VERSION "HIPBNNNYNNNNNNNNNNNNNNNNNNNNNNNNNNYYNNNNNN/4>%%%/4/'%**4NNN///"

NS_ :

BS_:

BU_: ADC CDC DDM VNC Vector_XXX

BO_ 802 AVN1SG4: 32 CDC
 SG_ TRNSW1 : 7|1@0+ (1,0) [0|0] "-"  ADC
 SG_ TRNSW2 : 6|1@0+ (1,0) [0|0] "-"  ADC
 SG_ TRNSW3 : 5|1@0+ (1,0) [0|0] "-"  ADC
 SG_ TRNSW4 : 4|1@0+ (1,0) [0|0] "-"  ADC
 SG_ TRNSW5 : 3|1@0+ (1,0) [0|0] "-"  ADC
 SG_ TRNSW6 : 2|1@0+ (1,0) [0|0] "-"  ADC
 SG_ TRNSW7 : 1|1@0+ (1,0) [0|0] "-"  ADC
 SG_ TRNSW8 : 0|1@0+ (1,0) [0|0] "-"  ADC
 SG_ TRNPASW : 15|1@0+ (1,0) [0|0] "-"  ADC
 SG_ AIPWFRP : 13|2@0+ (1,0) [0|0] "-"  ADC
 SG_ AIPFBID : 11|8@0+ (1,0) [0|0] "-"  ADC
 SG_ AIPFB : 19|3@0+ (1,0) [0|0] "-"  ADC
 SG_ AIPLID1 : 16|6@0+ (1,0) [0|0] "-"  ADC
 SG_ AIPL1 : 26|2@0+ (1,0) [0|0] "-"  ADC
 SG_ AIPLID2 : 24|6@0+ (1,0) [0|0] "-"  ADC
 SG_ AIPL2 : 34|2@0+ (1,0) [0|0] "-"  ADC
 SG_ AIPLID3 : 32|6@0+ (1,0) [0|0] "-"  ADC
 SG_ AIPL3 : 42|2@0+ (1,0) [0|0] "-"  ADC
 SG_ AIPLID4 : 40|6@0+ (1,0) [0|0] "-"  ADC
 SG_ AIPL4 : 50|2@0+ (1,0) [0|0] "-"  ADC
 SG_ AIPLID5 : 48|6@0+ (1,0) [0|0] "-"  ADC
 SG_ AIPL5 : 58|2@0+ (1,0) [0|0] "-"  ADC
 SG_ AIPLID6 : 56|6@0+ (1,0) [0|0] "-"  ADC
 SG_ AIPL6 : 66|2@0+ (1,0) [0|0] "-"  ADC
 SG_ AIPLID7 : 64|6@0+ (1,0) [0|0] "-"  ADC
 SG_ AIPL7 : 74|2@0+ (1,0) [0|0] "-"  ADC
 SG_ AIPLID8 : 72|6@0+ (1,0) [0|0] "-"  ADC
 SG_ AIPL8 : 82|2@0+ (1,0) [0|0] "-"  ADC
 SG_ AIPRLHE : 80|1@0+ (1,0) [0|0] "-"  ADC
 SG_ AIPRLAD : 95|3@0+ (1,0) [0|0] "-"  ADC
 SG_ AIPNORE : 92|3@0+ (1,0) [0|0] "-"  ADC
 SG_ TRNICN : 89|1@0+ (1,0) [0|0] "-"  ADC
 SG_ TRNECN : 88|1@0+ (1,0) [0|0] "-"  ADC

BO_ 321 AVN1SG7: 32 CDC
 SG_ BSDCTSW : 7|2@0+ (1,0) [0|0] "-"  ADC
 SG_ NPSSWOP : 5|1@0+ (1,0) [0|0] "-"  ADC
 SG_ HNPCSTSW : 4|2@0+ (1,0) [0|0] "-"  ADC
 SG_ UNPCSTSW : 2|2@0+ (1,0) [0|0] "-"  ADC
 SG_ MNPCSTSW : 0|2@0+ (1,0) [0|0] "-"  ADC
 SG_ NPLCCSSW : 14|2@0+ (1,0) [0|0] "-"  ADC
 SG_ NPCS1SW : 12|3@0+ (1,0) [0|0] "-"  ADC
 SG_ NPCS2SW : 9|2@0+ (1,0) [0|0] "-"  ADC
 SG_ NPCS3SW : 23|2@0+ (1,0) [0|0] "-"  ADC
 SG_ NPDSSWOP : 21|1@0+ (1,0) [0|0] "-"  ADC
 SG_ CPPSSWOP : 20|1@0+ (1,0) [0|0] "-"  ADC
 SG_ PNPSTRQ : 19|1@0+ (1,0) [0|0] "-"  ADC
 SG_ PNPPARQ : 18|1@0+ (1,0) [0|0] "-"  ADC
 SG_ PNPCTRQ : 17|1@0+ (1,0) [0|0] "-"  ADC
 SG_ PNPSPRQ : 16|1@0+ (1,0) [0|0] "-"  ADC
 SG_ APSW : 31|1@0+ (1,0) [0|0] "-"  ADC
 SG_ LPNPSTRQ : 30|1@0+ (1,0) [0|0] "-"  ADC
 SG_ LPNPPARQ : 29|1@0+ (1,0) [0|0] "-"  ADC
 SG_ LPNPCTRQ : 28|1@0+ (1,0) [0|0] "-"  ADC
 SG_ LPNPSPRQ : 27|1@0+ (1,0) [0|0] "-"  ADC
 SG_ OPKENBL : 26|1@0+ (1,0) [0|0] "-"  ADC
 SG_ LPLNENBL : 25|1@0+ (1,0) [0|0] "-"  ADC
 SG_ LPSPENBL : 24|1@0+ (1,0) [0|0] "-"  ADC
 SG_ PNPSENBL : 39|1@0+ (1,0) [0|0] "-"  ADC
 SG_ DIS2OBST : 38|3@0+ (1,0) [0|0] "-"  ADC
 SG_ SPDMD : 35|3@0+ (1,0) [0|0] "-"  ADC
 SG_ PKOFFSET : 32|2@0+ (1,0) [0|0] "-"  ADC
 SG_ RPAENBL : 46|2@0+ (1,0) [0|0] "-"  ADC
 SG_ PKMTHSET : 44|2@0+ (1,0) [0|0] "-"  ADC
 SG_ PKINDIR : 42|2@0+ (1,0) [0|0] "-"  ADC
 SG_ PKOSET : 40|8@0+ (1,0) [0|0] "-"  ADC
 SG_ LANGMD : 48|2@0+ (1,0) [0|0] "-"  ADC
 SG_ APENBL : 62|1@0+ (1,0) [0|0] "-"  ADC
 SG_ LPNPENBL : 61|1@0+ (1,0) [0|0] "-"  ADC
 SG_ PNPENBL : 60|1@0+ (1,0) [0|0] "-"  ADC
 SG_ APASTRQ : 59|1@0+ (1,0) [0|0] "-"  ADC
 SG_ APAPARQ : 58|1@0+ (1,0) [0|0] "-"  ADC
 SG_ APACTRQ : 57|1@0+ (1,0) [0|0] "-"  ADC
 SG_ APASPRQ : 56|1@0+ (1,0) [0|0] "-"  ADC
 SG_ RPASTRQ : 71|1@0+ (1,0) [0|0] "-"  ADC
 SG_ RPAPARQ : 70|1@0+ (1,0) [0|0] "-"  ADC
 SG_ RPACTRQ : 69|1@0+ (1,0) [0|0] "-"  ADC
 SG_ RPASPRQ : 68|1@0+ (1,0) [0|0] "-"  ADC
 SG_ APRCPMD : 67|1@0+ (1,0) [0|0] "-"  ADC
 SG_ APOUTDIR : 66|8@0+ (1,0) [0|0] "-"  ADC
 SG_ APINDIR : 74|8@0+ (1,0) [0|0] "-"  ADC
 SG_ LPBYRCP : 82|1@0+ (1,0) [0|0] "-"  ADC
 SG_ RAENBL : 81|8@0+ (1,0) [0|0] "-"  ADC
 SG_ LPINSTMD : 89|2@0+ (1,0) [0|0] "-"  ADC
 SG_ LPINRDMD : 103|1@0+ (1,0) [0|0] "-"  ADC
 SG_ LPBYPAD : 102|1@0+ (1,0) [0|0] "-"  ADC
 SG_ LPISSET : 101|1@0+ (1,0) [0|0] "-"  ADC
 SG_ LPOSSET : 100|1@0+ (1,0) [0|0] "-"  ADC
 SG_ LPENDSET : 99|1@0+ (1,0) [0|0] "-"  ADC
 SG_ LPRESET2 : 98|1@0+ (1,0) [0|0] "-"  ADC
 SG_ LPLNSTAT : 97|1@0+ (1,0) [0|0] "-"  ADC
 SG_ LPLNABT : 96|1@0+ (1,0) [0|0] "-"  ADC
 SG_ LPRTSET : 111|8@0+ (1,0) [0|0] "-"  ADC
 SG_ RASTRQ : 119|1@0+ (1,0) [0|0] "-"  ADC
 SG_ RAPARQ : 118|1@0+ (1,0) [0|0] "-"  ADC
 SG_ RACTRQ : 117|1@0+ (1,0) [0|0] "-"  ADC
 SG_ RASPRQ : 116|1@0+ (1,0) [0|0] "-"  ADC
 SG_ RASPEED : 115|2@0+ (1,0) [0|0] "-"  ADC
 SG_ WS_VISD : 113|2@0+ (1,0) [0|0] "-"  ADC
 SG_ WS_FTG : 127|2@0+ (1,0) [0|0] "-"  ADC
 SG_ WS_ABHB : 125|2@0+ (1,0) [0|0] "-"  ADC
 SG_ WS_APOS : 123|2@0+ (1,0) [0|0] "-"  ADC

BO_ 743 AVN1SG8: 32 CDC
 SG_ PSWPWC0 : 7|8@0+ (1,0) [0|0] "-"  DDM
 SG_ PSWPWC1 : 15|8@0+ (1,0) [0|0] "-"  DDM
 SG_ PSWPWC2 : 23|8@0+ (1,0) [0|0] "-"  DDM
 SG_ PSWPWC3 : 31|8@0+ (1,0) [0|0] "-"  DDM
 SG_ PSWPWC4 : 39|8@0+ (1,0) [0|0] "-"  DDM
 SG_ PSWPWC5 : 47|8@0+ (1,0) [0|0] "-"  DDM
 SG_ PSWPWC6 : 55|8@0+ (1,0) [0|0] "-"  DDM
 SG_ PSWPWC7 : 63|8@0+ (1,0) [0|0] "-"  DDM
 SG_ PSWPWC8 : 71|8@0+ (1,0) [0|0] "-"  DDM
 SG_ PSWPWC9 : 79|8@0+ (1,0) [0|0] "-"  DDM
 SG_ PSWPWC10 : 87|8@0+ (1,0) [0|0] "-"  DDM
 SG_ PSWPWC11 : 95|8@0+ (1,0) [0|0] "-"  DDM
 SG_ PSWPWC12 : 103|8@0+ (1,0) [0|0] "-"  DDM
 SG_ PSWPWC13 : 111|8@0+ (1,0) [0|0] "-"  DDM
 SG_ PSWPWC14 : 119|8@0+ (1,0) [0|0] "-"  DDM
 SG_ PSWPWC15 : 127|8@0+ (1,0) [0|0] "-"  DDM
 SG_ PSWPWC16 : 135|8@0+ (1,0) [0|0] "-"  DDM
 SG_ PSWPWC17 : 143|8@0+ (1,0) [0|0] "-"  DDM
 SG_ PSWPWC18 : 151|8@0+ (1,0) [0|0] "-"  DDM
 SG_ PSWPWC19 : 159|8@0+ (1,0) [0|0] "-"  DDM
 SG_ PSWPWC20 : 167|8@0+ (1,0) [0|0] "-"  DDM
 SG_ PSWPWC21 : 175|8@0+ (1,0) [0|0] "-"  DDM
 SG_ PSWPWC22 : 183|8@0+ (1,0) [0|0] "-"  DDM
 SG_ PSWPWC23 : 191|8@0+ (1,0) [0|0] "-"  DDM
 SG_ PSWPWC24 : 199|8@0+ (1,0) [0|0] "-"  DDM
 SG_ PSWPWC25 : 207|8@0+ (1,0) [0|0] "-"  DDM
 SG_ PSWPWC26 : 215|8@0+ (1,0) [0|0] "-"  DDM
 SG_ PSWPWC27 : 223|8@0+ (1,0) [0|0] "-"  DDM
 SG_ PSWPWC28 : 231|8@0+ (1,0) [0|0] "-"  DDM
 SG_ PSWPWC29 : 239|8@0+ (1,0) [0|0] "-"  DDM
 SG_ PSWPWC30 : 247|8@0+ (1,0) [0|0] "-"  DDM
 SG_ PSWPWC31 : 255|8@0+ (1,0) [0|0] "-"  DDM

BO_ 744 AVN1SG9: 32 CDC
 SG_ PSWPWC32 : 7|8@0+ (1,0) [0|0] "-"  DDM
 SG_ PSWPWC33 : 15|8@0+ (1,0) [0|0] "-"  DDM
 SG_ PSWPWC34 : 23|8@0+ (1,0) [0|0] "-"  DDM
 SG_ PSWPWC35 : 31|8@0+ (1,0) [0|0] "-"  DDM
 SG_ PSWPWC36 : 39|8@0+ (1,0) [0|0] "-"  DDM
 SG_ PSWPWC37 : 47|8@0+ (1,0) [0|0] "-"  DDM
 SG_ PSWPWC38 : 55|8@0+ (1,0) [0|0] "-"  DDM
 SG_ PSWPWC39 : 63|8@0+ (1,0) [0|0] "-"  DDM
 SG_ PSWPWC40 : 71|8@0+ (1,0) [0|0] "-"  DDM
 SG_ PSWPWC41 : 79|8@0+ (1,0) [0|0] "-"  DDM
 SG_ PSWPWC42 : 87|8@0+ (1,0) [0|0] "-"  DDM
 SG_ PSWPWC43 : 95|8@0+ (1,0) [0|0] "-"  DDM
 SG_ PSWPWC44 : 103|8@0+ (1,0) [0|0] "-"  DDM
 SG_ PSWPWC45 : 111|8@0+ (1,0) [0|0] "-"  DDM
 SG_ PSWPWC46 : 119|8@0+ (1,0) [0|0] "-"  DDM
 SG_ PSWPWC47 : 127|8@0+ (1,0) [0|0] "-"  DDM
 SG_ PSWPWC48 : 135|8@0+ (1,0) [0|0] "-"  DDM
 SG_ PSWPWC49 : 143|8@0+ (1,0) [0|0] "-"  DDM
 SG_ PSWPWC50 : 151|8@0+ (1,0) [0|0] "-"  DDM
 SG_ PSWPWC51 : 159|8@0+ (1,0) [0|0] "-"  DDM
 SG_ PSWPWC52 : 167|8@0+ (1,0) [0|0] "-"  DDM
 SG_ PSWPWC53 : 175|8@0+ (1,0) [0|0] "-"  DDM
 SG_ PSWPWC54 : 183|8@0+ (1,0) [0|0] "-"  DDM
 SG_ PSWPWC55 : 191|8@0+ (1,0) [0|0] "-"  DDM
 SG_ PSWPWC56 : 199|8@0+ (1,0) [0|0] "-"  DDM
 SG_ PSWPWC57 : 207|8@0+ (1,0) [0|0] "-"  DDM
 SG_ PSWPWC58 : 215|8@0+ (1,0) [0|0] "-"  DDM
 SG_ PSWPWC59 : 223|8@0+ (1,0) [0|0] "-"  DDM
 SG_ PSWPWC60 : 231|8@0+ (1,0) [0|0] "-"  DDM
 SG_ PSWPWC61 : 239|8@0+ (1,0) [0|0] "-"  DDM
 SG_ PSWPWC62 : 247|8@0+ (1,0) [0|0] "-"  DDM
 SG_ PSWPWC63 : 255|8@0+ (1,0) [0|0] "-"  DDM

BO_ 622 BAT1ED1: 32 DDM
 SG_ D_IB : 7|13@0- (0.366300366300366,0) [0|0] "A"  CDC
 SG_ D_VB : 10|13@0+ (0.1,0) [0|0] "V"  CDC
 SG_ D_VBMAX : 29|12@0+ (0.00122100122100122,0) [0|0] "V"  CDC
 SG_ D_VBMIN : 33|12@0+ (0.00122100122100122,0) [0|0] "V"  CDC
 SG_ D_VMAXN : 53|7@0+ (1,0) [0|0] "-"  CDC
 SG_ D_VMINN : 62|7@0+ (1,0) [0|0] "-"  CDC
 SG_ D_TBMAX : 71|8@0- (1,0) [0|0] "℃"  CDC
 SG_ D_TBMIN : 79|8@0- (1,0) [0|0] "℃"  CDC
 SG_ D_TBMAXN : 87|8@0+ (1,0) [0|0] "-"  CDC
 SG_ D_TBMINN : 95|8@0+ (1,0) [0|0] "-"  CDC
 SG_ D_SOC : 103|8@0+ (0.4,0) [0|0] "%"  CDC
 SG_ D_BATENE : 111|16@0+ (0.1,0) [0|0] "kWh"  CDC
 SG_ D_BERG1 : 135|8@0+ (1,0) [0|0] "-"  CDC
 SG_ D_BERG2 : 143|8@0+ (1,0) [0|0] "-"  CDC
 SG_ D_BERG3 : 151|8@0+ (1,0) [0|0] "-"  CDC
 SG_ D_BALM_1 : 159|8@0+ (1,0) [0|0] "-"  CDC
 SG_ D_BALM_2 : 167|8@0+ (1,0) [0|0] "-"  CDC
 SG_ D_BALM_3 : 175|8@0+ (1,0) [0|0] "-"  CDC
 SG_ D_BALM_4 : 183|8@0+ (1,0) [0|0] "-"  CDC
 SG_ D_BALM_5 : 191|8@0+ (1,0) [0|0] "-"  CDC
 SG_ D_BCODE1 : 199|8@0+ (1,0) [0|0] "-"  CDC
 SG_ D_BCODE2 : 207|8@0+ (1,0) [0|0] "-"  CDC
 SG_ D_BCODE3 : 215|8@0+ (1,0) [0|0] "-"  CDC
 SG_ D_BCODE4 : 223|8@0+ (1,0) [0|0] "-"  CDC
 SG_ D_BCODE5 : 231|8@0+ (1,0) [0|0] "-"  CDC
 SG_ D_BCODE6 : 239|8@0+ (1,0) [0|0] "-"  CDC
 SG_ D_BCODE7 : 247|8@0+ (1,0) [0|0] "-"  CDC
 SG_ D_BCODE8 : 255|8@0+ (1,0) [0|0] "-"  CDC

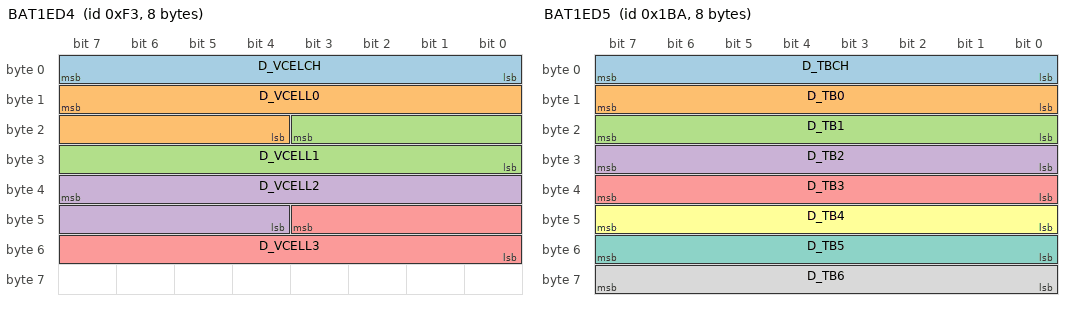
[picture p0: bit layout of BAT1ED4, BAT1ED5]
BO_ 243 BAT1ED4: 8 DDM
 SG_ D_VCELCH : 7|8@0+ (1,0) [0|0] "-"  CDC
 SG_ D_VCELL0 : 15|12@0+ (0.00122100122100122,0) [0|0] "V"  CDC
 SG_ D_VCELL1 : 19|12@0+ (0.00122100122100122,0) [0|0] "V"  CDC
 SG_ D_VCELL2 : 39|12@0+ (0.00122100122100122,0) [0|0] "V"  CDC
 SG_ D_VCELL3 : 43|12@0+ (0.00122100122100122,0) [0|0] "V"  CDC

BO_ 442 BAT1ED5: 8 DDM
 SG_ D_TBCH : 7|8@0+ (1,0) [0|0] "-"  CDC
 SG_ D_TB0 : 15|8@0- (1,0) [0|0] "℃"  CDC
 SG_ D_TB1 : 23|8@0- (1,0) [0|0] "℃"  CDC
 SG_ D_TB2 : 31|8@0- (1,0) [0|0] "℃"  CDC
 SG_ D_TB3 : 39|8@0- (1,0) [0|0] "℃"  CDC
 SG_ D_TB4 : 47|8@0- (1,0) [0|0] "℃"  CDC
 SG_ D_TB5 : 55|8@0- (1,0) [0|0] "℃"  CDC
 SG_ D_TB6 : 63|8@0- (1,0) [0|0] "℃"  CDC

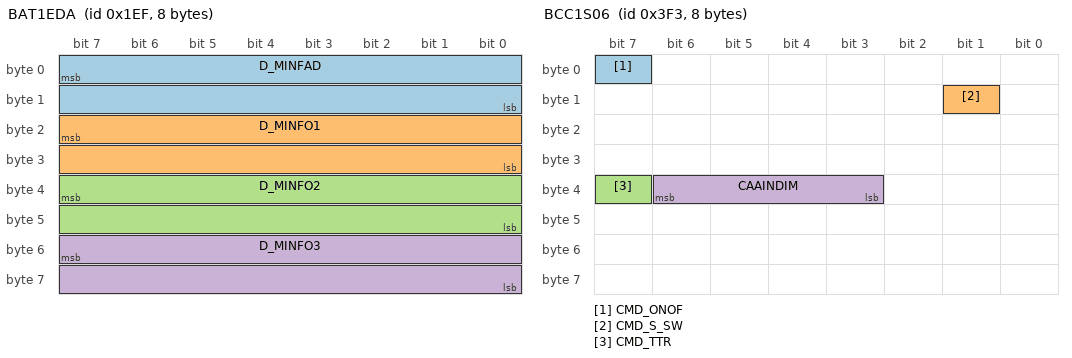
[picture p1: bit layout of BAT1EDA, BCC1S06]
BO_ 495 BAT1EDA: 8 DDM
 SG_ D_MINFAD : 7|16@0+ (1,0) [0|0] "-"  CDC
 SG_ D_MINFO1 : 23|16@0+ (1,0) [0|0] "-"  CDC
 SG_ D_MINFO2 : 39|16@0+ (1,0) [0|0] "-"  CDC
 SG_ D_MINFO3 : 55|16@0+ (1,0) [0|0] "-"  CDC

BO_ 626 BAT1EDB: 32 DDM
 SG_ D_BVIN1 : 7|8@0+ (1,0) [0|0] "-"  CDC
 SG_ D_BVIN2 : 15|8@0+ (1,0) [0|0] "-"  CDC
 SG_ D_BVIN3 : 23|8@0+ (1,0) [0|0] "-"  CDC
 SG_ D_BVIN4 : 31|8@0+ (1,0) [0|0] "-"  CDC
 SG_ D_BVIN5 : 39|8@0+ (1,0) [0|0] "-"  CDC
 SG_ D_BVIN6 : 47|8@0+ (1,0) [0|0] "-"  CDC
 SG_ D_BVIN7 : 55|8@0+ (1,0) [0|0] "-"  CDC
 SG_ D_BVIN8 : 63|8@0+ (1,0) [0|0] "-"  CDC
 SG_ D_BVIN9 : 71|8@0+ (1,0) [0|0] "-"  CDC
 SG_ D_BVIN10 : 79|8@0+ (1,0) [0|0] "-"  CDC
 SG_ D_BVIN11 : 87|8@0+ (1,0) [0|0] "-"  CDC
 SG_ D_BVIN12 : 95|8@0+ (1,0) [0|0] "-"  CDC
 SG_ D_BVIN13 : 103|8@0+ (1,0) [0|0] "-"  CDC
 SG_ D_BVIN14 : 111|8@0+ (1,0) [0|0] "-"  CDC
 SG_ D_BVIN15 : 119|8@0+ (1,0) [0|0] "-"  CDC
 SG_ D_BVIN16 : 127|8@0+ (1,0) [0|0] "-"  CDC
 SG_ D_BVIN17 : 135|8@0+ (1,0) [0|0] "-"  CDC
 SG_ D_BVIN18 : 143|8@0+ (1,0) [0|0] "-"  CDC
 SG_ D_BVIN19 : 151|8@0+ (1,0) [0|0] "-"  CDC
 SG_ D_BVIN20 : 159|8@0+ (1,0) [0|0] "-"  CDC
 SG_ D_BVIN21 : 167|8@0+ (1,0) [0|0] "-"  CDC
 SG_ D_BVIN22 : 175|8@0+ (1,0) [0|0] "-"  CDC
 SG_ D_BVIN23 : 183|8@0+ (1,0) [0|0] "-"  CDC
 SG_ D_BVIN24 : 191|8@0+ (1,0) [0|0] "-"  CDC

BO_ 633 BAT2ED2: 8 DDM
 SG_ BITGB1 : 7|1@0+ (1,0) [0|0] "-"  CDC
 SG_ BITGB2 : 6|1@0+ (1,0) [0|0] "-"  CDC
 SG_ BITGB3 : 5|1@0+ (1,0) [0|0] "-"  CDC
 SG_ BITGB4 : 4|1@0+ (1,0) [0|0] "-"  CDC
 SG_ STKNUM : 3|4@0+ (1,0) [0|0] "-"  CDC
 SG_ BITGB5 : 15|1@0+ (1,0) [0|0] "-"  CDC
 SG_ VCELNUM : 14|7@0+ (1,0) [0|0] "-"  CDC
 SG_ INFGB1 : 23|2@0+ (1,0) [0|0] "-"  CDC
 SG_ TMINNUM : 21|6@0+ (1,0) [0|0] "-"  CDC
 SG_ INFGB2 : 31|2@0+ (1,0) [0|0] "-"  CDC
 SG_ TMAXNUM : 29|6@0+ (1,0) [0|0] "-"  CDC
 SG_ VBTINF : 39|2@0+ (1,0) [0|0] "-"  CDC
 SG_ SOCINF : 37|2@0+ (1,0) [0|0] "-"  CDC
 SG_ IBTINF : 35|2@0+ (1,0) [0|0] "-"  CDC
 SG_ TBTINF : 33|2@0+ (1,0) [0|0] "-"  CDC
 SG_ STPSOC : 47|2@0+ (1,0) [0|0] "-"  CDC
 SG_ STPVB : 45|2@0+ (1,0) [0|0] "-"  CDC
 SG_ STPCELV : 43|2@0+ (1,0) [0|0] "-"  CDC
 SG_ STPTMP : 41|2@0+ (1,0) [0|0] "-"  CDC
 SG_ DATAGB2 : 55|8@0+ (1,0) [0|0] "-"  CDC
 SG_ DATAGB3 : 63|8@0+ (1,0) [0|0] "-"  CDC

BO_ 1011 BCC1S06: 8 ADC
 SG_ CMD_ONOF : 7|1@0+ (1,0) [0|0] "-"  CDC
 SG_ CMD_S_SW : 9|1@0+ (1,0) [0|0] "-"  CDC
 SG_ CMD_TTR : 39|1@0+ (1,0) [0|0] "-"  CDC
 SG_ CAAINDIM : 38|4@0+ (1,0) [0|0] "-"  CDC

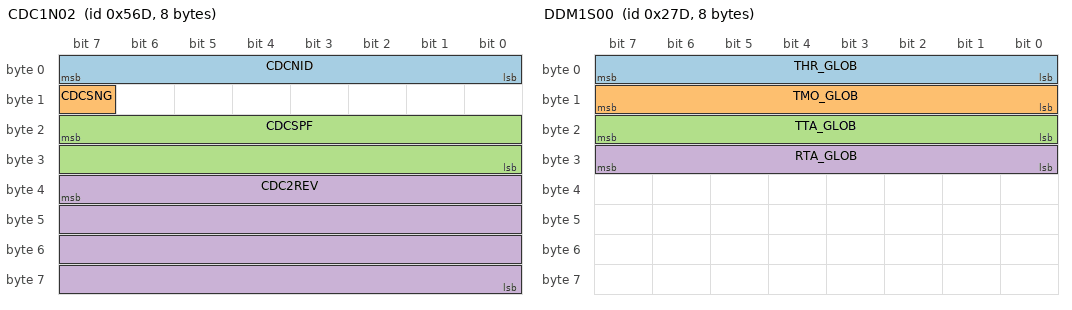
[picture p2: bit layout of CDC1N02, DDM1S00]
BO_ 1389 CDC1N02: 8 CDC
 SG_ CDCNID : 7|8@0+ (1,0) [0|0] "-"  Vector_XXX
 SG_ CDCSNG : 15|1@0+ (1,0) [0|0] "-"  Vector_XXX
 SG_ CDCSPF : 23|16@0+ (1,0) [0|0] "-"  Vector_XXX
 SG_ CDC2REV : 39|32@0+ (1,0) [0|0] "-"  Vector_XXX

BO_ 169 CSR1G10: 64 ADC
 SG_ APPMD : 31|3@0+ (1,0) [0|0] "-"  CDC
 SG_ APPEXIST : 28|1@0+ (1,0) [0|0] "-"  CDC
 SG_ APPSYS : 27|1@0+ (1,0) [0|0] "-"  CDC
 SG_ APPFAIL : 26|1@0+ (1,0) [0|0] "-"  CDC
 SG_ RCPEXBRK : 54|1@0+ (1,0) [0|0] "-"  CDC

BO_ 1082 CSR1S04: 8 ADC
 SG_ ICSEXIST : 7|1@0+ (1,0) [0|0] "-"  CDC
 SG_ ICSLAMP : 6|2@0+ (1,0) [0|0] "-"  CDC
 SG_ CS_S_SW3 : 4|1@0+ (1,0) [0|0] "-"  CDC
 SG_ CSSW : 3|1@0+ (1,0) [0|0] "-"  CDC
 SG_ ICSSW : 2|1@0+ (1,0) [0|0] "-"  CDC
 SG_ CS_V_SW3 : 1|1@0+ (1,0) [0|0] "-"  CDC
 SG_ ICS_S_SW : 0|1@0+ (1,0) [0|0] "-"  CDC
 SG_ ICSINFO : 15|16@0+ (1,0) [0|0] "-"  CDC
 SG_ WACS_BUZ : 27|1@0+ (1,0) [0|0] "-"  CDC
 SG_ WACSPMID : 24|1@0+ (1,0) [0|0] "-"  CDC
 SG_ VNUSGCSR : 32|1@0+ (1,0) [0|0] "-"  CDC
 SG_ PMARDISP : 46|2@0+ (1,0) [0|0] "-"  CDC
 SG_ PMARVNRQ : 44|2@0+ (1,0) [0|0] "-"  CDC
 SG_ PMARVNEX : 42|1@0+ (1,0) [0|0] "-"  CDC
 SG_ PMARST : 41|1@0+ (1,0) [0|0] "-"  CDC
 SG_ PMAREX : 40|1@0+ (1,0) [0|0] "-"  CDC
 SG_ VOT3 : 55|5@0+ (1,0) [0|0] "-"  CDC
 SG_ PMARAVBL : 48|1@0+ (1,0) [0|0] "-"  CDC

BO_ 987 CSR1S07: 8 ADC
 SG_ FR_POS : 7|3@0+ (1,0) [0|0] "-"  CDC
 SG_ FL_POS : 4|3@0+ (1,0) [0|0] "-"  CDC
 SG_ FR_WRN : 1|2@0+ (1,0) [0|0] "-"  CDC
 SG_ FRC_POS : 15|3@0+ (1,0) [0|0] "-"  CDC
 SG_ FLC_POS : 12|3@0+ (1,0) [0|0] "-"  CDC
 SG_ FL_WRN : 9|2@0+ (1,0) [0|0] "-"  CDC
 SG_ RR_POS : 23|3@0+ (1,0) [0|0] "-"  CDC
 SG_ RL_POS : 20|3@0+ (1,0) [0|0] "-"  CDC
 SG_ FRC_WRN : 17|2@0+ (1,0) [0|0] "-"  CDC
 SG_ RRC_POS : 31|3@0+ (1,0) [0|0] "-"  CDC
 SG_ RLC_POS : 28|3@0+ (1,0) [0|0] "-"  CDC
 SG_ FLC_WRN : 25|2@0+ (1,0) [0|0] "-"  CDC
 SG_ RR_WRN : 39|2@0+ (1,0) [0|0] "-"  CDC
 SG_ RL_WRN : 37|2@0+ (1,0) [0|0] "-"  CDC
 SG_ RRC_WRN : 35|2@0+ (1,0) [0|0] "-"  CDC
 SG_ RLC_WRN : 33|2@0+ (1,0) [0|0] "-"  CDC
 SG_ CSMUTESW : 47|2@0+ (1,0) [0|0] "-"  CDC
 SG_ CSRDISP1 : 45|1@0+ (1,0) [0|0] "-"  CDC
 SG_ CSRDISP3 : 43|1@0+ (1,0) [0|0] "-"  CDC
 SG_ CSR_VE3 : 55|1@0+ (1,0) [0|0] "-"  CDC
 SG_ CSDETSYM : 54|1@0+ (1,0) [0|0] "-"  CDC
 SG_ CSR_TTR : 59|1@0+ (1,0) [0|0] "-"  CDC
 SG_ CS_LAMP : 58|2@0+ (1,0) [0|0] "-"  CDC

BO_ 988 CSR1S08: 8 ADC
 SG_ FR_DIRT : 7|2@0+ (1,0) [0|0] "-"  CDC
 SG_ FL_DIRT : 5|2@0+ (1,0) [0|0] "-"  CDC
 SG_ FRC_DIRT : 3|2@0+ (1,0) [0|0] "-"  CDC
 SG_ FLC_DIRT : 1|2@0+ (1,0) [0|0] "-"  CDC
 SG_ RR_DIRT : 15|2@0+ (1,0) [0|0] "-"  CDC
 SG_ RL_DIRT : 13|2@0+ (1,0) [0|0] "-"  CDC
 SG_ RRC_DIRT : 11|2@0+ (1,0) [0|0] "-"  CDC
 SG_ RLC_DIRT : 9|2@0+ (1,0) [0|0] "-"  CDC
 SG_ FRS_DIRT : 23|2@0+ (1,0) [0|0] "-"  CDC
 SG_ FLS_DIRT : 21|2@0+ (1,0) [0|0] "-"  CDC
 SG_ RRS_DIRT : 19|2@0+ (1,0) [0|0] "-"  CDC
 SG_ RLS_DIRT : 17|2@0+ (1,0) [0|0] "-"  CDC
 SG_ CSR_INF1 : 31|1@0+ (1,0) [0|0] "-"  CDC
 SG_ CSR_INF2 : 30|1@0+ (1,0) [0|0] "-"  CDC
 SG_ PKSSINFO : 29|2@0+ (1,0) [0|0] "-"  CDC
 SG_ PKSS_VE : 37|1@0+ (1,0) [0|0] "-"  CDC
 SG_ RCDAVABL : 36|1@0+ (1,0) [0|0] "-"  CDC
 SG_ ICSAVABL : 35|1@0+ (1,0) [0|0] "-"  CDC
 SG_ CSRAVABL : 34|1@0+ (1,0) [0|0] "-"  CDC
 SG_ CAM_INF1 : 32|1@0+ (1,0) [0|0] "-"  CDC
 SG_ CSR_VOL : 46|3@0+ (1,0) [0|0] "-"  CDC
 SG_ CSR_BUZ : 43|4@0+ (1,0) [0|0] "-"  CDC

BO_ 637 DDM1S00: 8 DDM
 SG_ THR_GLOB : 7|8@0+ (1,-40) [0|0] "℃"  CDC
 SG_ TMO_GLOB : 15|8@0+ (1,-40) [0|0] "℃"  CDC
 SG_ TTA_GLOB : 23|8@0+ (1,-40) [0|0] "℃"  CDC
 SG_ RTA_GLOB : 31|8@0+ (1,-40) [0|0] "℃"  CDC

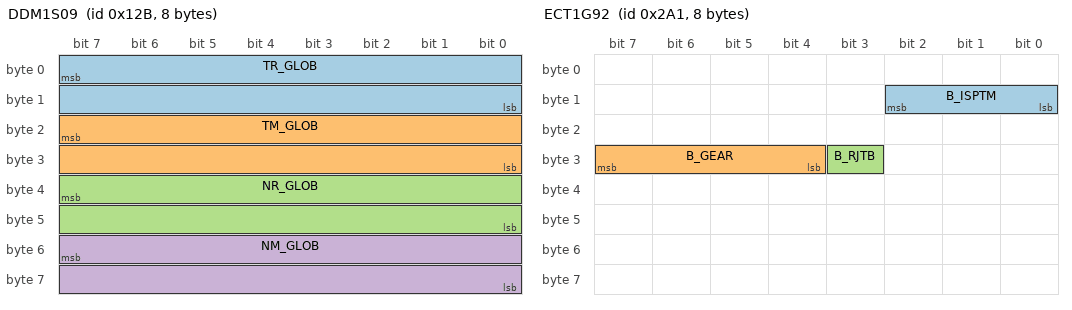
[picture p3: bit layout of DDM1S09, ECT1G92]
BO_ 299 DDM1S09: 8 DDM
 SG_ TR_GLOB : 7|16@0- (0.03125,0) [0|0] "Nm"  CDC
 SG_ TM_GLOB : 23|16@0- (0.03125,0) [0|0] "Nm"  CDC
 SG_ NR_GLOB : 39|16@0- (1,0) [0|0] "rpm"  CDC
 SG_ NM_GLOB : 55|16@0- (1,0) [0|0] "rpm"  CDC

BO_ 537 DDM1S32: 32 DDM
 SG_ C_GCMD1 : 31|5@0+ (1,0) [0|0] "-"  CDC
 SG_ C_GCMD2 : 39|5@0+ (1,0) [0|0] "-"  CDC
 SG_ C_GCMD3 : 47|5@0+ (1,0) [0|0] "-"  CDC
 SG_ C_GCMD4 : 55|5@0+ (1,0) [0|0] "-"  CDC
 SG_ C_GCMD5 : 63|5@0+ (1,0) [0|0] "-"  CDC
 SG_ C_GCMD6 : 71|5@0+ (1,0) [0|0] "-"  CDC
 SG_ C_GCMD7 : 79|5@0+ (1,0) [0|0] "-"  CDC
 SG_ C_GCMD8 : 87|5@0+ (1,0) [0|0] "-"  CDC
 SG_ GDPCEXT : 95|1@0+ (1,0) [0|0] "-"  CDC
 SG_ GDPCVLD : 94|1@0+ (1,0) [0|0] "-"  CDC
 SG_ BRKFRESH : 103|2@0+ (1,0) [0|0] "-"  CDC
 SG_ BDRSSWEX : 101|1@0+ (1,0) [0|0] "-"  CDC
 SG_ DDDBWHCN : 111|4@0+ (1,0) [0|0] "-"  CDC
 SG_ DDFRWHCN : 119|2@0+ (1,0) [0|0] "-"  CDC
 SG_ DDFLWHCN : 117|2@0+ (1,0) [0|0] "-"  CDC
 SG_ DDRRWHCN : 115|2@0+ (1,0) [0|0] "-"  CDC
 SG_ DDRLWHCN : 113|2@0+ (1,0) [0|0] "-"  CDC

BO_ 673 ECT1G92: 8 DDM
 SG_ B_ISPTM : 10|3@0+ (1,0) [0|0] "-"  CDC
 SG_ B_GEAR : 31|4@0+ (1,0) [0|0] "-"  CDC
 SG_ B_RJTB : 27|1@0+ (1,0) [0|0] "-"  CDC

BO_ 980 ECT1S80: 32 DDM
 SG_ SLCT : 14|1@0+ (1,0) [0|0] "-"  CDC

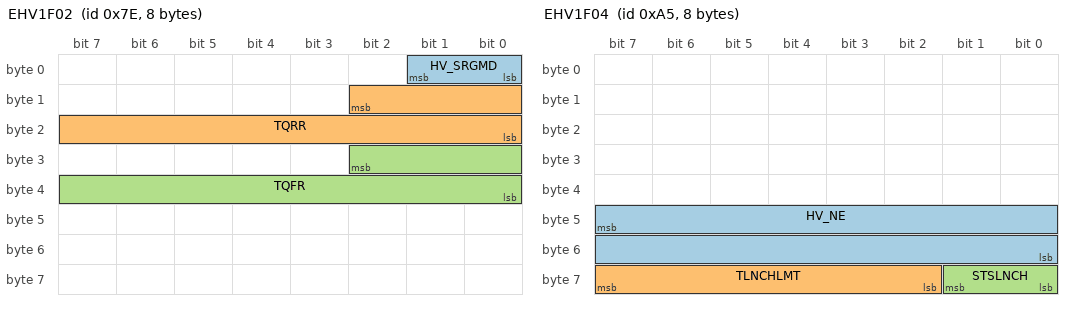
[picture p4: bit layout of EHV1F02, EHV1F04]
BO_ 126 EHV1F02: 8 DDM
 SG_ HV_SRGMD : 1|2@0+ (1,0) [0|0] "-"  CDC
 SG_ TQRR : 10|11@0- (8,0) [0|0] "Nm"  CDC
 SG_ TQFR : 26|11@0- (8,0) [0|0] "Nm"  CDC

BO_ 165 EHV1F04: 8 DDM
 SG_ HV_NE : 47|16@0- (0.78125,0) [0|0] "rpm"  CDC
 SG_ TLNCHLMT : 63|6@0+ (100,0) [0|0] "msec"  CDC
 SG_ STSLNCH : 57|2@0+ (1,0) [0|0] "-"  CDC

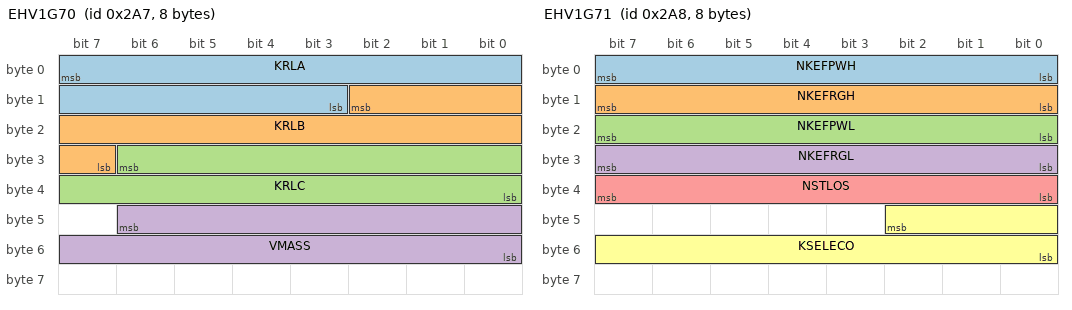
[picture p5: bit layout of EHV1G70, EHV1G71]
BO_ 679 EHV1G70: 8 DDM
 SG_ KRLA : 7|13@0+ (0.0001,0) [0|0] "N/[km/h]^2"  CDC
 SG_ KRLB : 10|12@0- (0.01,0) [0|0] "N/[km/h]"  CDC
 SG_ KRLC : 30|15@0+ (0.1,0) [0|0] "N"  CDC
 SG_ VMASS : 46|15@0+ (1,0) [0|0] "kg"  CDC

BO_ 680 EHV1G71: 8 DDM
 SG_ NKEFPWH : 7|8@0+ (1,0) [0|0] "%"  CDC
 SG_ NKEFRGH : 15|8@0+ (1,0) [0|0] "%"  CDC
 SG_ NKEFPWL : 23|8@0+ (1,0) [0|0] "%"  CDC
 SG_ NKEFRGL : 31|8@0+ (1,0) [0|0] "%"  CDC
 SG_ NSTLOS : 39|8@0+ (0.1,0) [0|0] "kw"  CDC
 SG_ KSELECO : 42|11@0+ (0.02,0) [0|0] "km/kWh"  CDC

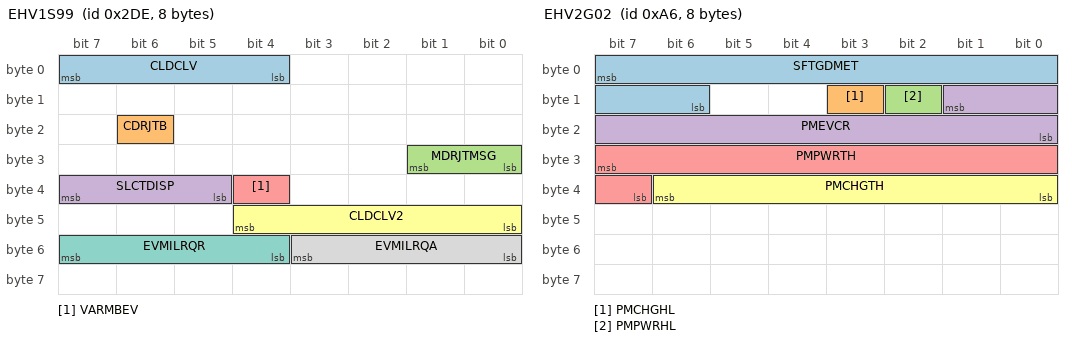
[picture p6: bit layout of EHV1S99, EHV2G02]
BO_ 734 EHV1S99: 8 DDM
 SG_ CLDCLV : 7|4@0+ (1,0) [0|0] "-"  CDC
 SG_ CDRJTB : 22|1@0+ (1,0) [0|0] "-"  CDC
 SG_ MDRJTMSG : 25|2@0+ (1,0) [0|0] "-"  CDC
 SG_ SLCTDISP : 39|3@0+ (1,0) [0|0] "-"  CDC
 SG_ VARMBEV : 36|1@0+ (1,0) [0|0] "-"  CDC
 SG_ CLDCLV2 : 44|5@0+ (1,0) [0|0] "-"  CDC
 SG_ EVMILRQR : 55|4@0+ (1,0) [0|0] "-"  CDC
 SG_ EVMILRQA : 51|4@0+ (1,0) [0|0] "-"  CDC

BO_ 166 EHV2G02: 8 DDM
 SG_ SFTGDMET : 7|10@0+ (0.1,0) [0|0] "-"  CDC
 SG_ PMCHGHL : 11|1@0+ (1,0) [0|0] "-"  CDC
 SG_ PMPWRHL : 10|1@0+ (1,0) [0|0] "-"  CDC
 SG_ PMEVCR : 9|10@0- (1,0) [0|0] "%"  CDC
 SG_ PMPWRTH : 31|9@0+ (1,0) [0|0] "%"  CDC
 SG_ PMCHGTH : 38|7@0+ (1,0) [0|0] "%"  CDC

BO_ 117 EHV2G10: 32 DDM
 SG_ SDRVRR : 26|11@0- (8,0) [0|0] "Nm"  CDC
 SG_ SDRVFR : 42|11@0- (8,0) [0|0] "Nm"  CDC

BO_ 161 EHV2G20: 32 DDM
 SG_ HVMRADRR : 39|16@0- (1,0) [0|0] "rpm"  CDC
 SG_ HVMRADFR : 55|16@0- (1,0) [0|0] "rpm"  CDC

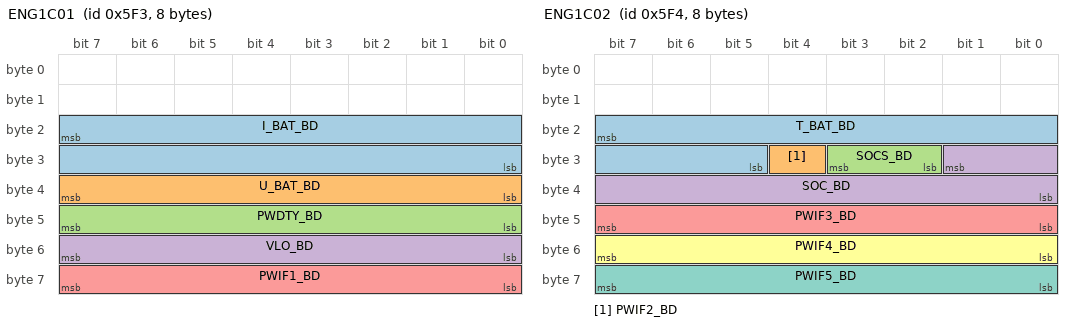
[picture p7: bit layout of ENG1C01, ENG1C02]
BO_ 1523 ENG1C01: 8 DDM
 SG_ I_BAT_BD : 23|16@0+ (0.030517578125,-1000) [0|0] "A"  CDC
 SG_ U_BAT_BD : 39|8@0+ (0.0390625,6) [0|0] "V"  CDC
 SG_ PWDTY_BD : 47|8@0+ (0.78125,0) [0|0] "%"  CDC
 SG_ VLO_BD : 55|8@0+ (0.0390625,10) [0|0] "V"  CDC
 SG_ PWIF1_BD : 63|8@0+ (1,0) [0|0] "-"  CDC

BO_ 1524 ENG1C02: 8 DDM
 SG_ T_BAT_BD : 23|11@0+ (0.1,-40) [0|0] "℃"  CDC
 SG_ PWIF2_BD : 28|1@0+ (1,0) [0|0] "-"  CDC
 SG_ SOCS_BD : 27|2@0+ (1,0) [0|0] "-"  CDC
 SG_ SOC_BD : 25|10@0+ (0.1,0) [0|0] "%"  CDC
 SG_ PWIF3_BD : 47|8@0+ (1,0) [0|0] "-"  CDC
 SG_ PWIF4_BD : 55|8@0+ (1,0) [0|0] "-"  CDC
 SG_ PWIF5_BD : 63|8@0+ (1,0) [0|0] "-"  CDC

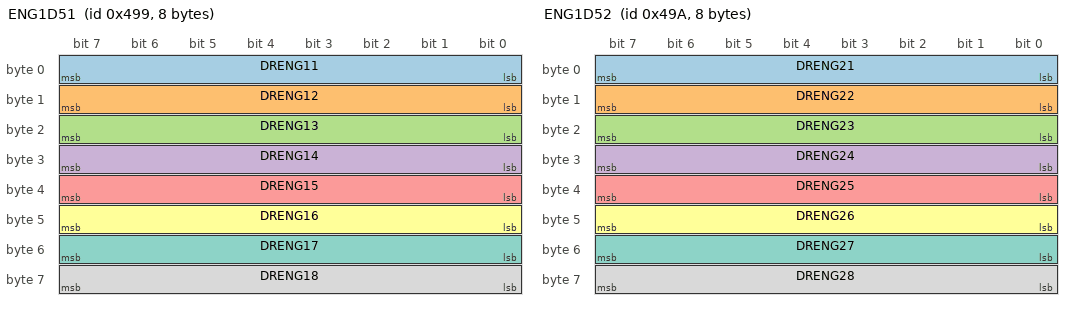
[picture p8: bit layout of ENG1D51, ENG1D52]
BO_ 1177 ENG1D51: 8 DDM
 SG_ DRENG11 : 7|8@0+ (1,0) [0|0] "-"  CDC
 SG_ DRENG12 : 15|8@0+ (1,0) [0|0] "-"  CDC
 SG_ DRENG13 : 23|8@0+ (1,0) [0|0] "-"  CDC
 SG_ DRENG14 : 31|8@0+ (1,0) [0|0] "-"  CDC
 SG_ DRENG15 : 39|8@0+ (1,0) [0|0] "-"  CDC
 SG_ DRENG16 : 47|8@0+ (1,0) [0|0] "-"  CDC
 SG_ DRENG17 : 55|8@0+ (1,0) [0|0] "-"  CDC
 SG_ DRENG18 : 63|8@0+ (1,0) [0|0] "-"  CDC

BO_ 1178 ENG1D52: 8 DDM
 SG_ DRENG21 : 7|8@0+ (1,0) [0|0] "-"  CDC
 SG_ DRENG22 : 15|8@0+ (1,0) [0|0] "-"  CDC
 SG_ DRENG23 : 23|8@0+ (1,0) [0|0] "-"  CDC
 SG_ DRENG24 : 31|8@0+ (1,0) [0|0] "-"  CDC
 SG_ DRENG25 : 39|8@0+ (1,0) [0|0] "-"  CDC
 SG_ DRENG26 : 47|8@0+ (1,0) [0|0] "-"  CDC
 SG_ DRENG27 : 55|8@0+ (1,0) [0|0] "-"  CDC
 SG_ DRENG28 : 63|8@0+ (1,0) [0|0] "-"  CDC

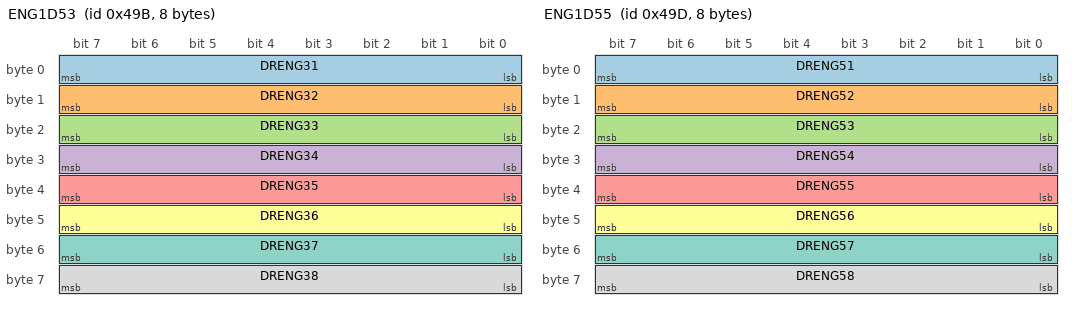
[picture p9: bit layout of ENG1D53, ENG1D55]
BO_ 1179 ENG1D53: 8 DDM
 SG_ DRENG31 : 7|8@0+ (1,0) [0|0] "-"  CDC
 SG_ DRENG32 : 15|8@0+ (1,0) [0|0] "-"  CDC
 SG_ DRENG33 : 23|8@0+ (1,0) [0|0] "-"  CDC
 SG_ DRENG34 : 31|8@0+ (1,0) [0|0] "-"  CDC
 SG_ DRENG35 : 39|8@0+ (1,0) [0|0] "-"  CDC
 SG_ DRENG36 : 47|8@0+ (1,0) [0|0] "-"  CDC
 SG_ DRENG37 : 55|8@0+ (1,0) [0|0] "-"  CDC
 SG_ DRENG38 : 63|8@0+ (1,0) [0|0] "-"  CDC

BO_ 1181 ENG1D55: 8 DDM
 SG_ DRENG51 : 7|8@0+ (1,0) [0|0] "-"  CDC
 SG_ DRENG52 : 15|8@0+ (1,0) [0|0] "-"  CDC
 SG_ DRENG53 : 23|8@0+ (1,0) [0|0] "-"  CDC
 SG_ DRENG54 : 31|8@0+ (1,0) [0|0] "-"  CDC
 SG_ DRENG55 : 39|8@0+ (1,0) [0|0] "-"  CDC
 SG_ DRENG56 : 47|8@0+ (1,0) [0|0] "-"  CDC
 SG_ DRENG57 : 55|8@0+ (1,0) [0|0] "-"  CDC
 SG_ DRENG58 : 63|8@0+ (1,0) [0|0] "-"  CDC

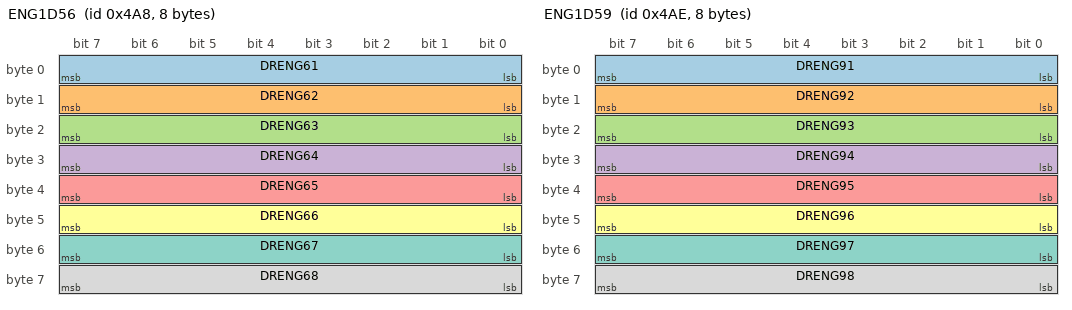
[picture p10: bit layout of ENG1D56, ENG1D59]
BO_ 1192 ENG1D56: 8 DDM
 SG_ DRENG61 : 7|8@0+ (1,0) [0|0] "-"  CDC
 SG_ DRENG62 : 15|8@0+ (1,0) [0|0] "-"  CDC
 SG_ DRENG63 : 23|8@0+ (1,0) [0|0] "-"  CDC
 SG_ DRENG64 : 31|8@0+ (1,0) [0|0] "-"  CDC
 SG_ DRENG65 : 39|8@0+ (1,0) [0|0] "-"  CDC
 SG_ DRENG66 : 47|8@0+ (1,0) [0|0] "-"  CDC
 SG_ DRENG67 : 55|8@0+ (1,0) [0|0] "-"  CDC
 SG_ DRENG68 : 63|8@0+ (1,0) [0|0] "-"  CDC

BO_ 1198 ENG1D59: 8 DDM
 SG_ DRENG91 : 7|8@0+ (1,0) [0|0] "-"  CDC
 SG_ DRENG92 : 15|8@0+ (1,0) [0|0] "-"  CDC
 SG_ DRENG93 : 23|8@0+ (1,0) [0|0] "-"  CDC
 SG_ DRENG94 : 31|8@0+ (1,0) [0|0] "-"  CDC
 SG_ DRENG95 : 39|8@0+ (1,0) [0|0] "-"  CDC
 SG_ DRENG96 : 47|8@0+ (1,0) [0|0] "-"  CDC
 SG_ DRENG97 : 55|8@0+ (1,0) [0|0] "-"  CDC
 SG_ DRENG98 : 63|8@0+ (1,0) [0|0] "-"  CDC

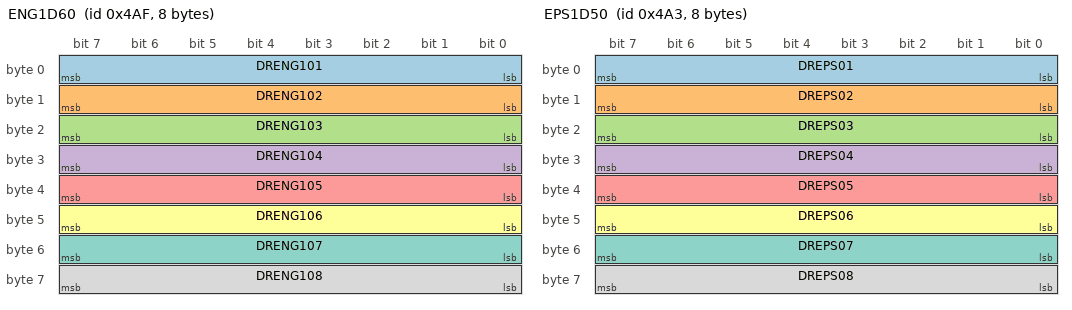
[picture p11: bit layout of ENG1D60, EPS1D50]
BO_ 1199 ENG1D60: 8 DDM
 SG_ DRENG101 : 7|8@0+ (1,0) [0|0] "-"  CDC
 SG_ DRENG102 : 15|8@0+ (1,0) [0|0] "-"  CDC
 SG_ DRENG103 : 23|8@0+ (1,0) [0|0] "-"  CDC
 SG_ DRENG104 : 31|8@0+ (1,0) [0|0] "-"  CDC
 SG_ DRENG105 : 39|8@0+ (1,0) [0|0] "-"  CDC
 SG_ DRENG106 : 47|8@0+ (1,0) [0|0] "-"  CDC
 SG_ DRENG107 : 55|8@0+ (1,0) [0|0] "-"  CDC
 SG_ DRENG108 : 63|8@0+ (1,0) [0|0] "-"  CDC

BO_ 163 ENG1G17: 8 DDM
 SG_ B_NEIND : 29|3@0+ (1,0) [0|0] "-"  CDC

BO_ 1417 ENG1S60: 32 DDM
 SG_ P_DCMOD1 : 7|1@0+ (1,0) [0|0] "-"  CDC
 SG_ P_DCMOD2 : 6|3@0+ (1,0) [0|0] "-"  CDC
 SG_ P_DCMOD3 : 3|4@0+ (1,0) [0|0] "-"  CDC
 SG_ RSCLVL : 11|2@0+ (1,0) [0|0] "-"  CDC
 SG_ P_DCMOD4 : 19|4@0+ (1,0) [0|0] "-"  CDC
 SG_ C_DCMOD1 : 31|1@0+ (1,0) [0|0] "-"  CDC
 SG_ C_DCMOD2 : 30|3@0+ (1,0) [0|0] "-"  CDC
 SG_ C_DCMOD3 : 27|4@0+ (1,0) [0|0] "-"  CDC
 SG_ C_DCMDE1 : 39|1@0+ (1,0) [0|0] "-"  CDC
 SG_ C_DCMDE2 : 38|3@0+ (1,0) [0|0] "-"  CDC
 SG_ C_DCMDE3 : 35|4@0+ (1,0) [0|0] "-"  CDC
 SG_ C_DMODEE : 47|4@0+ (1,0) [0|0] "-"  CDC
 SG_ C_DCMDS1 : 43|1@0+ (1,0) [0|0] "-"  CDC
 SG_ C_DCMDS2 : 42|3@0+ (1,0) [0|0] "-"  CDC
 SG_ C_DCMDS3 : 55|4@0+ (1,0) [0|0] "-"  CDC
 SG_ C_DMODES : 51|4@0+ (1,0) [0|0] "-"  CDC
 SG_ C_DCMDB1 : 63|1@0+ (1,0) [0|0] "-"  CDC
 SG_ C_DCMDB2 : 62|3@0+ (1,0) [0|0] "-"  CDC
 SG_ C_DCMDB3 : 59|4@0+ (1,0) [0|0] "-"  CDC
 SG_ C_DMODEB : 71|4@0+ (1,0) [0|0] "-"  CDC
 SG_ VSC_DCMD : 67|4@0+ (1,0) [0|0] "-"  CDC
 SG_ RSCEXIST : 73|1@0+ (1,0) [0|0] "-"  CDC
 SG_ DSCEXIST : 72|1@0+ (1,0) [0|0] "-"  CDC
 SG_ B_DMINF3 : 87|16@0+ (1,0) [0|0] "-"  CDC
 SG_ B_DMINF4 : 103|16@0+ (1,0) [0|0] "-"  CDC
 SG_ B_OMINF : 119|16@0+ (1,0) [0|0] "-"  CDC
 SG_ OMSSSWEX : 135|2@0+ (1,0) [0|0] "-"  CDC
 SG_ MT2SSWEX : 130|1@0+ (1,0) [0|0] "-"  CDC
 SG_ CRLSSWEX : 129|1@0+ (1,0) [0|0] "-"  CDC

BO_ 1411 ENG1S99: 8 DDM
 SG_ GRSMET_R : 0|1@0+ (1,0) [0|0] "-"  CDC

BO_ 1187 EPS1D50: 8 DDM
 SG_ DREPS01 : 7|8@0+ (1,0) [0|0] "-"  CDC
 SG_ DREPS02 : 15|8@0+ (1,0) [0|0] "-"  CDC
 SG_ DREPS03 : 23|8@0+ (1,0) [0|0] "-"  CDC
 SG_ DREPS04 : 31|8@0+ (1,0) [0|0] "-"  CDC
 SG_ DREPS05 : 39|8@0+ (1,0) [0|0] "-"  CDC
 SG_ DREPS06 : 47|8@0+ (1,0) [0|0] "-"  CDC
 SG_ DREPS07 : 55|8@0+ (1,0) [0|0] "-"  CDC
 SG_ DREPS08 : 63|8@0+ (1,0) [0|0] "-"  CDC

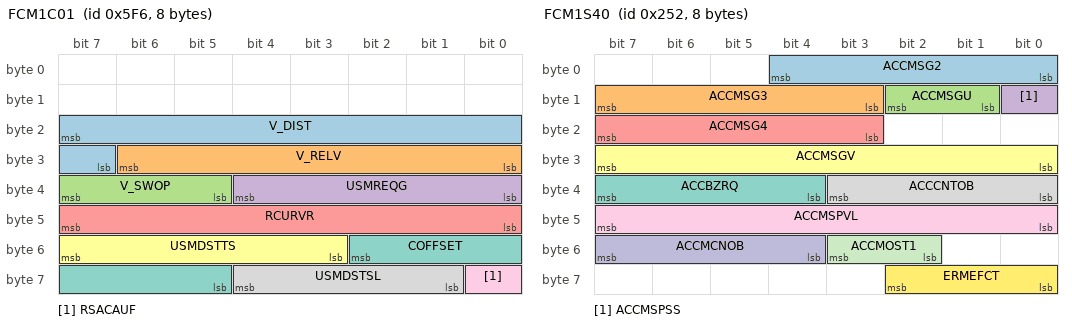
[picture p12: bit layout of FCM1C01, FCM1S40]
BO_ 1526 FCM1C01: 8 ADC
 SG_ V_DIST : 23|9@0+ (0.5,0) [0|0] "m"  CDC
 SG_ V_RELV : 30|7@0- (0.2,0) [0|0] "m/s"  CDC
 SG_ V_SWOP : 39|3@0+ (1,0) [0|0] "-"  CDC
 SG_ USMREQG : 36|5@0+ (0.1,-3.1) [0|0] "m/s^2"  CDC
 SG_ RCURVR : 47|8@0- (10,0) [0|0] "m"  CDC
 SG_ USMDSTTS : 55|5@0+ (5,0) [0|0] "m"  CDC
 SG_ COFFSET : 50|6@0- (0.03,0) [0|0] "m"  CDC
 SG_ USMDSTSL : 60|4@0+ (4,0) [0|0] "m"  CDC
 SG_ RSACAUF : 56|1@0+ (1,0) [0|0] "-"  CDC

BO_ 1521 FCM1C03: 32 ADC
 SG_ USMCNTST : 23|2@0+ (1,0) [0|0] "-"  CDC
 SG_ USMFUNC : 21|1@0+ (1,0) [0|0] "-"  CDC
 SG_ USMSENS : 20|2@0+ (1,0) [0|0] "-"  CDC
 SG_ USMACTFG : 18|1@0+ (1,0) [0|0] "-"  CDC
 SG_ USMTSTYP : 17|2@0+ (1,0) [0|0] "-"  CDC
 SG_ SGNOFFST : 31|8@0- (0.25,0) [0|0] "m"  CDC
 SG_ TSGNINF : 39|8@0+ (1,0) [0|0] "-"  CDC
 SG_ DLCAMSG : 47|4@0+ (1,0) [0|0] "-"  CDC
 SG_ RTYPE : 43|4@0+ (1,0) [0|0] "-"  CDC
 SG_ DLCAINDI : 55|3@0+ (1,0) [0|0] "-"  CDC
 SG_ RTYPERE : 52|2@0+ (1,0) [0|0] "-"  CDC
 SG_ V_BRKON : 50|1@0+ (1,0) [0|0] "-"  CDC
 SG_ RCLSINF : 63|6@0+ (1,0) [0|0] "-"  CDC
 SG_ PCSPREF2 : 57|1@0+ (1,0) [0|0] "-"  CDC
 SG_ PCSPREF1 : 56|1@0+ (1,0) [0|0] "-"  CDC
 SG_ CRU_STAT : 71|4@0+ (1,0) [0|0] "-"  CDC
 SG_ V_VMCC : 79|8@0+ (1,0) [0|0] "km/h"  CDC
 SG_ V_LTME : 84|3@0+ (1,0) [0|0] "-"  CDC
 SG_ V_LCCWOK : 81|1@0+ (1,0) [0|0] "-"  CDC
 SG_ V_XTGTCC : 80|1@0+ (1,0) [0|0] "-"  CDC
 SG_ V_RELA : 95|6@0- (0.4,0) [0|0] "m/s2"  CDC
 SG_ V_ACCUST : 89|2@0+ (1,0) [0|0] "-"  CDC
 SG_ USMTGTPV : 96|1@0+ (1,0) [0|0] "-"  CDC
 SG_ USMRCGTL : 111|3@0+ (1,0) [0|0] "-"  CDC
 SG_ V_LATPOS : 108|5@0- (0.4,0) [0|0] "m"  CDC
 SG_ V_ATACC : 119|6@0- (0.2,0) [0|0] "m/s^2"  CDC
 SG_ TSGNINF2 : 127|8@0+ (1,0) [0|0] "-"  CDC
 SG_ USMLTL : 135|1@0+ (1,0) [0|0] "-"  CDC
 SG_ USMSTL : 134|1@0+ (1,0) [0|0] "-"  CDC
 SG_ USMRTL : 133|1@0+ (1,0) [0|0] "-"  CDC
 SG_ V_IDAOPE : 132|4@0+ (1,0) [0|0] "-"  CDC
 SG_ LVNBUZDD : 138|1@0+ (1,0) [0|0] "-"  CDC
 SG_ LVNSTDD : 137|1@0+ (1,0) [0|0] "-"  CDC
 SG_ SUSUNABL : 151|8@0+ (1,0) [0|0] "-"  CDC
 SG_ APRCGSTS : 159|8@0+ (1,0) [0|0] "-"  CDC
 SG_ AP_FUNC : 164|5@0+ (1,0) [0|0] "-"  CDC
 SG_ POSX : 175|8@0- (0.1,0) [0|0] "m"  CDC
 SG_ POSZ : 183|7@0- (0.1,5) [0|0] "m"  CDC
 SG_ POSTHETA : 176|7@0- (1.5,90) [0|0] "deg"  CDC
 SG_ APSTS : 185|4@0+ (1,0) [0|0] "-"  CDC
 SG_ RODWDH : 197|6@0+ (0.2,0) [0|0] "m"  CDC
 SG_ FRNTGINF : 207|6@0+ (0.2,0) [0|0] "m"  CDC

BO_ 1161 FCM1S10: 32 ADC
 SG_ TSGN1 : 7|8@0+ (1,0) [0|0] "-"  CDC
 SG_ TSGNHLT1 : 9|2@0+ (1,0) [0|0] "-"  CDC
 SG_ SPDVAL1 : 23|8@0+ (1,0) [0|0] "-"  CDC
 SG_ SPLSGN1 : 31|4@0+ (1,0) [0|0] "-"  CDC
 SG_ SPLSGN2 : 27|4@0+ (1,0) [0|0] "-"  CDC
 SG_ TSGN2 : 39|8@0+ (1,0) [0|0] "-"  CDC
 SG_ TSGNHLT2 : 41|2@0+ (1,0) [0|0] "-"  CDC
 SG_ SPDVAL2 : 55|8@0+ (1,0) [0|0] "-"  CDC
 SG_ BZRRQ_A : 61|2@0+ (1,0) [0|0] "-"  CDC
 SG_ TSGN3 : 71|8@0+ (1,0) [0|0] "-"  CDC
 SG_ TSGNHLT3 : 73|2@0+ (1,0) [0|0] "-"  CDC
 SG_ WRNGWAYC : 87|2@0+ (1,0) [0|0] "-"  CDC
 SG_ SPLSGN3 : 95|4@0+ (1,0) [0|0] "-"  CDC
 SG_ SPLSGN4 : 91|4@0+ (1,0) [0|0] "-"  CDC
 SG_ TSGN4 : 103|8@0+ (1,0) [0|0] "-"  CDC
 SG_ SGNNUMH : 111|3@0+ (1,0) [0|0] "-"  CDC
 SG_ TSGNHLT4 : 105|2@0+ (1,0) [0|0] "-"  CDC
 SG_ SPBZRQ : 119|1@0+ (1,0) [0|0] "-"  CDC
 SG_ SGNNUMP : 117|3@0+ (1,0) [0|0] "-"  CDC
 SG_ SGNNUMA : 114|3@0+ (1,0) [0|0] "-"  CDC
 SG_ TLTASWAY : 133|2@0+ (1,0) [0|0] "-"  CDC
 SG_ TRSTINFO : 131|2@0+ (1,0) [0|0] "-"  CDC
 SG_ TLTASYST : 129|3@0+ (1,0) [0|0] "-"  CDC
 SG_ SPLSGN5 : 139|4@0+ (1,0) [0|0] "-"  CDC
 SG_ TSGNHLT5 : 151|2@0+ (1,0) [0|0] "-"  CDC
 SG_ TSGN5 : 159|8@0+ (1,0) [0|0] "-"  CDC
 SG_ CLTRLLEN : 191|4@0+ (1,0) [0|0] "-"  CDC

BO_ 1163 FCM1S12: 8 ADC
 SG_ TSREQPD : 7|1@0+ (1,0) [0|0] "-"  CDC
 SG_ TSRMSW : 6|1@0+ (1,0) [0|0] "-"  CDC
 SG_ OVSPNTM : 1|2@0+ (1,0) [0|0] "-"  CDC
 SG_ NOETYEXT : 15|1@0+ (1,0) [0|0] "-"  CDC
 SG_ NOEYNTM : 14|3@0+ (1,0) [0|0] "-"  CDC
 SG_ OVSPVALL : 11|4@0+ (1,-5) [0|0] "-"  CDC
 SG_ REDSGEXT : 23|1@0+ (1,0) [0|0] "-"  CDC
 SG_ RDSLNTM : 22|3@0+ (1,0) [0|0] "-"  CDC
 SG_ OVSPVALM : 19|4@0+ (1,-5) [0|0] "-"  CDC
 SG_ NTLVLSPD : 30|3@0+ (1,0) [0|0] "-"  CDC
 SG_ OVSPVALH : 27|4@0+ (1,-5) [0|0] "-"  CDC
 SG_ XSSPDEXT : 39|1@0+ (1,0) [0|0] "-"  CDC
 SG_ TSRSWEXT : 38|1@0+ (1,0) [0|0] "-"  CDC
 SG_ TSRSPU : 33|2@0+ (1,0) [0|0] "-"  CDC
 SG_ SPBZEXT : 44|1@0+ (1,0) [0|0] "-"  CDC
 SG_ RSACTIVE : 43|2@0+ (1,0) [0|0] "-"  CDC
 SG_ NTFLVEXT : 40|1@0+ (1,0) [0|0] "-"  CDC
 SG_ SPBZSTS : 55|1@0+ (1,0) [0|0] "-"  CDC

BO_ 594 FCM1S40: 8 ADC
 SG_ ACCMSG2 : 4|5@0+ (1,0) [0|0] "-"  CDC
 SG_ ACCMSG3 : 15|5@0+ (1,0) [0|0] "-"  CDC
 SG_ ACCMSGU : 10|2@0+ (1,0) [0|0] "-"  CDC
 SG_ ACCMSPSS : 8|1@0+ (1,0) [0|0] "-"  CDC
 SG_ ACCMSG4 : 23|5@0+ (1,0) [0|0] "-"  CDC
 SG_ ACCMSGV : 31|8@0+ (1,0) [0|0] "km/h・mph"  CDC
 SG_ ACCBZRQ : 39|4@0+ (1,0) [0|0] "-"  CDC
 SG_ ACCCNTOB : 35|4@0+ (1,0) [0|0] "-"  CDC
 SG_ ACCMSPVL : 47|8@0+ (1,0) [0|0] "-"  CDC
 SG_ ACCMCNOB : 55|4@0+ (1,0) [0|0] "-"  CDC
 SG_ ACCMOST1 : 51|2@0+ (1,0) [0|0] "-"  CDC
 SG_ ERMEFCT : 58|3@0+ (1,0) [0|0] "-"  CDC

BO_ 609 FCM1S41: 8 ADC
 SG_ ACCSSOD : 7|6@0- (1,0) [0|0] "km/h or mph"  CDC
 SG_ ISAEX : 0|1@0+ (1,0) [0|0] "-"  CDC
 SG_ ACCRACEX : 15|1@0+ (1,0) [0|0] "-"  CDC
 SG_ ACCRACD : 14|1@0+ (1,0) [0|0] "-"  CDC
 SG_ ACCROSEX : 11|1@0+ (1,0) [0|0] "-"  CDC
 SG_ ACCROSD : 10|1@0+ (1,0) [0|0] "-"  CDC
 SG_ ACCACLD : 20|2@0+ (1,0) [0|0] "-"  CDC
 SG_ ACCSPEX : 18|1@0+ (1,0) [0|0] "-"  CDC
 SG_ ACCSPD : 17|2@0+ (1,0) [0|0] "-"  CDC
 SG_ ACCRSAC : 39|1@0+ (1,0) [0|0] "-"  CDC
 SG_ ACCRSACB : 38|1@0+ (1,0) [0|0] "-"  CDC
 SG_ ACCSSAG : 37|2@0+ (1,0) [0|0] "-"  CDC
 SG_ ACCSSAGB : 35|1@0+ (1,0) [0|0] "-"  CDC
 SG_ VIDEO_OK : 34|1@0+ (1,0) [0|0] "-"  CDC
 SG_ CCSMDSTA : 33|1@0+ (1,0) [0|0] "-"  CDC
 SG_ CCSMDEXT : 32|1@0+ (1,0) [0|0] "-"  CDC
 SG_ SLSSOD : 47|6@0- (1,0) [0|0] "km/h or mph"  CDC
 SG_ SLSSOEX : 41|1@0+ (1,0) [0|0] "-"  CDC
 SG_ ERMEX : 40|1@0+ (1,0) [0|0] "-"  CDC
 SG_ ACCGCRD : 55|1@0+ (1,0) [0|0] "-"  CDC
 SG_ ACCGCREX : 54|1@0+ (1,0) [0|0] "-"  CDC
 SG_ ERMLV : 49|2@0+ (1,0) [0|0] "Lv"  CDC
 SG_ AECOEX : 63|1@0+ (1,0) [0|0] "-"  CDC
 SG_ AECOLV : 62|2@0+ (1,0) [0|0] "-"  CDC
 SG_ SLDSEX : 60|1@0+ (1,0) [0|0] "-"  CDC
 SG_ SLDSD : 59|1@0+ (1,0) [0|0] "-"  CDC
 SG_ SLSSSEX : 58|1@0+ (1,0) [0|0] "-"  CDC
 SG_ SLSSSD : 57|2@0+ (1,0) [0|0] "-"  CDC

BO_ 628 FCM1S49: 32 ADC
 SG_ OTHVW : 31|6@0+ (0.05,0) [0|0] "m"  CDC,DDM
 SG_ OTHVH : 39|7@0+ (0.05,0) [0|0] "m"  CDC,DDM
 SG_ OTHPB : 44|1@0+ (1,0) [0|0] "-"  CDC,DDM
 SG_ OTHTTC : 55|12@0+ (1,0) [0|0] "ms"  CDC,DDM
 SG_ OTHTTYP : 79|5@0+ (1,0) [0|0] "-"  CDC,DDM
 SG_ HITPOS : 116|5@0+ (1,0) [0|0] "-"  CDC,DDM
 SG_ OTHRDANG : 127|9@0- (1,0) [0|0] "deg"  CDC,DDM
 SG_ OTHOVLPC : 211|7@0+ (1,0) [0|0] "%"  CDC,DDM
 SG_ OTHRVPC : 220|11@0+ (0.1,-185) [0|0] "km/h"  CDC,DDM

BO_ 629 FCM1S51: 32 ADC
 SG_ IDADSPL : 7|4@0+ (1,0) [0|0] "-"  CDC
 SG_ IDAEXIST : 3|1@0+ (1,0) [0|0] "-"  CDC
 SG_ IDASENST : 2|2@0+ (1,0) [0|0] "-"  CDC
 SG_ IDAONST : 0|1@0+ (1,0) [0|0] "-"  CDC
 SG_ IDADSPR : 14|4@0+ (1,0) [0|0] "-"  CDC
 SG_ IDADSPC : 10|3@0+ (1,0) [0|0] "-"  CDC
 SG_ IDABUZZ : 23|2@0+ (1,0) [0|0] "-"  CDC
 SG_ IDACAN : 21|2@0+ (1,0) [0|0] "-"  CDC
 SG_ DWREQ : 37|2@0+ (1,0) [0|0] "-"  CDC
 SG_ USMDSPPV : 35|2@0+ (1,0) [0|0] "-"  CDC
 SG_ USMDSPTL : 32|3@0+ (1,0) [0|0] "-"  CDC
 SG_ USMDSPCR : 43|1@0+ (1,0) [0|0] "-"  CDC
 SG_ USMBZ : 50|3@0+ (1,0) [0|0] "-"  CDC
 SG_ USMDSPRM : 60|1@0+ (1,0) [0|0] "-"  CDC
 SG_ USMDSPTG : 71|4@0+ (1,0) [0|0] "-"  CDC

BO_ 630 FCM1S52: 8 ADC
 SG_ FCMDUST : 7|1@0+ (1,0) [0|0] "-"  CDC,DDM
 SG_ FCMTEMP : 6|1@0+ (1,0) [0|0] "-"  CDC,DDM
 SG_ FRDDUST : 5|1@0+ (1,0) [0|0] "-"  CDC,DDM
 SG_ FRDTEMP : 4|1@0+ (1,0) [0|0] "-"  CDC,DDM
 SG_ FRDTUCT : 3|1@0+ (1,0) [0|0] "-"  CDC,DDM
 SG_ TSSMALF : 2|1@0+ (1,0) [0|0] "-"  CDC,DDM
 SG_ TSSTUNA : 1|1@0+ (1,0) [0|0] "-"  CDC,DDM
 SG_ PCSAVABL : 0|1@0+ (1,0) [0|0] "-"  CDC,DDM
 SG_ ACCAVABL : 15|1@0+ (1,0) [0|0] "-"  CDC,DDM
 SG_ LTAAVABL : 14|1@0+ (1,0) [0|0] "-"  CDC,DDM
 SG_ LCAAVABL : 13|1@0+ (1,0) [0|0] "-"  CDC,DDM
 SG_ EDSSVABL : 12|1@0+ (1,0) [0|0] "-"  CDC,DDM
 SG_ RSAAVABL : 11|1@0+ (1,0) [0|0] "-"  CDC,DDM
 SG_ AHBAVABL : 10|1@0+ (1,0) [0|0] "-"  CDC,DDM
 SG_ IDAAVABL : 8|1@0+ (1,0) [0|0] "-"  CDC,DDM
 SG_ ACCERMEX : 23|1@0+ (1,0) [0|0] "-"  CDC,DDM
 SG_ TJAAVABL : 22|1@0+ (1,0) [0|0] "-"  CDC,DDM
 SG_ ERMAVABL : 21|1@0+ (1,0) [0|0] "-"  CDC,DDM
 SG_ EDSSEXST : 20|1@0+ (1,0) [0|0] "-"  CDC,DDM
 SG_ TMAVABL : 19|1@0+ (1,0) [0|0] "-"  CDC,DDM
 SG_ FCTAAVBL : 17|1@0+ (1,0) [0|0] "-"  CDC,DDM
 SG_ AHBEXIST : 16|1@0+ (1,0) [0|0] "-"  CDC,DDM
 SG_ ADU_INF3 : 29|1@0+ (1,0) [0|0] "-"  CDC,DDM
 SG_ CCAVABL : 28|1@0+ (1,0) [0|0] "-"  CDC,DDM
 SG_ CCEX : 27|1@0+ (1,0) [0|0] "-"  CDC,DDM
 SG_ ADU_INF4 : 26|1@0+ (1,0) [0|0] "-"  CDC,DDM
 SG_ ADUTUNA : 39|1@0+ (1,0) [0|0] "-"  CDC,DDM
 SG_ TMNAVABL : 38|1@0+ (1,0) [0|0] "-"  CDC,DDM
 SG_ ISAAVABL : 37|1@0+ (1,0) [0|0] "-"  CDC,DDM
 SG_ LDAAVABL : 36|1@0+ (1,0) [0|0] "-"  CDC,DDM
 SG_ USMDSE : 34|3@0+ (1,0) [0|0] "-"  CDC,DDM
 SG_ USMSW : 47|2@0+ (1,0) [0|0] "-"  CDC,DDM
 SG_ ADU_INF1 : 45|1@0+ (1,0) [0|0] "-"  CDC,DDM
 SG_ ADU_INF2 : 55|1@0+ (1,0) [0|0] "-"  CDC,DDM
 SG_ USMONST : 54|1@0+ (1,0) [0|0] "-"  CDC,DDM
 SG_ USMEXIST : 53|1@0+ (1,0) [0|0] "-"  CDC,DDM
 SG_ SDGCONT : 52|1@0+ (1,0) [0|0] "-"  CDC,DDM
 SG_ SDGONST : 51|1@0+ (1,0) [0|0] "-"  CDC,DDM
 SG_ SDGEXIST : 50|1@0+ (1,0) [0|0] "-"  CDC,DDM
 SG_ PDAONST : 49|1@0+ (1,0) [0|0] "-"  CDC,DDM
 SG_ PDAEXIST : 48|1@0+ (1,0) [0|0] "-"  CDC,DDM
 SG_ SWSAVABL : 63|1@0+ (1,0) [0|0] "-"  CDC,DDM
 SG_ DMCAVABL : 62|1@0+ (1,0) [0|0] "-"  CDC,DDM
 SG_ DMCEXIST : 61|1@0+ (1,0) [0|0] "-"  CDC,DDM
 SG_ BSDAVABL : 60|1@0+ (1,0) [0|0] "-"  CDC,DDM
 SG_ RCTAAVBL : 59|1@0+ (1,0) [0|0] "-"  CDC,DDM
 SG_ FHLAVABL : 58|1@0+ (1,0) [0|0] "-"  CDC,DDM
 SG_ SEAAVABL : 57|1@0+ (1,0) [0|0] "-"  CDC,DDM
 SG_ ADDSAVBL : 56|1@0+ (1,0) [0|0] "-"  CDC,DDM

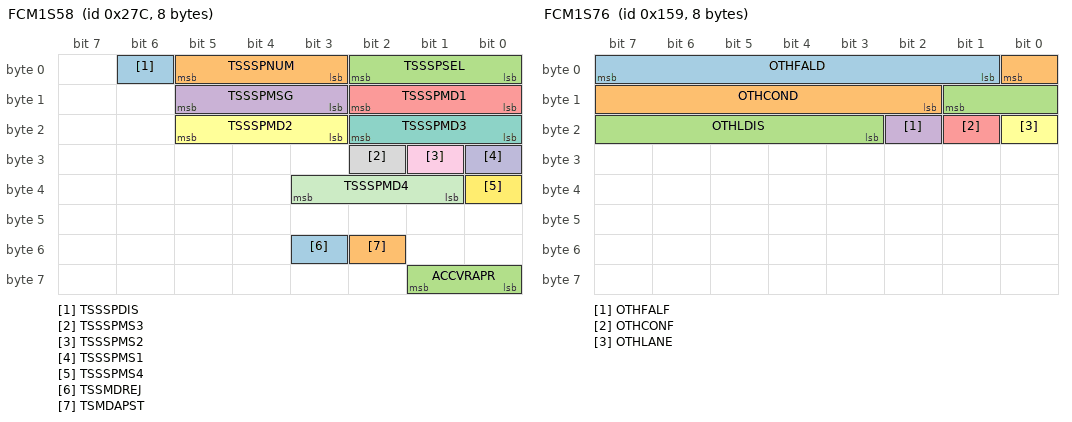
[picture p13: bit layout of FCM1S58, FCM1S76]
BO_ 636 FCM1S58: 8 ADC
 SG_ TSSSPDIS : 6|1@0+ (1,0) [0|0] "-"  CDC
 SG_ TSSSPNUM : 5|3@0+ (1,0) [0|0] "-"  CDC
 SG_ TSSSPSEL : 2|3@0+ (1,0) [0|0] "-"  CDC
 SG_ TSSSPMSG : 13|3@0+ (1,0) [0|0] "-"  CDC
 SG_ TSSSPMD1 : 10|3@0+ (1,0) [0|0] "-"  CDC
 SG_ TSSSPMD2 : 21|3@0+ (1,0) [0|0] "-"  CDC
 SG_ TSSSPMD3 : 18|3@0+ (1,0) [0|0] "-"  CDC
 SG_ TSSSPMS3 : 26|1@0+ (1,0) [0|0] "-"  CDC
 SG_ TSSSPMS2 : 25|1@0+ (1,0) [0|0] "-"  CDC
 SG_ TSSSPMS1 : 24|1@0+ (1,0) [0|0] "-"  CDC
 SG_ TSSSPMD4 : 35|3@0+ (1,0) [0|0] "-"  CDC
 SG_ TSSSPMS4 : 32|1@0+ (1,0) [0|0] "-"  CDC
 SG_ TSSMDREJ : 51|1@0+ (1,0) [0|0] "-"  CDC
 SG_ TSMDAPST : 50|1@0+ (1,0) [0|0] "-"  CDC
 SG_ ACCVRAPR : 57|2@0+ (1,0) [0|0] "-"  CDC

BO_ 650 FCM1S66: 32 ADC
 SG_ TSS_TID : 7|8@0+ (1,0) [0|0] "-"  CDC
 SG_ TSSFNC11 : 15|8@0+ (1,0) [0|0] "-"  CDC
 SG_ TSSFNC12 : 23|8@0+ (1,0) [0|0] "-"  CDC
 SG_ TSSFNC13 : 31|8@0+ (1,0) [0|0] "-"  CDC
 SG_ TSSFNC14 : 39|8@0+ (1,0) [0|0] "-"  CDC
 SG_ TSSFNC15 : 47|8@0+ (1,0) [0|0] "-"  CDC
 SG_ TSSFNC16 : 55|8@0+ (1,0) [0|0] "-"  CDC
 SG_ TSSFNC17 : 63|8@0+ (1,0) [0|0] "-"  CDC
 SG_ TSSFNC21 : 71|8@0+ (1,0) [0|0] "-"  CDC
 SG_ TSSFNC22 : 79|8@0+ (1,0) [0|0] "-"  CDC
 SG_ TSSFNC23 : 87|8@0+ (1,0) [0|0] "-"  CDC
 SG_ TSSFNC24 : 95|8@0+ (1,0) [0|0] "-"  CDC
 SG_ TSSFNC25 : 103|8@0+ (1,0) [0|0] "-"  CDC
 SG_ TSSFNC26 : 111|8@0+ (1,0) [0|0] "-"  CDC
 SG_ TSSFNC27 : 119|8@0+ (1,0) [0|0] "-"  CDC
 SG_ TSSFNC28 : 127|8@0+ (1,0) [0|0] "-"  CDC
 SG_ TSSVRRES : 135|8@0+ (1,0) [0|0] "-"  CDC
 SG_ TSSOPE11 : 143|8@0+ (1,0) [0|0] "-"  CDC
 SG_ TSSOPE12 : 151|8@0+ (1,0) [0|0] "-"  CDC
 SG_ TSSOPE13 : 159|8@0+ (1,0) [0|0] "-"  CDC
 SG_ TSSOPE14 : 167|8@0+ (1,0) [0|0] "-"  CDC
 SG_ TSSOPE15 : 175|8@0+ (1,0) [0|0] "-"  CDC
 SG_ TSSOPE16 : 183|8@0+ (1,0) [0|0] "-"  CDC
 SG_ TSSOPE17 : 191|8@0+ (1,0) [0|0] "-"  CDC
 SG_ TSSOPE21 : 199|8@0+ (1,0) [0|0] "-"  CDC
 SG_ TSSOPE22 : 207|8@0+ (1,0) [0|0] "-"  CDC
 SG_ TSSOPE23 : 215|8@0+ (1,0) [0|0] "-"  CDC
 SG_ TSSOPE24 : 223|8@0+ (1,0) [0|0] "-"  CDC
 SG_ TSSOPE25 : 231|8@0+ (1,0) [0|0] "-"  CDC
 SG_ TSSOPE26 : 239|8@0+ (1,0) [0|0] "-"  CDC
 SG_ TSSOPE27 : 247|8@0+ (1,0) [0|0] "-"  CDC
 SG_ TSSOPE28 : 255|8@0+ (1,0) [0|0] "-"  CDC

BO_ 345 FCM1S76: 8 ADC
 SG_ OTHFALD : 7|7@0+ (1,0) [0|0] "m"  CDC
 SG_ OTHCOND : 0|7@0+ (1,0) [0|0] "m"  CDC
 SG_ OTHLDIS : 9|7@0+ (1,0) [0|0] "m"  CDC
 SG_ OTHFALF : 18|1@0+ (1,0) [0|0] "-"  CDC
 SG_ OTHCONF : 17|1@0+ (1,0) [0|0] "-"  CDC
 SG_ OTHLANE : 16|1@0+ (1,0) [0|0] "-"  CDC

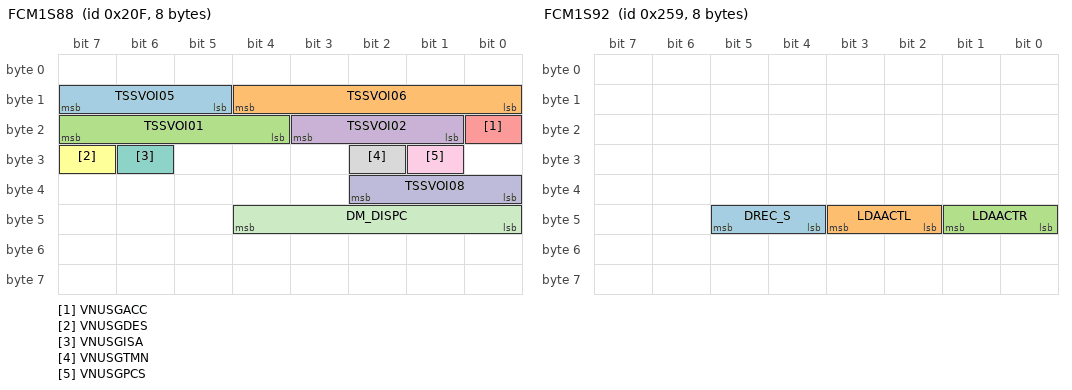
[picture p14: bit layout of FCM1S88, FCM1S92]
BO_ 527 FCM1S88: 8 ADC
 SG_ TSSVOI05 : 15|3@0+ (1,0) [0|0] "-"  CDC
 SG_ TSSVOI06 : 12|5@0+ (1,0) [0|0] "-"  CDC
 SG_ TSSVOI01 : 23|4@0+ (1,0) [0|0] "-"  CDC
 SG_ TSSVOI02 : 19|3@0+ (1,0) [0|0] "-"  CDC
 SG_ VNUSGACC : 16|1@0+ (1,0) [0|0] "-"  CDC
 SG_ VNUSGDES : 31|1@0+ (1,0) [0|0] "-"  CDC
 SG_ VNUSGISA : 30|1@0+ (1,0) [0|0] "-"  CDC
 SG_ VNUSGTMN : 26|1@0+ (1,0) [0|0] "-"  CDC
 SG_ VNUSGPCS : 25|1@0+ (1,0) [0|0] "-"  CDC
 SG_ TSSVOI08 : 34|3@0+ (1,0) [0|0] "-"  CDC
 SG_ DM_DISPC : 44|5@0+ (1,0) [0|0] "-"  CDC

BO_ 601 FCM1S92: 8 ADC
 SG_ DREC_S : 45|2@0+ (1,0) [0|0] "-"  CDC
 SG_ LDAACTL : 43|2@0+ (1,0) [0|0] "-"  CDC
 SG_ LDAACTR : 41|2@0+ (1,0) [0|0] "-"  CDC

BO_ 168 FCM1S95: 64 ADC
 SG_ AVSTRGR : 31|1@0+ (1,0) [0|0] "-"  CDC
 SG_ PBATRGR : 30|2@0+ (1,0) [0|0] "-"  CDC
 SG_ PCSALM : 38|1@0+ (1,0) [0|0] "-"  CDC,DDM

BO_ 277 FWD1S10: 8 DDM
 SG_ FWDFR_PT : 7|8@0+ (1,0) [0|0] "-"  CDC
 SG_ FWDFL_PT : 15|8@0+ (1,0) [0|0] "-"  CDC
 SG_ FWDRR_PT : 23|8@0+ (1,0) [0|0] "-"  CDC
 SG_ FWDRL_PT : 31|8@0+ (1,0) [0|0] "-"  CDC
 SG_ FWDREQ : 39|2@0+ (1,0) [0|0] "-"  CDC
 SG_ FWD_FLS : 37|2@0+ (1,0) [0|0] "-"  CDC
 SG_ FWD_FRS : 35|2@0+ (1,0) [0|0] "-"  CDC
 SG_ FWD_RLS : 33|2@0+ (1,0) [0|0] "-"  CDC
 SG_ FWD_RRS : 47|2@0+ (1,0) [0|0] "-"  CDC
 SG_ FWD_PSF : 45|2@0+ (1,0) [0|0] "-"  CDC
 SG_ FWD_PSR : 43|2@0+ (1,0) [0|0] "-"  CDC
 SG_ FWD_FTA : 41|2@0+ (1,0) [0|0] "-"  CDC
 SG_ FWD_RTA : 55|2@0+ (1,0) [0|0] "-"  CDC
 SG_ FWD_CDL : 53|2@0+ (1,0) [0|0] "-"  CDC
 SG_ PSF_DISP : 51|1@0+ (1,0) [0|0] "-"  CDC
 SG_ PSR_DISP : 50|1@0+ (1,0) [0|0] "-"  CDC
 SG_ CDL_DISP : 49|1@0+ (1,0) [0|0] "-"  CDC
 SG_ MGR_DISP : 48|1@0+ (1,0) [0|0] "-"  CDC

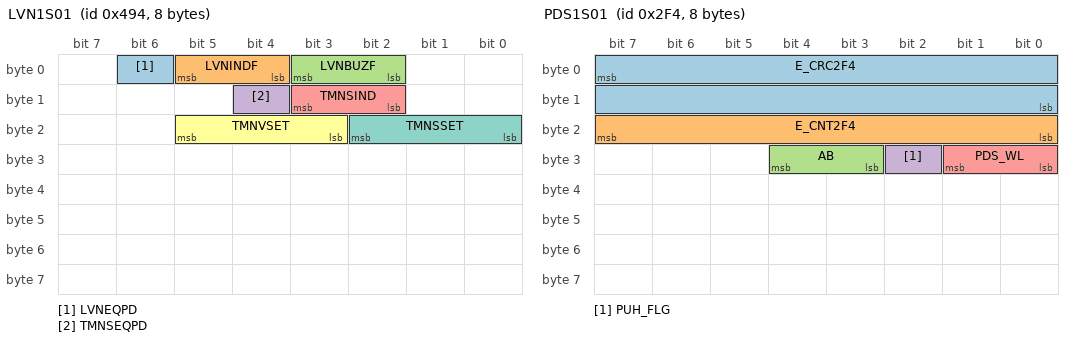
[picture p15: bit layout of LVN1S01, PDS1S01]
BO_ 1172 LVN1S01: 8 ADC
 SG_ LVNEQPD : 6|1@0+ (1,0) [0|0] "-"  CDC
 SG_ LVNINDF : 5|2@0+ (1,0) [0|0] "-"  CDC
 SG_ LVNBUZF : 3|2@0+ (1,0) [0|0] "-"  CDC
 SG_ TMNSEQPD : 12|1@0+ (1,0) [0|0] "-"  CDC
 SG_ TMNSIND : 11|2@0+ (1,0) [0|0] "-"  CDC
 SG_ TMNVSET : 21|3@0+ (1,0) [0|0] "-"  CDC
 SG_ TMNSSET : 18|3@0+ (1,0) [0|0] "-"  CDC

BO_ 1321 MET1S43: 8 CDC
 SG_ SPBZ_OPE : 63|1@0+ (1,0) [0|0] "-"  ADC

BO_ 589 MET1S44: 32 CDC
 SG_ VRAPMSWS : 21|2@0+ (1,0) [0|0] "-"  ADC
 SG_ FV24D : 175|56@0+ (1,0) [0|0] "-"  ADC
 SG_ KZK24D : 231|32@0+ (1,0) [0|0] "-"  ADC

BO_ 855 MET1S70: 32 CDC
 SG_ METSPDIS : 7|1@0+ (1,0) [0|0] "-"  ADC
 SG_ LCASGMSW : 5|1@0+ (1,0) [0|0] "-"  ADC
 SG_ LCASGAPR : 3|2@0+ (1,0) [0|0] "-"  ADC
 SG_ IDAMSW : 14|1@0+ (1,0) [0|0] "-"  ADC
 SG_ IDASESW : 13|2@0+ (1,0) [0|0] "-"  ADC
 SG_ BSD_SMSB : 10|1@0+ (1,0) [0|0] "-"  ADC
 SG_ BSD_SMSS : 9|2@0+ (1,0) [0|0] "-"  ADC
 SG_ RSR_TIM : 23|3@0+ (1,0) [0|0] "-"  ADC
 SG_ DOAM_SW : 20|1@0+ (1,0) [0|0] "-"  ADC
 SG_ PKSSVOL : 18|2@0+ (1,0) [0|0] "-"  ADC
 SG_ LDASW : 16|1@0+ (1,0) [0|0] "-"  ADC
 SG_ DOAM_TIM : 31|2@0+ (1,0) [0|0] "-"  ADC
 SG_ BSMM_ILV : 29|2@0+ (1,0) [0|0] "-"  ADC
 SG_ RTAN_TIM : 27|2@0+ (1,0) [0|0] "-"  ADC
 SG_ RTAN_MSW : 25|1@0+ (1,0) [0|0] "-"  ADC
 SG_ PLUSSW : 24|1@0+ (1,0) [0|0] "-"  ADC
 SG_ SDGMSW : 33|1@0+ (1,0) [0|0] "-"  ADC
 SG_ PDAMSW : 32|1@0+ (1,0) [0|0] "-"  ADC
 SG_ RSA_NEM : 47|3@0+ (1,0) [0|0] "-"  ADC
 SG_ RSA_LSM : 44|3@0+ (1,0) [0|0] "-"  ADC
 SG_ PMARSW : 41|1@0+ (1,0) [0|0] "-"  ADC
 SG_ ADDS_MSW : 40|1@0+ (1,0) [0|0] "-"  ADC
 SG_ LDAAMSW : 55|3@0+ (1,0) [0|0] "-"  ADC
 SG_ TMNVSW : 52|3@0+ (1,0) [0|0] "-"  ADC
 SG_ TMNSSW : 49|3@0+ (1,0) [0|0] "-"  ADC
 SG_ DM_SW_A2 : 62|3@0+ (1,0) [0|0] "-"  ADC
 SG_ DISSUISW : 59|1@0+ (1,0) [0|0] "-"  ADC
 SG_ SLDSSW : 71|1@0+ (1,0) [0|0] "-"  ADC
 SG_ SLSSSSW : 70|2@0+ (1,0) [0|0] "-"  ADC
 SG_ LTASSWOP : 65|1@0+ (1,0) [0|0] "-"  ADC
 SG_ HMIAMBOP : 64|1@0+ (1,0) [0|0] "-"  ADC
 SG_ ADINITSW : 79|1@0+ (1,0) [0|0] "-"  ADC
 SG_ ADSAFESW : 78|1@0+ (1,0) [0|0] "-"  ADC
 SG_ ADALOFSW : 77|1@0+ (1,0) [0|0] "-"  ADC
 SG_ ADMUTESW : 76|1@0+ (1,0) [0|0] "-"  ADC
 SG_ ADMDSTSW : 75|1@0+ (1,0) [0|0] "-"  ADC
 SG_ STRSWAP : 87|2@0+ (1,0) [0|0] "-"  ADC
 SG_ USMSESW : 103|3@0+ (1,0) [0|0] "-"  ADC
 SG_ SDGSESW : 100|4@0+ (1,0) [0|0] "-"  ADC
 SG_ ADADDRSW : 111|2@0+ (1,0) [0|0] "-"  ADC
 SG_ ADOTASSW : 109|2@0+ (1,0) [0|0] "-"  ADC
 SG_ ADSTMUSW : 107|2@0+ (1,0) [0|0] "-"  ADC
 SG_ ADAUNFSW : 105|2@0+ (1,0) [0|0] "-"  ADC
 SG_ ADNTLVSW : 119|2@0+ (1,0) [0|0] "-"  ADC
 SG_ ADDSLVSW : 117|2@0+ (1,0) [0|0] "-"  ADC
 SG_ ADVOCTSW : 115|2@0+ (1,0) [0|0] "-"  ADC
 SG_ ADSLDSSW : 113|2@0+ (1,0) [0|0] "-"  ADC
 SG_ ADDMCRSW : 127|2@0+ (1,0) [0|0] "-"  ADC
 SG_ ADSEGDSW : 125|2@0+ (1,0) [0|0] "-"  ADC
 SG_ ADSVSSSW : 135|2@0+ (1,0) [0|0] "-"  ADC
 SG_ ADCVVSSW : 133|4@0+ (1,0) [0|0] "-"  ADC
 SG_ AECOSWBB : 129|1@0+ (1,0) [0|0] "-"  ADC
 SG_ ACCSSOSW : 143|2@0+ (1,0) [0|0] "-"  ADC
 SG_ ACCRACSW : 141|1@0+ (1,0) [0|0] "-"  ADC
 SG_ ACCROSSW : 139|1@0+ (1,0) [0|0] "-"  ADC
 SG_ AHSACTSW : 138|1@0+ (1,0) [0|0] "-"  ADC
 SG_ AHBACTSW : 137|1@0+ (1,0) [0|0] "-"  ADC
 SG_ ACCACLSW : 151|3@0+ (1,0) [0|0] "-"  ADC
 SG_ ACCSPMSW : 148|3@0+ (1,0) [0|0] "-"  ADC
 SG_ AECOSW : 159|3@0+ (1,0) [0|0] "-"  ADC
 SG_ USMMAIN : 156|1@0+ (1,0) [0|0] "-"  ADC
 SG_ SLSSOSW : 155|2@0+ (1,0) [0|0] "-"  ADC
 SG_ METMDSEL : 167|3@0+ (1,0) [0|0] "-"  ADC
 SG_ ACCDSTSW : 163|3@0+ (1,0) [0|0] "-"  ADC
 SG_ DOTICSTS : 175|2@0+ (1,0) [0|0] "-"  ADC
 SG_ CTAMSW : 173|1@0+ (1,0) [0|0] "-"  ADC
 SG_ ACCGCRSW : 172|1@0+ (1,0) [0|0] "-"  ADC
 SG_ METMSPDI : 171|1@0+ (1,0) [0|0] "-"  ADC
 SG_ RTWMSW : 170|1@0+ (1,0) [0|0] "-"  ADC
 SG_ AHSSDESW : 183|3@0+ (1,0) [0|0] "-"  ADC
 SG_ AHSSWVSW : 180|1@0+ (1,0) [0|0] "-"  ADC
 SG_ METMDREJ : 179|1@0+ (1,0) [0|0] "-"  ADC
 SG_ CCSMDMSW : 178|1@0+ (1,0) [0|0] "-"  ADC
 SG_ ERMSW : 177|2@0+ (1,0) [0|0] "-"  ADC
 SG_ TRA_SW : 191|1@0+ (1,0) [0|0] "-"  ADC
 SG_ TRLC_YN : 190|3@0+ (1,0) [0|0] "-"  ADC

BO_ 73 MGC1F13: 32 DDM
 SG_ RTQRRLMG : 123|12@0+ (0.5,0) [0|0] "Nm"  CDC
 SG_ RTQFRLMG : 143|12@0+ (0.5,0) [0|0] "Nm"  CDC

BO_ 756 PDS1S01: 8 DDM
 SG_ E_CRC2F4 : 7|16@0+ (1,0) [0|0] "-"  CDC
 SG_ E_CNT2F4 : 23|8@0+ (1,0) [0|0] "-"  CDC
 SG_ AB : 28|2@0+ (1,0) [0|0] "-"  CDC
 SG_ PUH_FLG : 26|1@0+ (1,0) [0|0] "-"  CDC
 SG_ PDS_WL : 25|2@0+ (1,0) [0|0] "-"  CDC

BO_ 690 PWC1S41: 32 DDM
 SG_ SIDPWC0 : 7|8@0+ (1,0) [0|0] "-"  CDC
 SG_ SIDPWC1 : 15|8@0+ (1,0) [0|0] "-"  CDC
 SG_ SIDPWC2 : 23|8@0+ (1,0) [0|0] "-"  CDC
 SG_ SIDPWC3 : 31|8@0+ (1,0) [0|0] "-"  CDC
 SG_ SIDPWC4 : 39|8@0+ (1,0) [0|0] "-"  CDC
 SG_ SIDPWC5 : 47|8@0+ (1,0) [0|0] "-"  CDC
 SG_ SIDPWC6 : 55|8@0+ (1,0) [0|0] "-"  CDC
 SG_ SIDPWC7 : 63|8@0+ (1,0) [0|0] "-"  CDC
 SG_ SIDPWC8 : 71|8@0+ (1,0) [0|0] "-"  CDC
 SG_ SIDPWC9 : 79|8@0+ (1,0) [0|0] "-"  CDC
 SG_ SIDPWC10 : 87|8@0+ (1,0) [0|0] "-"  CDC
 SG_ SIDPWC11 : 95|8@0+ (1,0) [0|0] "-"  CDC
 SG_ SIDPWC12 : 103|8@0+ (1,0) [0|0] "-"  CDC
 SG_ SIDPWC13 : 111|8@0+ (1,0) [0|0] "-"  CDC
 SG_ SIDPWC14 : 119|8@0+ (1,0) [0|0] "-"  CDC
 SG_ SIDPWC15 : 127|8@0+ (1,0) [0|0] "-"  CDC
 SG_ SIDPWC16 : 135|8@0+ (1,0) [0|0] "-"  CDC
 SG_ SIDPWC17 : 143|8@0+ (1,0) [0|0] "-"  CDC
 SG_ SIDPWC18 : 151|8@0+ (1,0) [0|0] "-"  CDC
 SG_ SIDPWC19 : 159|8@0+ (1,0) [0|0] "-"  CDC
 SG_ SIDPWC20 : 167|8@0+ (1,0) [0|0] "-"  CDC
 SG_ SIDPWC21 : 175|8@0+ (1,0) [0|0] "-"  CDC
 SG_ SIDPWC22 : 183|8@0+ (1,0) [0|0] "-"  CDC
 SG_ SIDPWC23 : 191|8@0+ (1,0) [0|0] "-"  CDC
 SG_ SIDPWC24 : 199|8@0+ (1,0) [0|0] "-"  CDC
 SG_ SIDPWC25 : 207|8@0+ (1,0) [0|0] "-"  CDC
 SG_ SIDPWC26 : 215|8@0+ (1,0) [0|0] "-"  CDC
 SG_ SIDPWC27 : 223|8@0+ (1,0) [0|0] "-"  CDC
 SG_ SIDPWC28 : 231|8@0+ (1,0) [0|0] "-"  CDC
 SG_ SIDPWC29 : 239|8@0+ (1,0) [0|0] "-"  CDC
 SG_ SIDPWC30 : 247|8@0+ (1,0) [0|0] "-"  CDC
 SG_ SIDPWC31 : 255|8@0+ (1,0) [0|0] "-"  CDC

BO_ 560 RCP1S02: 8 ADC
 SG_ MV_FL : 7|2@0+ (1,0) [0|0] "-"  CDC
 SG_ MV_FR : 5|2@0+ (1,0) [0|0] "-"  CDC
 SG_ MV_RL : 3|2@0+ (1,0) [0|0] "-"  CDC
 SG_ MV_RR : 1|2@0+ (1,0) [0|0] "-"  CDC
 SG_ MV_FLS : 15|2@0+ (1,0) [0|0] "-"  CDC
 SG_ MV_FRS : 13|2@0+ (1,0) [0|0] "-"  CDC
 SG_ MV_RLS : 11|2@0+ (1,0) [0|0] "-"  CDC
 SG_ MV_RRS : 9|2@0+ (1,0) [0|0] "-"  CDC
 SG_ MV_FC : 19|2@0+ (1,0) [0|0] "-"  CDC
 SG_ MV_RC : 17|2@0+ (1,0) [0|0] "-"  CDC
 SG_ FRS_POS : 31|3@0+ (1,0) [0|0] "-"  CDC
 SG_ FLS_POS : 28|3@0+ (1,0) [0|0] "-"  CDC
 SG_ FRS_WRN : 25|2@0+ (1,0) [0|0] "-"  CDC
 SG_ RRS_POS : 39|3@0+ (1,0) [0|0] "-"  CDC
 SG_ RLS_POS : 36|3@0+ (1,0) [0|0] "-"  CDC
 SG_ FLS_WRN : 33|2@0+ (1,0) [0|0] "-"  CDC
 SG_ RRS_WRN : 47|2@0+ (1,0) [0|0] "-"  CDC
 SG_ RLS_WRN : 45|2@0+ (1,0) [0|0] "-"  CDC

BO_ 475 SBW1G02: 32 DDM
 SG_ MSG_SBWF : 7|1@0+ (1,0) [0|0] "-"  CDC
 SG_ MSG_LBAT : 6|1@0+ (1,0) [0|0] "-"  CDC
 SG_ MSG_PREQ : 5|1@0+ (1,0) [0|0] "-"  CDC
 SG_ MSG_PSWF : 4|1@0+ (1,0) [0|0] "-"  CDC
 SG_ MSG_ACTF : 3|1@0+ (1,0) [0|0] "-"  CDC
 SG_ VNHLDEN : 2|3@0+ (1,0) [0|0] "-"  CDC
 SG_ VNHLDST : 15|1@0+ (1,0) [0|0] "-"  CDC

BO_ 267 SCS1S10: 32 DDM
 SG_ FRVH : 7|8@0- (1,0) [0|0] "mm"  CDC
 SG_ FLVH : 15|8@0- (1,0) [0|0] "mm"  CDC
 SG_ RRVH : 23|8@0- (1,0) [0|0] "mm"  CDC
 SG_ RLVH : 31|8@0- (1,0) [0|0] "mm"  CDC

BO_ 766 SCS1S14: 32 DDM
 SG_ AVSEXT : 7|3@0+ (1,0) [0|0] "-"  CDC
 SG_ AVSMINF : 4|3@0+ (1,0) [0|0] "-"  CDC
 SG_ AVSNI : 1|1@0+ (1,0) [0|0] "-"  CDC
 SG_ DLR_HSID : 15|4@0+ (1,0) [0|0] "-"  CDC
 SG_ LAR_HS : 11|2@0+ (1,0) [0|0] "-"  CDC
 SG_ STBEXT : 23|1@0+ (1,0) [0|0] "-"  CDC
 SG_ STBLMP : 22|2@0+ (1,0) [0|0] "-"  CDC
 SG_ KSSMINF : 20|2@0+ (1,0) [0|0] "-"  CDC
 SG_ KSSEXT : 18|1@0+ (1,0) [0|0] "-"  CDC
 SG_ LKSS0 : 17|2@0+ (1,0) [0|0] "-"  CDC
 SG_ ASTBEXT : 31|1@0+ (1,0) [0|0] "-"  CDC
 SG_ ASTBMINF : 27|4@0+ (1,0) [0|0] "-"  CDC

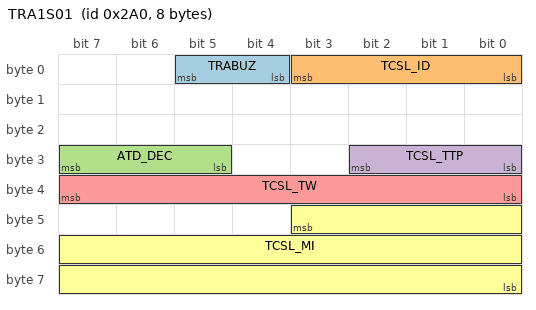
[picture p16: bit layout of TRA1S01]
BO_ 672 TRA1S01: 8 ADC
 SG_ TRABUZ : 5|2@0+ (1,0) [0|0] "-"  CDC
 SG_ TCSL_ID : 3|4@0+ (1,0) [0|0] "-"  CDC
 SG_ ATD_DEC : 31|3@0+ (1,0) [0|0] "-"  CDC
 SG_ TCSL_TTP : 26|3@0+ (1,0) [0|0] "-"  CDC
 SG_ TCSL_TW : 39|8@0+ (50,0) [0|0] "kg"  CDC
 SG_ TCSL_MI : 43|20@0+ (1,0) [0|0] "km"  CDC

BO_ 160 TRA1S02: 32 ADC
 SG_ TCDP_ID : 7|4@0+ (1,0) [0|0] "-"  CDC
 SG_ TCDP_LM : 3|2@0+ (1,0) [0|0] "-"  CDC
 SG_ TCDP_HLM : 1|2@0+ (1,0) [0|0] "-"  CDC
 SG_ TCDP_L : 15|8@0+ (50,0) [0|0] "mm"  CDC
 SG_ TCDP_HL : 23|8@0+ (50,0) [0|0] "mm"  CDC
 SG_ TCDP_WB : 31|8@0+ (50,0) [0|0] "mm"  CDC
 SG_ TCDP_HTP : 39|3@0+ (1,0) [0|0] "-"  CDC
 SG_ TCDP_NAX : 36|3@0+ (1,0) [0|0] "-"  CDC
 SG_ TCDP_WBM : 33|2@0+ (1,0) [0|0] "-"  CDC
 SG_ TCDP_W : 47|8@0+ (50,0) [0|0] "mm"  CDC
 SG_ TID_SYNC : 55|10@0+ (1,0) [0|0] "-"  CDC
 SG_ TRA_NACK : 61|1@0+ (1,0) [0|0] "-"  CDC
 SG_ TCDP_BTP : 60|3@0+ (1,0) [0|0] "-"  CDC
 SG_ TRA_GAR : 57|2@0+ (1,0) [0|0] "-"  CDC
 SG_ TCDP_WM : 71|2@0+ (1,0) [0|0] "-"  CDC
 SG_ TBC_EQ : 69|1@0+ (1,0) [0|0] "-"  CDC
 SG_ TCDP_TTP : 79|4@0+ (1,0) [0|0] "-"  CDC
 SG_ TG_VAR : 75|4@0+ (1,0) [0|0] "-"  CDC
 SG_ TCDP_TW : 167|8@0+ (50,0) [0|0] "kg"  CDC
 SG_ TCDP_TWM : 207|2@0+ (1,0) [0|0] "-"  CDC
 SG_ TCDP_MI : 203|20@0+ (1,0) [0|0] "km"  CDC

BO_ 1188 VGR1D50: 32 DDM
 SG_ DVGR01 : 7|8@0+ (1,0) [0|0] "-"  CDC
 SG_ DVGR02 : 15|8@0+ (1,0) [0|0] "-"  CDC
 SG_ DVGR03 : 23|8@0+ (1,0) [0|0] "-"  CDC
 SG_ DVGR04 : 31|8@0+ (1,0) [0|0] "-"  CDC
 SG_ DVGR05 : 39|8@0+ (1,0) [0|0] "-"  CDC
 SG_ DVGR06 : 47|8@0+ (1,0) [0|0] "-"  CDC
 SG_ DVGR07 : 55|8@0+ (1,0) [0|0] "-"  CDC
 SG_ DVGR08 : 63|8@0+ (1,0) [0|0] "-"  CDC
 SG_ DVGR09 : 71|8@0+ (1,0) [0|0] "-"  CDC
 SG_ DVGR10 : 79|8@0+ (1,0) [0|0] "-"  CDC
 SG_ DVGR11 : 87|8@0+ (1,0) [0|0] "-"  CDC
 SG_ DVGR12 : 95|8@0+ (1,0) [0|0] "-"  CDC
 SG_ DVGR13 : 103|8@0+ (1,0) [0|0] "-"  CDC
 SG_ DVGR14 : 111|8@0+ (1,0) [0|0] "-"  CDC
 SG_ DVGR15 : 119|8@0+ (1,0) [0|0] "-"  CDC
 SG_ DVGR16 : 127|8@0+ (1,0) [0|0] "-"  CDC
 SG_ DVGR17 : 135|8@0+ (1,0) [0|0] "-"  CDC
 SG_ DVGR18 : 143|8@0+ (1,0) [0|0] "-"  CDC
 SG_ DVGR19 : 151|8@0+ (1,0) [0|0] "-"  CDC
 SG_ DVGR20 : 159|8@0+ (1,0) [0|0] "-"  CDC
 SG_ DVGR21 : 167|8@0+ (1,0) [0|0] "-"  CDC
 SG_ DVGR22 : 175|8@0+ (1,0) [0|0] "-"  CDC
 SG_ DVGR23 : 183|8@0+ (1,0) [0|0] "-"  CDC
 SG_ DVGR24 : 191|8@0+ (1,0) [0|0] "-"  CDC
 SG_ DVGR25 : 199|8@0+ (1,0) [0|0] "-"  CDC
 SG_ DVGR26 : 207|8@0+ (1,0) [0|0] "-"  CDC
 SG_ DVGR27 : 215|8@0+ (1,0) [0|0] "-"  CDC
 SG_ DVGR28 : 223|8@0+ (1,0) [0|0] "-"  CDC
 SG_ DVGR29 : 231|8@0+ (1,0) [0|0] "-"  CDC
 SG_ DVGR30 : 239|8@0+ (1,0) [0|0] "-"  CDC
 SG_ DVGR31 : 247|8@0+ (1,0) [0|0] "-"  CDC
 SG_ DVGR32 : 255|8@0+ (1,0) [0|0] "-"  CDC

BO_ 1185 VSC1D51: 32 DDM
 SG_ DRVSCID : 7|8@0+ (1,0) [0|0] "-"  CDC
 SG_ DRVSC02 : 15|8@0+ (1,0) [0|0] "-"  CDC
 SG_ DRVSC03 : 23|8@0+ (1,0) [0|0] "-"  CDC
 SG_ DRVSC04 : 31|8@0+ (1,0) [0|0] "-"  CDC
 SG_ DRVSC05 : 39|8@0+ (1,0) [0|0] "-"  CDC
 SG_ DRVSC06 : 47|8@0+ (1,0) [0|0] "-"  CDC
 SG_ DRVSC07 : 55|8@0+ (1,0) [0|0] "-"  CDC
 SG_ DRVSC08 : 63|8@0+ (1,0) [0|0] "-"  CDC
 SG_ DRVSC11 : 71|8@0+ (1,0) [0|0] "-"  CDC
 SG_ DRVSC12 : 79|8@0+ (1,0) [0|0] "-"  CDC
 SG_ DRVSC13 : 87|8@0+ (1,0) [0|0] "-"  CDC
 SG_ DRVSC14 : 95|8@0+ (1,0) [0|0] "-"  CDC
 SG_ DRVSC15 : 103|8@0+ (1,0) [0|0] "-"  CDC
 SG_ DRVSC16 : 111|8@0+ (1,0) [0|0] "-"  CDC
 SG_ DRVSC17 : 119|8@0+ (1,0) [0|0] "-"  CDC
 SG_ DRVSC18 : 127|8@0+ (1,0) [0|0] "-"  CDC
 SG_ DRVSC21 : 135|8@0+ (1,0) [0|0] "-"  CDC
 SG_ DRVSC22 : 143|8@0+ (1,0) [0|0] "-"  CDC
 SG_ DRVSC23 : 151|8@0+ (1,0) [0|0] "-"  CDC
 SG_ DRVSC24 : 159|8@0+ (1,0) [0|0] "-"  CDC
 SG_ DRVSC25 : 167|8@0+ (1,0) [0|0] "-"  CDC
 SG_ DRVSC26 : 175|8@0+ (1,0) [0|0] "-"  CDC
 SG_ DRVSC27 : 183|8@0+ (1,0) [0|0] "-"  CDC
 SG_ DRVSC28 : 191|8@0+ (1,0) [0|0] "-"  CDC
 SG_ DREPB01 : 199|8@0+ (1,0) [0|0] "-"  CDC
 SG_ DREPB02 : 207|8@0+ (1,0) [0|0] "-"  CDC
 SG_ DREPB03 : 215|8@0+ (1,0) [0|0] "-"  CDC
 SG_ DREPB04 : 223|8@0+ (1,0) [0|0] "-"  CDC
 SG_ DREPB05 : 231|8@0+ (1,0) [0|0] "-"  CDC
 SG_ DREPB06 : 239|8@0+ (1,0) [0|0] "-"  CDC
 SG_ DREPB07 : 247|8@0+ (1,0) [0|0] "-"  CDC
 SG_ DREPB08 : 255|8@0+ (1,0) [0|0] "-"  CDC

BO_ 610 VSC1G96: 32 DDM
 SG_ PWIINFO : 30|1@0+ (1,0) [0|0] "-"  CDC
 SG_ RURESIS1 : 55|8@0+ (100,0) [0|0] "N"  CDC
 SG_ RURESIS2 : 63|8@0+ (10,0) [0|0] "N"  CDC
 SG_ STADJUST : 71|8@0+ (0.16,0) [0|0] "deg/s"  CDC
 SG_ FRFRICST : 119|2@0+ (1,0) [0|0] "ー"  CDC
 SG_ FLFRICST : 117|2@0+ (1,0) [0|0] "ー"  CDC
 SG_ RRFRICST : 115|2@0+ (1,0) [0|0] "ー"  CDC
 SG_ RLFRICST : 113|2@0+ (1,0) [0|0] "ー"  CDC
 SG_ DACSSWEX : 135|1@0+ (1,0) [0|0] "-"  CDC

CM_ BO_ 802 "Reserve";
CM_ SG_ 802 TRNSW1 "ADAS Training Mode Experience Scene SW press signal1";
CM_ SG_ 802 TRNSW2 "ADAS Training Mode Experience Scene SW press signal2";
CM_ SG_ 802 TRNSW3 "ADAS Training Mode Experience Scene SW press signal3";
CM_ SG_ 802 TRNSW4 "ADAS Training Mode Experience Scene SW press signal4";
CM_ SG_ 802 TRNSW5 "ADAS Training Mode Experience Scene SW press signal5";
CM_ SG_ 802 TRNSW6 "ADAS Training Mode Experience Scene SW press signal6";
CM_ SG_ 802 TRNSW7 "ADAS Training Mode Experience Scene SW press signal7";
CM_ SG_ 802 TRNSW8 "ADAS Training Mode Experience Scene SW press signal8";
CM_ SG_ 802 TRNPASW "ADAS Training Mode Pause SW press signal";
CM_ SG_ 802 AIPWFRP "AI Partner Warning Factor Response Request";
CM_ SG_ 802 AIPFBID "AI Partner Realtime Recommend Driver Answer System ID";
CM_ SG_ 802 AIPFB "AI Partner Realtime Recommend Driver Answer Result";
CM_ SG_ 802 AIPLID1 "AI Partner Realtime Recommend Driver Literacy System ID1";
CM_ SG_ 802 AIPL1 "AI Partner Realtime Recommend Driver Literacy Information1";
CM_ SG_ 802 AIPLID2 "AI Partner Realtime Recommend Driver Literacy System ID2";
CM_ SG_ 802 AIPL2 "AI Partner Realtime Recommend Driver Literacy Information2";
CM_ SG_ 802 AIPLID3 "AI Partner Realtime Recommend Driver Literacy System ID3";
CM_ SG_ 802 AIPL3 "AI Partner Realtime Recommend Driver Literacy Information3";
CM_ SG_ 802 AIPLID4 "AI Partner Realtime Recommend Driver Literacy System ID4";
CM_ SG_ 802 AIPL4 "AI Partner Realtime Recommend Driver Literacy Information4";
CM_ SG_ 802 AIPLID5 "AI Partner Realtime Recommend Driver Literacy System ID5";
CM_ SG_ 802 AIPL5 "AI Partner Realtime Recommend Driver Literacy Information5";
CM_ SG_ 802 AIPLID6 "AI Partner Realtime Recommend Driver Literacy System ID6";
CM_ SG_ 802 AIPL6 "AI Partner Realtime Recommend Driver Literacy Information6";
CM_ SG_ 802 AIPLID7 "AI Partner Realtime Recommend Driver Literacy System ID7";
CM_ SG_ 802 AIPL7 "AI Partner Realtime Recommend Driver Literacy Information7";
CM_ SG_ 802 AIPLID8 "AI Partner Realtime Recommend Driver Literacy System ID8";
CM_ SG_ 802 AIPL8 "AI Partner Realtime Recommend Driver Literacy Information8";
CM_ SG_ 802 AIPRLHE "AI Partner Route Linkage Highway Exist ";
CM_ SG_ 802 AIPRLAD "AI Partner Route Linkage ACC Recommend Driver Answer";
CM_ SG_ 802 AIPNORE "AI Partner Realtime Recommend notification result";
CM_ SG_ 802 TRNICN "ADAS Training Mode Introduction Completion Notice";
CM_ SG_ 802 TRNECN "ADAS Training Mode Ending Completion Notice";
CM_ BO_ 321 "Reserve";
CM_ SG_ 321 BSDCTSW "China BSD Customization operation FB";
CM_ SG_ 321 NPSSWOP "NP software switch operation";
CM_ SG_ 321 HNPCSTSW "Highway Navitgation Pilot Customization operation FB (Highway Navitgation Pilot)";
CM_ SG_ 321 UNPCSTSW "Urban Navigation Pilot Customization operation FB (Urban Navitgation Pilot)";
CM_ SG_ 321 MNPCSTSW "Memory Navigation Pilot Customization operation FB (MemoryNavitgation Pilot)";
CM_ SG_ 321 NPLCCSSW "Lane Change Confirmation Customization operation FB (HNP/UNP/CNP)";
CM_ SG_ 321 NPCS1SW "NP customization function 1 Customization  operation FB(HNP/UNP/CNP Nudge)";
CM_ SG_ 321 NPCS2SW "NP customization function 2 Customization  operation FB(HNP/UNP/CNP Signal Cooperative Control)";
CM_ SG_ 321 NPCS3SW "NP customization function 3 Customization  operation FB(HNP/UNP/CNP SAPA Suggestion)";
CM_ SG_ 321 NPDSSWOP "NP software down switch operation";
CM_ SG_ 321 CPPSSWOP "CNP software down switch operation";
CM_ SG_ 321 PNPSTRQ "PNP start request";
CM_ SG_ 321 PNPPARQ "PNP pause request";
CM_ SG_ 321 PNPCTRQ "PNP continue request";
CM_ SG_ 321 PNPSPRQ "PNP Stop request";
CM_ SG_ 321 APSW "AP soft switch";
CM_ SG_ 321 LPNPSTRQ "LPNP start request";
CM_ SG_ 321 LPNPPARQ "LPNP pause request";
CM_ SG_ 321 LPNPCTRQ "LPNP continue request";
CM_ SG_ 321 LPNPSPRQ "LPNP Stop request";
CM_ SG_ 321 OPKENBL "LPNPOutdoor Parking Set Requestion ";
CM_ SG_ 321 LPLNENBL "LPNP Regist Proposal Set Requestion ";
CM_ SG_ 321 LPSPENBL "LPNP Support Proposal Set Requestion ";
CM_ SG_ 321 PNPSENBL "PNP Support Proposal Set Requestion ";
CM_ SG_ 321 DIS2OBST "Distance To Obstacles Set Requestion ";
CM_ SG_ 321 SPDMD "Speed Mode Set Requestion";
CM_ SG_ 321 PKOFFSET "Park Offest Set Requestion";
CM_ SG_ 321 RPAENBL "RPA Function Set Requestion";
CM_ SG_ 321 PKMTHSET "Parking Method Set Requestion";
CM_ SG_ 321 PKINDIR "Parkin Direction Set Requestion";
CM_ SG_ 321 PKOSET "Parkout Set Requestion";
CM_ SG_ 321 LANGMD "Language Set Requestion";
CM_ SG_ 321 APENBL "APA Function Set Requestion";
CM_ SG_ 321 LPNPENBL "LPNP Function Set Requestion";
CM_ SG_ 321 PNPENBL "PNP Function Set Requestion";
CM_ SG_ 321 APASTRQ "APA start request";
CM_ SG_ 321 APAPARQ "APA pause request";
CM_ SG_ 321 APACTRQ "APA continue request";
CM_ SG_ 321 APASPRQ "APA Stop request";
CM_ SG_ 321 RPASTRQ "RPA start request";
CM_ SG_ 321 RPAPARQ "RPA pause request";
CM_ SG_ 321 RPACTRQ "RPA continue request";
CM_ SG_ 321 RPASPRQ "RPA Stop request";
CM_ SG_ 321 APRCPMD "Park Req By Mobile";
CM_ SG_ 321 APOUTDIR "parking out direct selection";
CM_ SG_ 321 APINDIR "parking in direct selection";
CM_ SG_ 321 LPBYRCP "Prking Req By Mobile";
CM_ SG_ 321 RAENBL "AP Enable Sts -> RA Enable Sts";
CM_ SG_ 321 LPINSTMD "Park in slot mode select";
CM_ SG_ 321 LPINRDMD "Start random park in mode";
CM_ SG_ 321 LPBYPAD "Using LPNP park in requests on MM";
CM_ SG_ 321 LPISSET "Set parking in start point request";
CM_ SG_ 321 LPOSSET "Set parking out start point request";
CM_ SG_ 321 LPENDSET "Set parkingout end point request";
CM_ SG_ 321 LPRESET2 "Reset LPNP route";
CM_ SG_ 321 LPLNSTAT "LPNP start to learn route";
CM_ SG_ 321 LPLNABT "LPNP learn route canceled";
CM_ SG_ 321 LPRTSET "LPNP Route Set Requestion";
CM_ SG_ 321 RASTRQ "RA start request";
CM_ SG_ 321 RAPARQ "RA pause request";
CM_ SG_ 321 RACTRQ "RA continue request";
CM_ SG_ 321 RASPRQ "RA Stop request";
CM_ SG_ 321 RASPEED "RA Speed Set Req";
CM_ SG_ 321 WS_VISD "Visual Distraction Warning Sensitivity SW Operation";
CM_ SG_ 321 WS_FTG "Fatigue Warning Sensitivity SW Operation";
CM_ SG_ 321 WS_ABHB "Abnormal Behavior Warning Sensitivity SW Operation";
CM_ SG_ 321 WS_APOS "Abnormal Driver's Posture Warning Sensitivity SW Operation";
CM_ BO_ 743 "Reserve";
CM_ SG_ 743 PSWPWC0 "WiFi password PWC No.0";
CM_ SG_ 743 PSWPWC1 "WiFi password PWC No.1";
CM_ SG_ 743 PSWPWC2 "WiFi password PWC No.2";
CM_ SG_ 743 PSWPWC3 "WiFi password PWC No.3";
CM_ SG_ 743 PSWPWC4 "WiFi password PWC No.4";
CM_ SG_ 743 PSWPWC5 "WiFi password PWC No.5";
CM_ SG_ 743 PSWPWC6 "WiFi password PWC No.6";
CM_ SG_ 743 PSWPWC7 "WiFi password PWC No.7";
CM_ SG_ 743 PSWPWC8 "WiFi password PWC No.8";
CM_ SG_ 743 PSWPWC9 "WiFi password PWC No.9";
CM_ SG_ 743 PSWPWC10 "WiFi password PWC No.10";
CM_ SG_ 743 PSWPWC11 "WiFi password PWC No.11";
CM_ SG_ 743 PSWPWC12 "WiFi password PWC No.12";
CM_ SG_ 743 PSWPWC13 "WiFi password PWC No.13";
CM_ SG_ 743 PSWPWC14 "WiFi password PWC No.14";
CM_ SG_ 743 PSWPWC15 "WiFi password PWC No.15";
CM_ SG_ 743 PSWPWC16 "WiFi password PWC No.16";
CM_ SG_ 743 PSWPWC17 "WiFi password PWC No.17";
CM_ SG_ 743 PSWPWC18 "WiFi password PWC No.18";
CM_ SG_ 743 PSWPWC19 "WiFi password PWC No.19";
CM_ SG_ 743 PSWPWC20 "WiFi password PWC No.20";
CM_ SG_ 743 PSWPWC21 "WiFi password PWC No.21";
CM_ SG_ 743 PSWPWC22 "WiFi password PWC No.22";
CM_ SG_ 743 PSWPWC23 "WiFi password PWC No.23";
CM_ SG_ 743 PSWPWC24 "WiFi password PWC No.24";
CM_ SG_ 743 PSWPWC25 "WiFi password PWC No.25";
CM_ SG_ 743 PSWPWC26 "WiFi password PWC No.26";
CM_ SG_ 743 PSWPWC27 "WiFi password PWC No.27";
CM_ SG_ 743 PSWPWC28 "WiFi password PWC No.28";
CM_ SG_ 743 PSWPWC29 "WiFi password PWC No.29";
CM_ SG_ 743 PSWPWC30 "WiFi password PWC No.30";
CM_ SG_ 743 PSWPWC31 "WiFi password PWC No.31";
CM_ BO_ 744 "Reserve";
CM_ SG_ 744 PSWPWC32 "WiFi password PWC No.32";
CM_ SG_ 744 PSWPWC33 "WiFi password PWC No.33";
CM_ SG_ 744 PSWPWC34 "WiFi password PWC No.34";
CM_ SG_ 744 PSWPWC35 "WiFi password PWC No.35";
CM_ SG_ 744 PSWPWC36 "WiFi password PWC No.36";
CM_ SG_ 744 PSWPWC37 "WiFi password PWC No.37";
CM_ SG_ 744 PSWPWC38 "WiFi password PWC No.38";
CM_ SG_ 744 PSWPWC39 "WiFi password PWC No.39";
CM_ SG_ 744 PSWPWC40 "WiFi password PWC No.40";
CM_ SG_ 744 PSWPWC41 "WiFi password PWC No.41";
CM_ SG_ 744 PSWPWC42 "WiFi password PWC No.42";
CM_ SG_ 744 PSWPWC43 "WiFi password PWC No.43";
CM_ SG_ 744 PSWPWC44 "WiFi password PWC No.44";
CM_ SG_ 744 PSWPWC45 "WiFi password PWC No.45";
CM_ SG_ 744 PSWPWC46 "WiFi password PWC No.46";
CM_ SG_ 744 PSWPWC47 "WiFi password PWC No.47";
CM_ SG_ 744 PSWPWC48 "WiFi password PWC No.48";
CM_ SG_ 744 PSWPWC49 "WiFi password PWC No.49";
CM_ SG_ 744 PSWPWC50 "WiFi password PWC No.50";
CM_ SG_ 744 PSWPWC51 "WiFi password PWC No.51";
CM_ SG_ 744 PSWPWC52 "WiFi password PWC No.52";
CM_ SG_ 744 PSWPWC53 "WiFi password PWC No.53";
CM_ SG_ 744 PSWPWC54 "WiFi password PWC No.54";
CM_ SG_ 744 PSWPWC55 "WiFi password PWC No.55";
CM_ SG_ 744 PSWPWC56 "WiFi password PWC No.56";
CM_ SG_ 744 PSWPWC57 "WiFi password PWC No.57";
CM_ SG_ 744 PSWPWC58 "WiFi password PWC No.58";
CM_ SG_ 744 PSWPWC59 "WiFi password PWC No.59";
CM_ SG_ 744 PSWPWC60 "WiFi password PWC No.60";
CM_ SG_ 744 PSWPWC61 "WiFi password PWC No.61";
CM_ SG_ 744 PSWPWC62 "WiFi password PWC No.62";
CM_ SG_ 744 PSWPWC63 "WiFi password PWC No.63";
CM_ BO_ 622 "Reserve";
CM_ SG_ 622 D_IB "[Data Monitor]D_IB";
CM_ SG_ 622 D_VB "[Data Monitor]D_VB";
CM_ SG_ 622 D_VBMAX "[Data Monitor]D_VBMAX";
CM_ SG_ 622 D_VBMIN "[Data Monitor]D_VBMIN";
CM_ SG_ 622 D_VMAXN "[Data Monitor]D_VMAXN";
CM_ SG_ 622 D_VMINN "[Data Monitor]D_VMINN";
CM_ SG_ 622 D_TBMAX "[Data Monitor]D_TBMAX";
CM_ SG_ 622 D_TBMIN "[Data Monitor]D_TBMIN";
CM_ SG_ 622 D_TBMAXN "[Data Monitor]D_TBMAXN";
CM_ SG_ 622 D_TBMINN "[Data Monitor]D_TBMINN";
CM_ SG_ 622 D_SOC "[Data Monitor]D_SOC";
CM_ SG_ 622 D_BATENE "Surplus energy of the battery";
CM_ SG_ 622 D_BERG1 "[Data Monitor]BATTERY ERROR GRADE1";
CM_ SG_ 622 D_BERG2 "[Data Monitor]BATTERY ERROR GRADE2";
CM_ SG_ 622 D_BERG3 "[Data Monitor]BATTERY ERROR GRADE3";
CM_ SG_ 622 D_BALM_1 "[Data Monitor]BATTERY ERROR ALARM1";
CM_ SG_ 622 D_BALM_2 "[Data Monitor]BATTERY ERROR ALARM2";
CM_ SG_ 622 D_BALM_3 "[Data Monitor]BATTERY ERROR ALARM3";
CM_ SG_ 622 D_BALM_4 "[Data Monitor]BATTERY ERROR ALARM4";
CM_ SG_ 622 D_BALM_5 "[Data Monitor]BATTERY ERROR ALARM5";
CM_ SG_ 622 D_BCODE1 "[Data Monitor]D_BATTERY ERROR CODE LIST1";
CM_ SG_ 622 D_BCODE2 "[Data Monitor]D_BATTERY ERROR CODE LIST2";
CM_ SG_ 622 D_BCODE3 "[Data Monitor]D_BATTERY ERROR CODE LIST3";
CM_ SG_ 622 D_BCODE4 "[Data Monitor]D_BATTERY ERROR CODE LIST4";
CM_ SG_ 622 D_BCODE5 "[Data Monitor]D_BATTERY ERROR CODE LIST5";
CM_ SG_ 622 D_BCODE6 "[Data Monitor]D_BATTERY ERROR CODE LIST6";
CM_ SG_ 622 D_BCODE7 "[Data Monitor]D_BATTERY ERROR CODE LIST7";
CM_ SG_ 622 D_BCODE8 "[Data Monitor]D_BATTERY ERROR CODE LIST8";
CM_ BO_ 243 "Reserve";
CM_ SG_ 243 D_VCELCH "[Data Monitor]D_VCELCH";
CM_ SG_ 243 D_VCELL0 "[Data Monitor]D_VCELL0";
CM_ SG_ 243 D_VCELL1 "[Data Monitor]D_VCELL1";
CM_ SG_ 243 D_VCELL2 "[Data Monitor]D_VCELL2";
CM_ SG_ 243 D_VCELL3 "[Data Monitor]D_VCELL3";
CM_ BO_ 442 "Reserve";
CM_ SG_ 442 D_TBCH "[Data Monitor]D_TBCH";
CM_ SG_ 442 D_TB0 "[Data Monitor]D_TB0";
CM_ SG_ 442 D_TB1 "[Data Monitor]D_TB1";
CM_ SG_ 442 D_TB2 "[Data Monitor]D_TB2";
CM_ SG_ 442 D_TB3 "[Data Monitor]D_TB3";
CM_ SG_ 442 D_TB4 "[Data Monitor]D_TB4";
CM_ SG_ 442 D_TB5 "[Data Monitor]D_TB5";
CM_ SG_ 442 D_TB6 "[Data Monitor]D_TB6";
CM_ BO_ 495 "Reserve";
CM_ SG_ 495 D_MINFAD "[Data Monitor]D_MINFAD";
CM_ SG_ 495 D_MINFO1 "[Data Monitor]D_MINFO1";
CM_ SG_ 495 D_MINFO2 "[Data Monitor]D_MINFO2";
CM_ SG_ 495 D_MINFO3 "[Data Monitor]D_MINFO3";
CM_ BO_ 626 "Reserve";
CM_ SG_ 626 D_BVIN1 "[Data Monitor]D_BVIN1";
CM_ SG_ 626 D_BVIN2 "[Data Monitor]D_BVIN2";
CM_ SG_ 626 D_BVIN3 "[Data Monitor]D_BVIN3";
CM_ SG_ 626 D_BVIN4 "[Data Monitor]D_BVIN4";
CM_ SG_ 626 D_BVIN5 "[Data Monitor]D_BVIN5";
CM_ SG_ 626 D_BVIN6 "[Data Monitor]D_BVIN6";
CM_ SG_ 626 D_BVIN7 "[Data Monitor]D_BVIN7";
CM_ SG_ 626 D_BVIN8 "[Data Monitor]D_BVIN8";
CM_ SG_ 626 D_BVIN9 "[Data Monitor]D_BVIN9";
CM_ SG_ 626 D_BVIN10 "[Data Monitor]D_BVIN10";
CM_ SG_ 626 D_BVIN11 "[Data Monitor]D_BVIN11";
CM_ SG_ 626 D_BVIN12 "[Data Monitor]D_BVIN12";
CM_ SG_ 626 D_BVIN13 "[Data Monitor]D_BVIN13";
CM_ SG_ 626 D_BVIN14 "[Data Monitor]D_BVIN14";
CM_ SG_ 626 D_BVIN15 "[Data Monitor]D_BVIN15";
CM_ SG_ 626 D_BVIN16 "[Data Monitor]D_BVIN16";
CM_ SG_ 626 D_BVIN17 "[Data Monitor]D_BVIN17";
CM_ SG_ 626 D_BVIN18 "[Data Monitor]D_BVIN18";
CM_ SG_ 626 D_BVIN19 "[Data Monitor]D_BVIN19";
CM_ SG_ 626 D_BVIN20 "[Data Monitor]D_BVIN20";
CM_ SG_ 626 D_BVIN21 "[Data Monitor]D_BVIN21";
CM_ SG_ 626 D_BVIN22 "[Data Monitor]D_BVIN22";
CM_ SG_ 626 D_BVIN23 "[Data Monitor]D_BVIN23";
CM_ SG_ 626 D_BVIN24 "[Data Monitor]D_BVIN24";
CM_ BO_ 633 "Reserve";
CM_ SG_ 633 BITGB1 "GB/T reserve flag 1";
CM_ SG_ 633 BITGB2 "GB/T reserve flag 2";
CM_ SG_ 633 BITGB3 "GB/T reserve flag 3";
CM_ SG_ 633 BITGB4 "GB/T reserve flag 4";
CM_ SG_ 633 STKNUM "Stack number";
CM_ SG_ 633 BITGB5 "GB/T reserve flag 5";
CM_ SG_ 633 VCELNUM "Cell voltage number";
CM_ SG_ 633 INFGB1 "GB/T reserve info1";
CM_ SG_ 633 TMINNUM "Minimum temperature thermistor number";
CM_ SG_ 633 INFGB2 "GB/T reserve info2";
CM_ SG_ 633 TMAXNUM "Maximum temperature thermistor number";
CM_ SG_ 633 VBTINF "Battery voltage information";
CM_ SG_ 633 SOCINF "SOC informaition";
CM_ SG_ 633 IBTINF "Battery electric current information";
CM_ SG_ 633 TBTINF "Battery temperature information";
CM_ SG_ 633 STPSOC "charging stop SOC status";
CM_ SG_ 633 STPVB "charging stop battery voltage status";
CM_ SG_ 633 STPCELV "charging stop battery cell voltage status";
CM_ SG_ 633 STPTMP "charging stop battery temperature status";
CM_ SG_ 633 DATAGB2 "GB/T reserve data 1";
CM_ SG_ 633 DATAGB3 "GB/T reserve data 2";
CM_ BO_ 1011 "Reserve";
CM_ SG_ 1011 CMD_ONOF "Camera detection function ON/OFF";
CM_ SG_ 1011 CMD_S_SW "Rear Camera Detection SW Display Request";
CM_ SG_ 1011 CMD_TTR "Rear Camera Detection OFF Indicator Request";
CM_ SG_ 1011 CAAINDIM "RCD message for representative indicator";
CM_ BO_ 1389 "Reserve";
CM_ SG_ 1389 CDCNID "CDC Node ID";
CM_ SG_ 1389 CDCSNG "CDC SLNG Flag";
CM_ SG_ 1389 CDCSPF "CDC Node Spec No";
CM_ SG_ 1389 CDC2REV "[RESERVE]";
CM_ BO_ 169 "Reserve";
CM_ SG_ 169 APPMD "APP Control Status";
CM_ SG_ 169 APPEXIST "APP existence flag";
CM_ SG_ 169 APPSYS "APP system validation";
CM_ SG_ 169 APPFAIL "APP error status";
CM_ SG_ 169 RCPEXBRK "RCP existence flag for Brake";
CM_ BO_ 1082 "Reserve";
CM_ SG_ 1082 ICSEXIST "ICS existence flag";
CM_ SG_ 1082 ICSLAMP "ICS-off Lamp Request";
CM_ SG_ 1082 CS_S_SW3 "CSR SWITCH DISPLAY REQUEST";
CM_ SG_ 1082 CSSW "CSR SW STATUS";
CM_ SG_ 1082 ICSSW "ICS switch state";
CM_ SG_ 1082 CS_V_SW3 "CSR BUZZER VOLUME SWITCH DISPLAY REQUEST";
CM_ SG_ 1082 ICS_S_SW "ICS Soft Switch request";
CM_ SG_ 1082 ICSINFO "ICS Multi Information";
CM_ SG_ 1082 WACS_BUZ "WACS buzzer request";
CM_ SG_ 1082 WACSPMID "WACS PLUS SUPPORT MID display request";
CM_ SG_ 1082 VNUSGCSR "Voice Nortification Usage(CSR)";
CM_ SG_ 1082 PMARDISP "PMAR DISPLAY REQUEST";
CM_ SG_ 1082 PMARVNRQ "PMAR VOICE NOTIFICATION REQUEST";
CM_ SG_ 1082 PMARVNEX "PMAR VOICE NOTIFICATION EXIST";
CM_ SG_ 1082 PMARST "PMAR SWITCH STATUS";
CM_ SG_ 1082 PMAREX "PMAR EXIST";
CM_ SG_ 1082 VOT3 "VOICE ALERT TIMING3";
CM_ SG_ 1082 PMARAVBL "PMAR usability judgement flag";
CM_ BO_ 987 "Reserve";
CM_ SG_ 987 FR_POS "FRONT RIGHT DETECTION POSITION";
CM_ SG_ 987 FL_POS "FRONT LEFT DETECTION POSITION";
CM_ SG_ 987 FR_WRN "FRONT RIGHT WARNING";
CM_ SG_ 987 FRC_POS "FRONT CENTER RIGHT DETECTION POSITION";
CM_ SG_ 987 FLC_POS "FRONT CENTER LEFT DETECTION POSITION";
CM_ SG_ 987 FL_WRN "FRONT LEFT WARNING";
CM_ SG_ 987 RR_POS "REAR RIGHT DETECTION POSITION";
CM_ SG_ 987 RL_POS "REAR LEFT DETECTION POSITION";
CM_ SG_ 987 FRC_WRN "FRONT CENTER RIGHT WARNING";
CM_ SG_ 987 RRC_POS "REAR CENTER RIGHT DETECTION POSITION";
CM_ SG_ 987 RLC_POS "REAR CENTER LEFT DETECTION POSITION";
CM_ SG_ 987 FLC_WRN "FRONT CENTER LEFT WARNING";
CM_ SG_ 987 RR_WRN "REAR RIGHT WARNING";
CM_ SG_ 987 RL_WRN "REAR LEFT WARNING";
CM_ SG_ 987 RRC_WRN "REAR CENTER RIGHT WARNING";
CM_ SG_ 987 RLC_WRN "REAR CENTER LEFT WARNING";
CM_ SG_ 987 CSMUTESW "CSR MUTE SW";
CM_ SG_ 987 CSRDISP1 "CSR DISPLAY REQUEST(MM)";
CM_ SG_ 987 CSRDISP3 "CSR DISPLAY REQUEST(MET)";
CM_ SG_ 987 CSR_VE3 "CSR VEHICLE MARK DISPLAY REQUEST";
CM_ SG_ 987 CSDETSYM "CSR DETECTION SYMBOL DISPLAY REQUEST";
CM_ SG_ 987 CSR_TTR "CSR OFF Indicator request";
CM_ SG_ 987 CS_LAMP "CSR TERTAIL REQUEST";
CM_ BO_ 988 "Reserve";
CM_ SG_ 988 FR_DIRT "Front Right Dirt indication";
CM_ SG_ 988 FL_DIRT "Front Left Dirt indication";
CM_ SG_ 988 FRC_DIRT "Front Right Centar Dirt indication";
CM_ SG_ 988 FLC_DIRT "Front Left Centar Dirt indication";
CM_ SG_ 988 RR_DIRT "Rear Right Dirt indication";
CM_ SG_ 988 RL_DIRT "Rear Left Dirt indication";
CM_ SG_ 988 RRC_DIRT "Rear Right Centar Dirt indication";
CM_ SG_ 988 RLC_DIRT "Rear Left Centar Dirt indication";
CM_ SG_ 988 FRS_DIRT "Front Right Side Dirt indication";
CM_ SG_ 988 FLS_DIRT "Front Left Side Dirt indication";
CM_ SG_ 988 RRS_DIRT "Rear Right Side Dirt indication";
CM_ SG_ 988 RLS_DIRT "Rear Left Side Dirt indication";
CM_ SG_ 988 CSR_INF1 "ClearanceSonar Information 1";
CM_ SG_ 988 CSR_INF2 "ClearanceSonar Information 2";
CM_ SG_ 988 PKSSINFO "Parking System Information";
CM_ SG_ 988 PKSS_VE "PARKING SYSTEM VEHICLE MARK";
CM_ SG_ 988 RCDAVABL "RCD Telltale Lamp on Information screen";
CM_ SG_ 988 ICSAVABL "ICS Telltale Lamp on Information screen";
CM_ SG_ 988 CSRAVABL "CSR Telltale Lamp on Information screen";
CM_ SG_ 988 CAM_INF1 "Camera Information 1";
CM_ SG_ 988 CSR_VOL "ClearanceSonar Metar Buzzer Volume";
CM_ SG_ 988 CSR_BUZ "ClearanceSonar Buzzer Command";
CM_ BO_ 637 "Reserve";
CM_ SG_ 637 THR_GLOB "Rear Motor Coil Temperature";
CM_ SG_ 637 TMO_GLOB "Front Motor Coil Temperature";
CM_ SG_ 637 TTA_GLOB "ATF Temperature";
CM_ SG_ 637 RTA_GLOB "MGR ATF Temperature";
CM_ BO_ 299 "Reserve";
CM_ SG_ 299 TR_GLOB "Rear Motor Torque";
CM_ SG_ 299 TM_GLOB "Front Motor Torque";
CM_ SG_ 299 NR_GLOB "Rear Motor Revolution";
CM_ SG_ 299 NM_GLOB "Front Motor Revolution";
CM_ BO_ 537 "Reserve";
CM_ SG_ 537 C_GCMD1 "GDP Customize current mode info (Mode 1)";
CM_ SG_ 537 C_GCMD2 "GDP Customize current mode info (Mode 2)";
CM_ SG_ 537 C_GCMD3 "GDP Customize current mode info (Mode 3)";
CM_ SG_ 537 C_GCMD4 "GDP Customize current mode info (Mode 4)";
CM_ SG_ 537 C_GCMD5 "GDP Customize current mode info (Mode 5)";
CM_ SG_ 537 C_GCMD6 "GDP Customize current mode info (Mode 6)";
CM_ SG_ 537 C_GCMD7 "GDP Customize current mode info (Mode 7)";
CM_ SG_ 537 C_GCMD8 "GDP Customize current mode info (Mode 8)";
CM_ SG_ 537 GDPCEXT "GDP Customize Function Existence";
CM_ SG_ 537 GDPCVLD "GDP Customize Function Valid  Information";
CM_ SG_ 537 BRKFRESH "Brake Disc Refresh Operation";
CM_ SG_ 537 BDRSSWEX "Brake Refresh Control: Software SW Availability";
CM_ SG_ 537 DDDBWHCN "Presumed causes of updated wheel conditions";
CM_ SG_ 537 DDFRWHCN "Updated FR wheel condition";
CM_ SG_ 537 DDFLWHCN "Updated FL wheel condition";
CM_ SG_ 537 DDRRWHCN "Updated RR wheel condition";
CM_ SG_ 537 DDRLWHCN "Updated RL wheel condition";
CM_ BO_ 673 "Reserve";
CM_ SG_ 673 B_ISPTM "Mode indicator signal";
CM_ SG_ 673 B_GEAR "Shift gear";
CM_ SG_ 673 B_RJTB "Reject buzzer";
CM_ BO_ 980 "Reserve";
CM_ SG_ 980 SLCT "Speed limiter mode state";
CM_ BO_ 126 "Reserve";
CM_ SG_ 126 HV_SRGMD "Strong Regen Control Mode";
CM_ SG_ 126 TQRR "Execution torque Rr (Main-DS axis)";
CM_ SG_ 126 TQFR "Execution torque Fr (Main-DS axis)";
CM_ BO_ 165 "Reserve";
CM_ SG_ 165 HV_NE "Engine RPM data by HVECU";
CM_ SG_ 165 TLNCHLMT "Launch control limit time";
CM_ SG_ 165 STSLNCH "Launch control display status";
CM_ BO_ 679 "Reserve";
CM_ SG_ 679 KRLA "Road Load a";
CM_ SG_ 679 KRLB "Road Load b";
CM_ SG_ 679 KRLC "Road Load c";
CM_ SG_ 679 VMASS "MASS";
CM_ BO_ 680 "Reserve";
CM_ SG_ 680 NKEFPWH "Navi EfficiencyPower for high vehicle speeds";
CM_ SG_ 680 NKEFRGH "Navi Efficiency Regeneration for high vehicle speeds";
CM_ SG_ 680 NKEFPWL "Navi Efficiency Power for low vehicle speeds";
CM_ SG_ 680 NKEFRGL "Navi Efficiency Regeneration for low vehicle speeds";
CM_ SG_ 680 NSTLOS "Navi Steady-state loss";
CM_ SG_ 680 KSELECO "Study electricity cost";
CM_ BO_ 734 "Reserve";
CM_ SG_ 734 CLDCLV "Current Deceleration Level";
CM_ SG_ 734 CDRJTB "Deceleration operation reject buzzer reqest";
CM_ SG_ 734 MDRJTMSG "Manual Mode Reject Message";
CM_ SG_ 734 SLCTDISP "MBEV meter design selection request";
CM_ SG_ 734 VARMBEV "MBEV information";
CM_ SG_ 734 CLDCLV2 "Current Deceleration Level2";
CM_ SG_ 734 EVMILRQR "ZEV-MIL(Red) lighting request";
CM_ SG_ 734 EVMILRQA "ZEV-MIL(Amber) lighting request";
CM_ BO_ 166 "Reserve";
CM_ SG_ 166 SFTGDMET "Shift guide meter";
CM_ SG_ 166 PMCHGHL "Power Meter Regeneration Highlitgh Request";
CM_ SG_ 166 PMPWRHL "Power Meter Output Highlitgh Request";
CM_ SG_ 166 PMEVCR "Power meter level";
CM_ SG_ 166 PMPWRTH "Limit Output Indication";
CM_ SG_ 166 PMCHGTH "Limit Regenerative Indication";
CM_ BO_ 117 "Reserve";
CM_ SG_ 117 SDRVRR "Accelerator demand basic driving force Rr (Main-DS axis)";
CM_ SG_ 117 SDRVFR "Accelerator demand basic driving force Fr (Main-DS axis)";
CM_ BO_ 161 "Reserve";
CM_ SG_ 161 HVMRADRR "Rear motor RPM";
CM_ SG_ 161 HVMRADFR "Front motor RPM";
CM_ BO_ 1523 "Reserve";
CM_ SG_ 1523 I_BAT_BD "Aux battery current for monitor";
CM_ SG_ 1523 U_BAT_BD "Aux battery voltage for monitor";
CM_ SG_ 1523 PWDTY_BD "Generator output state for monitor";
CM_ SG_ 1523 VLO_BD "Generator designation voltage for monitor";
CM_ SG_ 1523 PWIF1_BD "Power source information No.1 for monitor";
CM_ BO_ 1524 "Reserve";
CM_ SG_ 1524 T_BAT_BD "Aux battery temperature for monitor";
CM_ SG_ 1524 PWIF2_BD "Power source information No.2 for monitor";
CM_ SG_ 1524 SOCS_BD "Aux battery SOC status for monitor";
CM_ SG_ 1524 SOC_BD "Aux battery SOC for monitor";
CM_ SG_ 1524 PWIF3_BD "Power source information No.3 for monitor";
CM_ SG_ 1524 PWIF4_BD "Power source information No.4 for monitor";
CM_ SG_ 1524 PWIF5_BD "Power source information No.5 for monitor";
CM_ BO_ 1177 "Reserve";
CM_ SG_ 1177 DRENG11 "Diag Recorder ENG11";
CM_ SG_ 1177 DRENG12 "Diag Recorder ENG12";
CM_ SG_ 1177 DRENG13 "Diag Recorder ENG13";
CM_ SG_ 1177 DRENG14 "Diag Recorder ENG14";
CM_ SG_ 1177 DRENG15 "Diag Recorder ENG15";
CM_ SG_ 1177 DRENG16 "Diag Recorder ENG16";
CM_ SG_ 1177 DRENG17 "Diag Recorder ENG17";
CM_ SG_ 1177 DRENG18 "Diag Recorder ENG18";
CM_ BO_ 1178 "Reserve";
CM_ SG_ 1178 DRENG21 "Diag Recorder ENG21";
CM_ SG_ 1178 DRENG22 "Diag Recorder ENG22";
CM_ SG_ 1178 DRENG23 "Diag Recorder ENG23";
CM_ SG_ 1178 DRENG24 "Diag Recorder ENG24";
CM_ SG_ 1178 DRENG25 "Diag Recorder ENG25";
CM_ SG_ 1178 DRENG26 "Diag Recorder ENG26";
CM_ SG_ 1178 DRENG27 "Diag Recorder ENG27";
CM_ SG_ 1178 DRENG28 "Diag Recorder ENG28";
CM_ BO_ 1179 "Reserve";
CM_ SG_ 1179 DRENG31 "Diag Recorder ENG31";
CM_ SG_ 1179 DRENG32 "Diag Recorder ENG32";
CM_ SG_ 1179 DRENG33 "Diag Recorder ENG33";
CM_ SG_ 1179 DRENG34 "Diag Recorder ENG34";
CM_ SG_ 1179 DRENG35 "Diag Recorder ENG35";
CM_ SG_ 1179 DRENG36 "Diag Recorder ENG36";
CM_ SG_ 1179 DRENG37 "Diag Recorder ENG37";
CM_ SG_ 1179 DRENG38 "Diag Recorder ENG38";
CM_ BO_ 1181 "Reserve";
CM_ SG_ 1181 DRENG51 "Diag Recorder ENG51";
CM_ SG_ 1181 DRENG52 "Diag Recorder ENG52";
CM_ SG_ 1181 DRENG53 "Diag Recorder ENG53";
CM_ SG_ 1181 DRENG54 "Diag Recorder ENG54";
CM_ SG_ 1181 DRENG55 "Diag Recorder ENG55";
CM_ SG_ 1181 DRENG56 "Diag Recorder ENG56";
CM_ SG_ 1181 DRENG57 "Diag Recorder ENG57";
CM_ SG_ 1181 DRENG58 "Diag Recorder ENG58";
CM_ BO_ 1192 "Reserve";
CM_ SG_ 1192 DRENG61 "Diag Recorder ENG61";
CM_ SG_ 1192 DRENG62 "Diag Recorder ENG62";
CM_ SG_ 1192 DRENG63 "Diag Recorder ENG63";
CM_ SG_ 1192 DRENG64 "Diag Recorder ENG64";
CM_ SG_ 1192 DRENG65 "Diag Recorder ENG65";
CM_ SG_ 1192 DRENG66 "Diag Recorder ENG66";
CM_ SG_ 1192 DRENG67 "Diag Recorder ENG67";
CM_ SG_ 1192 DRENG68 "Diag Recorder ENG68";
CM_ BO_ 1198 "Reserve";
CM_ SG_ 1198 DRENG91 "Diag Recorder ENG91";
CM_ SG_ 1198 DRENG92 "Diag Recorder ENG92";
CM_ SG_ 1198 DRENG93 "Diag Recorder ENG93";
CM_ SG_ 1198 DRENG94 "Diag Recorder ENG94";
CM_ SG_ 1198 DRENG95 "Diag Recorder ENG95";
CM_ SG_ 1198 DRENG96 "Diag Recorder ENG96";
CM_ SG_ 1198 DRENG97 "Diag Recorder ENG97";
CM_ SG_ 1198 DRENG98 "Diag Recorder ENG98";
CM_ BO_ 1199 "Reserve";
CM_ SG_ 1199 DRENG101 "Diag Recorder ENG101";
CM_ SG_ 1199 DRENG102 "Diag Recorder ENG102";
CM_ SG_ 1199 DRENG103 "Diag Recorder ENG103";
CM_ SG_ 1199 DRENG104 "Diag Recorder ENG104";
CM_ SG_ 1199 DRENG105 "Diag Recorder ENG105";
CM_ SG_ 1199 DRENG106 "Diag Recorder ENG106";
CM_ SG_ 1199 DRENG107 "Diag Recorder ENG107";
CM_ SG_ 1199 DRENG108 "Diag Recorder ENG108";
CM_ BO_ 163 "Reserve";
CM_ SG_ 163 B_NEIND "Number of Engine speed Indicator";
CM_ BO_ 1417 "Reserve";
CM_ SG_ 1417 P_DCMOD1 "Powertrain Drive Mode Customize 1";
CM_ SG_ 1417 P_DCMOD2 "Powertrain Drive Mode Customize 2";
CM_ SG_ 1417 P_DCMOD3 "Powertrain Drive Mode Customize 3";
CM_ SG_ 1417 RSCLVL "RSC level";
CM_ SG_ 1417 P_DCMOD4 "Powertrain Drive Mode Customize 4";
CM_ SG_ 1417 C_DCMOD1 "Chassis system Customizing information";
CM_ SG_ 1417 C_DCMOD2 "Chassis system Customizing support information";
CM_ SG_ 1417 C_DCMOD3 "Chassis system Customizing status";
CM_ SG_ 1417 C_DCMDE1 "Steering system Customizing information";
CM_ SG_ 1417 C_DCMDE2 "Steering system Customizing support";
CM_ SG_ 1417 C_DCMDE3 "Steering system Customizing status";
CM_ SG_ 1417 C_DMODEE "Steering system Drive Mode information";
CM_ SG_ 1417 C_DCMDS1 "Suspension system Customizing information";
CM_ SG_ 1417 C_DCMDS2 "Suspension system Customizing support information";
CM_ SG_ 1417 C_DCMDS3 "Suspension system Customizing status";
CM_ SG_ 1417 C_DMODES "Suspension system Drive Mode information";
CM_ SG_ 1417 C_DCMDB1 "Brake system Customizing information";
CM_ SG_ 1417 C_DCMDB2 "Brake system Customizing support information";
CM_ SG_ 1417 C_DCMDB3 "Brake system Customizing status";
CM_ SG_ 1417 C_DMODEB "Brake system Drive Mode information";
CM_ SG_ 1417 VSC_DCMD "Brake system Customizing status";
CM_ SG_ 1417 RSCEXIST "RSC existence flag";
CM_ SG_ 1417 DSCEXIST "DSC existance flag";
CM_ SG_ 1417 B_DMINF3 "Drive Mode Select Availability Mode Information 3";
CM_ SG_ 1417 B_DMINF4 "Drive Mode Select Availability Mode Information 4";
CM_ SG_ 1417 B_OMINF "Offroad Mode Select Availability Mode Information";
CM_ SG_ 1417 OMSSSWEX "Off Road Mode Select Software switch existence";
CM_ SG_ 1417 MT2SSWEX "MTS 2Mode Select Software switch existence";
CM_ SG_ 1417 CRLSSWEX "CRAWL Mode Select Software switch existence";
CM_ BO_ 1411 "Reserve";
CM_ SG_ 1411 GRSMET_R "Grille Shutter request Meter";
CM_ BO_ 1187 "Reserve";
CM_ SG_ 1187 DREPS01 "Drive Recorder EPS01";
CM_ SG_ 1187 DREPS02 "Drive Recorder EPS02";
CM_ SG_ 1187 DREPS03 "Drive Recorder EPS03";
CM_ SG_ 1187 DREPS04 "Drive Recorder EPS04";
CM_ SG_ 1187 DREPS05 "Drive Recorder EPS05";
CM_ SG_ 1187 DREPS06 "Drive Recorder EPS06";
CM_ SG_ 1187 DREPS07 "Drive Recorder EPS07";
CM_ SG_ 1187 DREPS08 "Drive Recorder EPS08";
CM_ BO_ 1526 "Reserve";
CM_ SG_ 1526 V_DIST "Target Vehicle Distance(CAN-VP)";
CM_ SG_ 1526 V_RELV "Target Vehicle Relative Velocity";
CM_ SG_ 1526 V_SWOP "SW Operation information(CAN-VP)";
CM_ SG_ 1526 USMREQG "URSM Acceleration Request";
CM_ SG_ 1526 RCURVR "Recognized curve R";
CM_ SG_ 1526 USMDSTTS "Distance to the Traffic Sign";
CM_ SG_ 1526 COFFSET "Offset from road center";
CM_ SG_ 1526 USMDSTSL "Distance to the Stop Line";
CM_ SG_ 1526 RSACAUF "RSA Caution Flag";
CM_ BO_ 1521 "Reserve";
CM_ SG_ 1521 USMCNTST "URSM Control state";
CM_ SG_ 1521 USMFUNC "URSM Function Setting";
CM_ SG_ 1521 USMSENS "URSM sensitivity setting";
CM_ SG_ 1521 USMACTFG "URSM Act Flag";
CM_ SG_ 1521 USMTSTYP "URSM Traffic Sign type";
CM_ SG_ 1521 SGNOFFST "Sign Lateral Offset Information";
CM_ SG_ 1521 TSGNINF "Traffic sign information";
CM_ SG_ 1521 DLCAMSG "LCA message display for data acquisition";
CM_ SG_ 1521 RTYPE "Road type";
CM_ SG_ 1521 DLCAINDI "LCA Indicator display for data acquisition";
CM_ SG_ 1521 RTYPERE "Road type reliability";
CM_ SG_ 1521 V_BRKON "Under brake control execution (CAN-VP)";
CM_ SG_ 1521 RCLSINF "Road class infrmation";
CM_ SG_ 1521 PCSPREF2 "PCS pre function 2";
CM_ SG_ 1521 PCSPREF1 "PCS pre function 1";
CM_ SG_ 1521 CRU_STAT "ACC Control status(CAN-VP)";
CM_ SG_ 1521 V_VMCC "Preset vehicle speed(CAN-VP)";
CM_ SG_ 1521 V_LTME "Set vehicle following time(CAN-VP)";
CM_ SG_ 1521 V_LCCWOK "ACC Approach warning(CAN-VP)";
CM_ SG_ 1521 V_XTGTCC "ACC Front Vehicle Flag(CAN-VP)";
CM_ SG_ 1521 V_RELA "Target Relative Acceleration(CAN-VP)";
CM_ SG_ 1521 V_ACCUST "ACC Acceleration customized setting(CAN-VP)";
CM_ SG_ 1521 USMTGTPV "URSM target vehicle information";
CM_ SG_ 1521 USMRCGTL "Recognition state of Traffic Light ";
CM_ SG_ 1521 V_LATPOS "Target Vehicle Lateral Position(CAN-VP)";
CM_ SG_ 1521 V_ATACC "ACC/ISA Target Acceleration(CAN-VP)";
CM_ SG_ 1521 TSGNINF2 "Traffic sign information 2";
CM_ SG_ 1521 USMLTL "Course division (left-turn lane)";
CM_ SG_ 1521 USMSTL "Course division (straight-running lane)";
CM_ SG_ 1521 USMRTL "Course division (right-turn lane)";
CM_ SG_ 1521 V_IDAOPE "IDA operaion status for CAN-VP";
CM_ SG_ 1521 LVNBUZDD "LVN buzzer request for Driving Diagnosis";
CM_ SG_ 1521 LVNSTDD "LVN ON/OFF info for Driving Diagnosis";
CM_ SG_ 1521 SUSUNABL "AP_Condition of being suspended, or unable";
CM_ SG_ 1521 APRCGSTS "AP_Recognition Status";
CM_ SG_ 1521 AP_FUNC "Advanced Park Function";
CM_ SG_ 1521 POSX "DISTANCE TO TARGET (X)";
CM_ SG_ 1521 POSZ "DISTANCE TO TARGET (Z)";
CM_ SG_ 1521 POSTHETA "ANGLE OF TARGET";
CM_ SG_ 1521 APSTS "AP CONTROL STATUS";
CM_ SG_ 1521 RODWDH "ROAD WIDTH";
CM_ SG_ 1521 FRNTGINF "PARKING FRONTAGE";
CM_ BO_ 1161 "Reserve";
CM_ SG_ 1161 TSGN1 "Traffic Sign 1";
CM_ SG_ 1161 TSGNHLT1 "Traffic Sign Highlight1";
CM_ SG_ 1161 SPDVAL1 "Speed Value1";
CM_ SG_ 1161 SPLSGN1 "Suplemental Sign1";
CM_ SG_ 1161 SPLSGN2 "Suplemental Sign2";
CM_ SG_ 1161 TSGN2 "Traffic Sign 2";
CM_ SG_ 1161 TSGNHLT2 "Traffic Sign Highlight2";
CM_ SG_ 1161 SPDVAL2 "Speed Value2";
CM_ SG_ 1161 BZRRQ_A "Buzzer request of ADAS tab";
CM_ SG_ 1161 TSGN3 "Traffic Sign 3";
CM_ SG_ 1161 TSGNHLT3 "Traffic Sign Highlight3";
CM_ SG_ 1161 WRNGWAYC "Driving wrong way caution request";
CM_ SG_ 1161 SPLSGN3 "Suplemental Sign3";
CM_ SG_ 1161 SPLSGN4 "Suplemental Sign4";
CM_ SG_ 1161 TSGN4 "Traffic Sign 4";
CM_ SG_ 1161 SGNNUMH "Sign Number of Head Up Display";
CM_ SG_ 1161 TSGNHLT4 "Traffic Sign Highlight4";
CM_ SG_ 1161 SPBZRQ "Speed limit sign change Buzzer request";
CM_ SG_ 1161 SGNNUMP "Sign Number of Permanent area";
CM_ SG_ 1161 SGNNUMA "Sign Number of ADAS tab";
CM_ SG_ 1161 TLTASWAY "TrailerLTA Sway Warning";
CM_ SG_ 1161 TRSTINFO "Trailer state information message";
CM_ SG_ 1161 TLTASYST "TrailerLTA System State Indicator";
CM_ SG_ 1161 SPLSGN5 "Suplemental Sign5";
CM_ SG_ 1161 TSGNHLT5 "Traffic Sign Highlight5";
CM_ SG_ 1161 TSGN5 "Traffic Sign 5";
CM_ SG_ 1161 CLTRLLEN "Trailer length information for cloud analysis";
CM_ BO_ 1163 "Reserve";
CM_ SG_ 1163 TSREQPD "TSR equipped";
CM_ SG_ 1163 TSRMSW "TSR Main SW";
CM_ SG_ 1163 OVSPNTM "Over Speed Notice Method";
CM_ SG_ 1163 NOETYEXT "No Entry soft SW Exist";
CM_ SG_ 1163 NOEYNTM "No Entry Caution Method";
CM_ SG_ 1163 OVSPVALL "Over Speed Lo";
CM_ SG_ 1163 REDSGEXT "No Entry/Red Signal soft SW Exist";
CM_ SG_ 1163 RDSLNTM "No Entry/Red Signal Caution Method";
CM_ SG_ 1163 OVSPVALM "Over Speed Mid";
CM_ SG_ 1163 NTLVLSPD "Notice Level of speed limit";
CM_ SG_ 1163 OVSPVALH "Over Speed High";
CM_ SG_ 1163 XSSPDEXT "Excess Speed soft SW Exist";
CM_ SG_ 1163 TSRSWEXT "TSR main soft SW Exist";
CM_ SG_ 1163 TSRSPU "TSR Display Speed Unit";
CM_ SG_ 1163 SPBZEXT "Speed limit sign change buzzer SW exist";
CM_ SG_ 1163 RSACTIVE "RSA Active Information";
CM_ SG_ 1163 NTFLVEXT "Notification Level soft SW Exist";
CM_ SG_ 1163 SPBZSTS "Speed limit sign change buzzer SW select status";
CM_ BO_ 594 "Reserve";
CM_ SG_ 594 ACCMSG2 "ACC Message 2";
CM_ SG_ 594 ACCMSG3 "ACC Message 3(interrupt)";
CM_ SG_ 594 ACCMSGU "Numerical unit for message";
CM_ SG_ 594 ACCMSPSS "Next speed sign from Map";
CM_ SG_ 594 ACCMSG4 "ACC Message 4(proposal)";
CM_ SG_ 594 ACCMSGV "Numerical value for message";
CM_ SG_ 594 ACCBZRQ "ACC buzzer request";
CM_ SG_ 594 ACCCNTOB "Control object information";
CM_ SG_ 594 ACCMSPVL "Next speed sign numeric";
CM_ SG_ 594 ACCMCNOB "Control object information for MAP ACC";
CM_ SG_ 594 ACCMOST1 "Control object state1 (color) for MAP ACC";
CM_ SG_ 594 ERMEFCT "ERM effect";
CM_ BO_ 609 "Reserve";
CM_ SG_ 609 ACCSSOD "Sign speed offset setting information";
CM_ SG_ 609 ISAEX "ISA system existence";
CM_ SG_ 609 ACCRACEX "RSA cooperation existence";
CM_ SG_ 609 ACCRACD "RSA cooperation setting information";
CM_ SG_ 609 ACCROSEX "Restraint of overtaking existence";
CM_ SG_ 609 ACCROSD "Restraint of overtaking setting information";
CM_ SG_ 609 ACCACLD "Cruise acceleration setting information";
CM_ SG_ 609 ACCSPEX "Speed management existence";
CM_ SG_ 609 ACCSPD "Speed management setting information";
CM_ SG_ 609 ACCRSAC "RSA cooperation state";
CM_ SG_ 609 ACCRSACB "RSA cooperation state(blinking)";
CM_ SG_ 609 ACCSSAG "Application guide of sign speed";
CM_ SG_ 609 ACCSSAGB "Application guide of sign speed(blinking)";
CM_ SG_ 609 VIDEO_OK "Permission of watching video during stop holding";
CM_ SG_ 609 CCSMDSTA "CCS MODE Status";
CM_ SG_ 609 CCSMDEXT "CCS MODE exist";
CM_ SG_ 609 SLSSOD "Speed limiter sign speed offset setting information";
CM_ SG_ 609 SLSSOEX "Speed limiter sign speed offset existence";
CM_ SG_ 609 ERMEX "Adaptive Cruise Eco Run Mode Exist";
CM_ SG_ 609 ACCGCRD "ACC support for Signals and intersections Status";
CM_ SG_ 609 ACCGCREX "ACC support for Signals and intersections Exist";
CM_ SG_ 609 ERMLV "Setting value of ACC-EcoRunMode";
CM_ SG_ 609 AECOEX "ADAS ECO Exist";
CM_ SG_ 609 AECOLV "Setting value of ADAS ECO";
CM_ SG_ 609 SLDSEX "Speed limiter default ON setting existence";
CM_ SG_ 609 SLDSD "Speed limiter default ON setting information";
CM_ SG_ 609 SLSSSEX "Speed limiter sign speed setting existence";
CM_ SG_ 609 SLSSSD "Speed limiter sign speed setting information";
CM_ BO_ 628 "Reserve";
CM_ SG_ 628 OTHVW "Target Vehicle Width (Crash Prevention Integration)";
CM_ SG_ 628 OTHVH "Target Vehicle Height (Crash Prevention Integration)";
CM_ SG_ 628 OTHPB "PB Request Flag (Crash Prevention Integration)";
CM_ SG_ 628 OTHTTC "Target TTC (Crash Prevention Integration)";
CM_ SG_ 628 OTHTTYP "Target Classification (Crash Prevention Integration)";
CM_ SG_ 628 HITPOS "Hitting position";
CM_ SG_ 628 OTHRDANG "Target Relative Course Angle (Crash Prevention Integration)";
CM_ SG_ 628 OTHOVLPC "Target Overlap Rate for Predictive Control";
CM_ SG_ 628 OTHRVPC "Target Relative Velocity for Predictive Control";
CM_ BO_ 629 "Reserve";
CM_ SG_ 629 IDADSPL "IDA left side display";
CM_ SG_ 629 IDAEXIST "IDA existence flag";
CM_ SG_ 629 IDASENST "IDA sensitivity status";
CM_ SG_ 629 IDAONST "IDA function ON/OFF status";
CM_ SG_ 629 IDADSPR "IDA right side display";
CM_ SG_ 629 IDADSPC "IDA central display";
CM_ SG_ 629 IDABUZZ "IDA buzzer request";
CM_ SG_ 629 IDACAN "IDA cancel information";
CM_ SG_ 629 DWREQ "Distance Warning request";
CM_ SG_ 629 USMDSPPV "URSM preceding vehicle display";
CM_ SG_ 629 USMDSPTL "URSM traffic light display";
CM_ SG_ 629 USMDSPCR "URSM curve display";
CM_ SG_ 629 USMBZ "URSM Buzzer";
CM_ SG_ 629 USMDSPRM "DA recommend indication ";
CM_ SG_ 629 USMDSPTG "DA indicate deceleration target";
CM_ BO_ 630 "Reserve";
CM_ SG_ 630 FCMDUST "FCM DUST message";
CM_ SG_ 630 FCMTEMP "FCM TEMP message";
CM_ SG_ 630 FRDDUST "FRD DUST message";
CM_ SG_ 630 FRDTEMP "FRD TEMP message";
CM_ SG_ 630 FRDTUCT "FRD temporary unusable condition text display";
CM_ SG_ 630 TSSMALF "TSS malfunction message";
CM_ SG_ 630 TSSTUNA "TSS Temporary Failure message";
CM_ SG_ 630 PCSAVABL "PCS usability judgment flag";
CM_ SG_ 630 ACCAVABL "ACC usability judgment flag";
CM_ SG_ 630 LTAAVABL "LTA usability judgment flag";
CM_ SG_ 630 LCAAVABL "LCA usability judgment flag";
CM_ SG_ 630 EDSSVABL "EDSS usability judgment flag";
CM_ SG_ 630 RSAAVABL "RSA usability judgment flag";
CM_ SG_ 630 AHBAVABL "AHB usability judgment flag";
CM_ SG_ 630 IDAAVABL "IDA usability judgment flag";
CM_ SG_ 630 ACCERMEX "Adaptive Cruise Eco Run Mode Function Exist";
CM_ SG_ 630 TJAAVABL "ADTJA usability judgment flag";
CM_ SG_ 630 ERMAVABL "ERM usability judgment flag";
CM_ SG_ 630 EDSSEXST "EDSS existence";
CM_ SG_ 630 TMAVABL "TM usability judgment flag";
CM_ SG_ 630 FCTAAVBL "FCTA usability judgment flag";
CM_ SG_ 630 AHBEXIST "AHB existence flag";
CM_ SG_ 630 ADU_INF3 "ADU Information 3";
CM_ SG_ 630 CCAVABL "CC usability judgment flag";
CM_ SG_ 630 CCEX "CC existence";
CM_ SG_ 630 ADU_INF4 "ADU Information 4";
CM_ SG_ 630 ADUTUNA "ADAS Temporary Failure message";
CM_ SG_ 630 TMNAVABL "TMN usability judgment flag";
CM_ SG_ 630 ISAAVABL "ISA usability judgment flag";
CM_ SG_ 630 LDAAVABL "LDA usability judgment flag";
CM_ SG_ 630 USMDSE "URSM sensitivity state";
CM_ SG_ 630 USMSW "URSM Main SW state";
CM_ SG_ 630 ADU_INF1 "ADU Information 1";
CM_ SG_ 630 ADU_INF2 "ADU Information 2";
CM_ SG_ 630 USMONST "URSM function ON/OFF status";
CM_ SG_ 630 USMEXIST "URSM existence flag";
CM_ SG_ 630 SDGCONT "SDG control status";
CM_ SG_ 630 SDGONST "SDG function ON/OFF status";
CM_ SG_ 630 SDGEXIST "SDG existence flag";
CM_ SG_ 630 PDAONST "PDA function ON/OFF status";
CM_ SG_ 630 PDAEXIST "PDA existence flag";
CM_ SG_ 630 SWSAVABL "SWS usability judgment flag";
CM_ SG_ 630 DMCAVABL "DMC usability judgement flag";
CM_ SG_ 630 DMCEXIST "Confirmation DMC";
CM_ SG_ 630 BSDAVABL "BSD usability judgment flag";
CM_ SG_ 630 RCTAAVBL "RCTA usability judgment flag";
CM_ SG_ 630 FHLAVABL "FHL usability judgment flag";
CM_ SG_ 630 SEAAVABL "SEA usability judgment flag";
CM_ SG_ 630 ADDSAVBL "ADDS usability judgment flag";
CM_ BO_ 636 "Reserve";
CM_ SG_ 636 TSSSPDIS "Driving support mode display request";
CM_ SG_ 636 TSSSPNUM "Driving support mode total number";
CM_ SG_ 636 TSSSPSEL "Selected driving support mode display";
CM_ SG_ 636 TSSSPMSG "Driving support guidance message";
CM_ SG_ 636 TSSSPMD1 "Driving support mode1";
CM_ SG_ 636 TSSSPMD2 "Driving support mode2";
CM_ SG_ 636 TSSSPMD3 "Driving support mode3";
CM_ SG_ 636 TSSSPMS3 "Mode3 Selectability";
CM_ SG_ 636 TSSSPMS2 "Mode2 Selectability";
CM_ SG_ 636 TSSSPMS1 "Mode1 Selectability";
CM_ SG_ 636 TSSSPMD4 "Driving support mode4";
CM_ SG_ 636 TSSSPMS4 "Mode4 Selectability";
CM_ SG_ 636 TSSMDREJ "Driving support mode rejection message";
CM_ SG_ 636 TSMDAPST "Selected app status of driving support mode";
CM_ SG_ 636 ACCVRAPR "ACC Voice Recognition Approval Display Request";
CM_ BO_ 650 "Reserve";
CM_ SG_ 650 TSS_TID "TSS voice recognition TableID";
CM_ SG_ 650 TSSFNC11 "TSS voice recognition Function11";
CM_ SG_ 650 TSSFNC12 "TSS voice recognition Function12";
CM_ SG_ 650 TSSFNC13 "TSS voice recognition Function13";
CM_ SG_ 650 TSSFNC14 "TSS voice recognition Function14";
CM_ SG_ 650 TSSFNC15 "TSS voice recognition Function15";
CM_ SG_ 650 TSSFNC16 "TSS voice recognition Function16";
CM_ SG_ 650 TSSFNC17 "TSS voice recognition Function17";
CM_ SG_ 650 TSSFNC21 "TSS voice recognition Function21";
CM_ SG_ 650 TSSFNC22 "TSS voice recognition Function22";
CM_ SG_ 650 TSSFNC23 "TSS voice recognition Function23";
CM_ SG_ 650 TSSFNC24 "TSS voice recognition Function24";
CM_ SG_ 650 TSSFNC25 "TSS voice recognition Function25";
CM_ SG_ 650 TSSFNC26 "TSS voice recognition Function26";
CM_ SG_ 650 TSSFNC27 "TSS voice recognition Function27";
CM_ SG_ 650 TSSFNC28 "TSS voice recognition Function28";
CM_ SG_ 650 TSSVRRES "TSS voice recognition response";
CM_ SG_ 650 TSSOPE11 "TSS voice recognition OperationInf11";
CM_ SG_ 650 TSSOPE12 "TSS voice recognition OperationInf12";
CM_ SG_ 650 TSSOPE13 "TSS voice recognition OperationInf13";
CM_ SG_ 650 TSSOPE14 "TSS voice recognition OperationInf14";
CM_ SG_ 650 TSSOPE15 "TSS voice recognition OperationInf15";
CM_ SG_ 650 TSSOPE16 "TSS voice recognition OperationInf16";
CM_ SG_ 650 TSSOPE17 "TSS voice recognition OperationInf17";
CM_ SG_ 650 TSSOPE21 "TSS voice recognition OperationInf21";
CM_ SG_ 650 TSSOPE22 "TSS voice recognition OperationInf22";
CM_ SG_ 650 TSSOPE23 "TSS voice recognition OperationInf23";
CM_ SG_ 650 TSSOPE24 "TSS voice recognition OperationInf24";
CM_ SG_ 650 TSSOPE25 "TSS voice recognition OperationInf25";
CM_ SG_ 650 TSSOPE26 "TSS voice recognition OperationInf26";
CM_ SG_ 650 TSSOPE27 "TSS voice recognition OperationInf27";
CM_ SG_ 650 TSSOPE28 "TSS voice recognition OperationInf28";
CM_ BO_ 345 "Reserve";
CM_ SG_ 345 OTHFALD "Falling object detection information";
CM_ SG_ 345 OTHCOND "Construction detection information";
CM_ SG_ 345 OTHLDIS "Distance from own vehicle to leading vehicle";
CM_ SG_ 345 OTHFALF "Falling object detection flag";
CM_ SG_ 345 OTHCONF "Construction detection flag";
CM_ SG_ 345 OTHLANE "Lane crossing information";
CM_ BO_ 527 "Reserve";
CM_ SG_ 527 TSSVOI05 "FCM Voice information 05";
CM_ SG_ 527 TSSVOI06 "FCM Voice information 06";
CM_ SG_ 527 TSSVOI01 "FCM Voice information 01";
CM_ SG_ 527 TSSVOI02 "FCM Voice information 02";
CM_ SG_ 527 VNUSGACC "Voice Nortification Usage(ACC)";
CM_ SG_ 527 VNUSGDES "Voice Nortification Usage(DES)";
CM_ SG_ 527 VNUSGISA "Voice Nortification Usage(ISA)";
CM_ SG_ 527 VNUSGTMN "Voice Nortification Usage(TMN)";
CM_ SG_ 527 VNUSGPCS "Voice Nortification Usage(PCS)";
CM_ SG_ 527 TSSVOI08 "FCM Voice information 08";
CM_ SG_ 527 DM_DISPC "EDSS display request for multimedia";
CM_ BO_ 601 "Reserve";
CM_ SG_ 601 DREC_S "Driver monitor image record status";
CM_ SG_ 601 LDAACTL "Left Side LDA activation display ";
CM_ SG_ 601 LDAACTR "Right Side LDA activation display ";
CM_ BO_ 168 "Reserve";
CM_ SG_ 168 AVSTRGR "Body control request";
CM_ SG_ 168 PBATRGR "Pre crash brake assist flag";
CM_ SG_ 168 PCSALM "PCS alarm buzzer";
CM_ BO_ 277 "Reserve";
CM_ SG_ 277 FWDFR_PT "FR composition with 4WD display";
CM_ SG_ 277 FWDFL_PT "FL composition with 4WD display";
CM_ SG_ 277 FWDRR_PT "RR composition with 4WD display";
CM_ SG_ 277 FWDRL_PT "RL composition with 4WD display";
CM_ SG_ 277 FWDREQ "request data with 4WD display";
CM_ SG_ 277 FWD_FLS "request data of FL D/S state display";
CM_ SG_ 277 FWD_FRS "request data of FR D/S state display";
CM_ SG_ 277 FWD_RLS "request data of RL D/S state display";
CM_ SG_ 277 FWD_RRS "request data of RR D/S state display";
CM_ SG_ 277 FWD_PSF "request data of Fr P/S state display";
CM_ SG_ 277 FWD_PSR "request data of Rr P/S state display";
CM_ SG_ 277 FWD_FTA "request data of Fr T/A state display";
CM_ SG_ 277 FWD_RTA "request data of Rr T/A state display";
CM_ SG_ 277 FWD_CDL "request data of Center DL state display";
CM_ SG_ 277 PSF_DISP "request data of Fr P/S unit display";
CM_ SG_ 277 PSR_DISP "request data of Rr P/S unit display";
CM_ SG_ 277 CDL_DISP "request data of Center DL unit display";
CM_ SG_ 277 MGR_DISP "request data with E-Four unit display ";
CM_ BO_ 1172 "Reserve";
CM_ SG_ 1172 LVNEQPD "LVN equipped information";
CM_ SG_ 1172 LVNINDF "LVN indication request flag";
CM_ SG_ 1172 LVNBUZF "LVN buzzer request";
CM_ SG_ 1172 TMNSEQPD "TMN(signal) equipped information";
CM_ SG_ 1172 TMNSIND "TMN(signal) indication request flag";
CM_ SG_ 1172 TMNVSET "TMN(vehicle) notice setting";
CM_ SG_ 1172 TMNSSET "TMN(signal) notice setting";
CM_ BO_ 1321 "Reserve";
CM_ SG_ 1321 SPBZ_OPE "Speed limit sign change buzzer SW operation";
CM_ BO_ 589 "Reserve";
CM_ SG_ 589 VRAPMSWS "Voice Recognition Approval SW_Security";
CM_ SG_ 589 FV24D "MET1S44 Freshness Value";
CM_ SG_ 589 KZK24D "MET1S44 KZKValue";
CM_ BO_ 855 "Reserve";
CM_ SG_ 855 METSPDIS "Driving support mode display status";
CM_ SG_ 855 LCASGMSW "LCA sugestion ON/OFF";
CM_ SG_ 855 LCASGAPR "LCA suggest approval";
CM_ SG_ 855 IDAMSW "IDA main ON/OFF switching";
CM_ SG_ 855 IDASESW "IDA sensitivity switching";
CM_ SG_ 855 BSD_SMSB "BSM buzzer alert ON/OFF";
CM_ SG_ 855 BSD_SMSS "BSM Support Method Status SW";
CM_ SG_ 855 RSR_TIM "BSM Timing adjustment SW";
CM_ SG_ 855 DOAM_SW "DOA main ON/OFF switching";
CM_ SG_ 855 PKSSVOL "PKSS SOUND VOLUME SW";
CM_ SG_ 855 LDASW "LDA Main Switch ON/OFF";
CM_ SG_ 855 DOAM_TIM "DOA Timing adjustment SW";
CM_ SG_ 855 BSMM_ILV "BSM Indicator Luminance adjustment Value";
CM_ SG_ 855 RTAN_TIM "RTAN Timing adjustment SW";
CM_ SG_ 855 RTAN_MSW "RTAN ON/OFF";
CM_ SG_ 855 PLUSSW "PLUS SUPPORT Disp Off Operation SW";
CM_ SG_ 855 SDGMSW "SDG main ON/OFF switching";
CM_ SG_ 855 PDAMSW "PDA main ON/OFF switching";
CM_ SG_ 855 RSA_NEM "RSA No Entry sign Caution method SW";
CM_ SG_ 855 RSA_LSM "RSA No Entry/Red signal Caution method SW";
CM_ SG_ 855 PMARSW "PMAR SW OPERATION";
CM_ SG_ 855 ADDS_MSW "ADDS ON/OFF";
CM_ SG_ 855 LDAAMSW "LDA Mode SW";
CM_ SG_ 855 TMNVSW "TMN(vehicle) setting switch";
CM_ SG_ 855 TMNSSW "TMN(signal) setting switch";
CM_ SG_ 855 DM_SW_A2 "dmc warning ON/OFF";
CM_ SG_ 855 DISSUISW "DMC situation alert ON/OFF";
CM_ SG_ 855 SLDSSW "Speed limiter default ON setting switch";
CM_ SG_ 855 SLSSSSW "Speed limiter sign speed setting switch";
CM_ SG_ 855 LTASSWOP "LTA software switch operation";
CM_ SG_ 855 HMIAMBOP "HMI ambient switch operation";
CM_ SG_ 855 ADINITSW "ADAS setting initialization SW operation";
CM_ SG_ 855 ADSAFESW "ADAS setting safety SW operation";
CM_ SG_ 855 ADALOFSW "ADAS setting all off SW operation";
CM_ SG_ 855 ADMUTESW "ADAS setting mute SW operation";
CM_ SG_ 855 ADMDSTSW "ADAS setting modest SW operation";
CM_ SG_ 855 STRSWAP "AP Steering Switch";
CM_ SG_ 855 USMSESW "DA Support Level switching";
CM_ SG_ 855 SDGSESW "SDG sensitivity switching";
CM_ SG_ 855 ADADDRSW "Advanced Drive Customization operation FB (Advanced Drive)";
CM_ SG_ 855 ADOTASSW "Advanced Drive Customization operation FB (Overtake Assistance)";
CM_ SG_ 855 ADSTMUSW "Advanced Drive Customization operation FB (Stereo Mute)";
CM_ SG_ 855 ADAUNFSW "Advanced Drive Customization operation FB (Audio Notification Frequency)";
CM_ SG_ 855 ADNTLVSW "Advanced Drive Customization operation FB (Notification Level)";
CM_ SG_ 855 ADDSLVSW "Advanced Drive Customization operation FB (Driving Support Level)";
CM_ SG_ 855 ADVOCTSW "Advanced Drive Customization operation FB (Voice Control)";
CM_ SG_ 855 ADSLDSSW "Advanced Drive Customization operation FB (Driving support level decrease notification sound)";
CM_ SG_ 855 ADDMCRSW "Advanced Drive Customization operation FB (Driver Monitor Camera Recording)";
CM_ SG_ 855 ADSEGDSW "Advanced Drive Customization operation FB (Surrounding Environment Graphic Display)";
CM_ SG_ 855 ADSVSSSW "Advanced Drive Customization operation FB (Setting Vehicle Speed Suggestion)";
CM_ SG_ 855 ADCVVSSW "Advanced Drive Customization operation FB (Correction Value for Setting Vehicle Speed suggestion)";
CM_ SG_ 855 AECOSWBB "ADAS-ECO app ON/OFF switching";
CM_ SG_ 855 ACCSSOSW "Offset of sign speed setting SW";
CM_ SG_ 855 ACCRACSW "RSA cooperation setting SW";
CM_ SG_ 855 ACCROSSW "Restraint of overtaking setting SW";
CM_ SG_ 855 AHSACTSW "AHS ON/OFF Function customization SW press signal";
CM_ SG_ 855 AHBACTSW "AHB ON/OFF Function customization SW press signal";
CM_ SG_ 855 ACCACLSW "Cruise acceleration setting SW";
CM_ SG_ 855 ACCSPMSW "Speed management setting SW";
CM_ SG_ 855 AECOSW "ADAS ECO SW operation";
CM_ SG_ 855 USMMAIN "URSM main SW";
CM_ SG_ 855 SLSSOSW "Speed limiter offset of sign speed setting SW";
CM_ SG_ 855 METMDSEL "Driving support mode SW operation";
CM_ SG_ 855 ACCDSTSW "Following distance time SW operation";
CM_ SG_ 855 DOTICSTS "Driving Operation Transition request IC status";
CM_ SG_ 855 CTAMSW "FCTA ON/OFF";
CM_ SG_ 855 ACCGCRSW "ACC support for Signals and intersections SW";
CM_ SG_ 855 METMSPDI "Next speed sign display status";
CM_ SG_ 855 RTWMSW "Right/Left turn warning ON/OFF";
CM_ SG_ 855 AHSSDESW "AHS Shading Edge customization SW press signal";
CM_ SG_ 855 AHSSWVSW "AHS Swivel Function customization SW press signal";
CM_ SG_ 855 METMDREJ "Rejection information for MODE display requests";
CM_ SG_ 855 CCSMDMSW "CCS MODE SW";
CM_ SG_ 855 ERMSW "Adaptive Cruise Eco Run Mode SW";
CM_ SG_ 855 TRA_SW "User Input Trailer ADAS ON OFF";
CM_ SG_ 855 TRLC_YN "Meter Trailer Command Yes/No";
CM_ BO_ 73 "Reserve";
CM_ SG_ 73 RTQRRLMG "actual rear regenerative torque (high precision)";
CM_ SG_ 73 RTQFRLMG "actual front regenerative torque (high precision)";
CM_ BO_ 756 "Reserve";
CM_ SG_ 756 E_CRC2F4 "PDS1S01_E2E_CRC";
CM_ SG_ 756 E_CNT2F4 "PDS1S01_E2E_CNT";
CM_ SG_ 756 AB "Airbag warning lamp control request";
CM_ SG_ 756 PUH_FLG "PUH setting information";
CM_ SG_ 756 PDS_WL "Pedestrian Protection System Warning Lamp ON request";
CM_ BO_ 690 "Reserve";
CM_ SG_ 690 SIDPWC0 "WiFi SSID PWC No.0";
CM_ SG_ 690 SIDPWC1 "WiFi SSID PWC No.1";
CM_ SG_ 690 SIDPWC2 "WiFi SSID PWC No.2";
CM_ SG_ 690 SIDPWC3 "WiFi SSID PWC No.3";
CM_ SG_ 690 SIDPWC4 "WiFi SSID PWC No.4";
CM_ SG_ 690 SIDPWC5 "WiFi SSID PWC No.5";
CM_ SG_ 690 SIDPWC6 "WiFi SSID PWC No.6";
CM_ SG_ 690 SIDPWC7 "WiFi SSID PWC No.7";
CM_ SG_ 690 SIDPWC8 "WiFi SSID PWC No.8";
CM_ SG_ 690 SIDPWC9 "WiFi SSID PWC No.9";
CM_ SG_ 690 SIDPWC10 "WiFi SSID PWC No.10";
CM_ SG_ 690 SIDPWC11 "WiFi SSID PWC No.11";
CM_ SG_ 690 SIDPWC12 "WiFi SSID PWC No.12";
CM_ SG_ 690 SIDPWC13 "WiFi SSID PWC No.13";
CM_ SG_ 690 SIDPWC14 "WiFi SSID PWC No.14";
CM_ SG_ 690 SIDPWC15 "WiFi SSID PWC No.15";
CM_ SG_ 690 SIDPWC16 "WiFi SSID PWC No.16";
CM_ SG_ 690 SIDPWC17 "WiFi SSID PWC No.17";
CM_ SG_ 690 SIDPWC18 "WiFi SSID PWC No.18";
CM_ SG_ 690 SIDPWC19 "WiFi SSID PWC No.19";
CM_ SG_ 690 SIDPWC20 "WiFi SSID PWC No.20";
CM_ SG_ 690 SIDPWC21 "WiFi SSID PWC No.21";
CM_ SG_ 690 SIDPWC22 "WiFi SSID PWC No.22";
CM_ SG_ 690 SIDPWC23 "WiFi SSID PWC No.23";
CM_ SG_ 690 SIDPWC24 "WiFi SSID PWC No.24";
CM_ SG_ 690 SIDPWC25 "WiFi SSID PWC No.25";
CM_ SG_ 690 SIDPWC26 "WiFi SSID PWC No.26";
CM_ SG_ 690 SIDPWC27 "WiFi SSID PWC No.27";
CM_ SG_ 690 SIDPWC28 "WiFi SSID PWC No.28";
CM_ SG_ 690 SIDPWC29 "WiFi SSID PWC No.29";
CM_ SG_ 690 SIDPWC30 "WiFi SSID PWC No.30";
CM_ SG_ 690 SIDPWC31 "WiFi SSID PWC No.31";
CM_ BO_ 560 "Reserve";
CM_ SG_ 560 MV_FL "Moving object display Fr left";
CM_ SG_ 560 MV_FR "Moving object display Fr right";
CM_ SG_ 560 MV_RL "Moving object display Rr left";
CM_ SG_ 560 MV_RR "Moving object display Rr right";
CM_ SG_ 560 MV_FLS "Moving object display Fr left side";
CM_ SG_ 560 MV_FRS "Moving object display Fr right side";
CM_ SG_ 560 MV_RLS "Moving object display Rr left side";
CM_ SG_ 560 MV_RRS "Moving object display Rr right side";
CM_ SG_ 560 MV_FC "Moving object display Fr center";
CM_ SG_ 560 MV_RC "Moving object display Rr center";
CM_ SG_ 560 FRS_POS "FRONT SIDE RIGHT DETECTION POSITION";
CM_ SG_ 560 FLS_POS "FRONT SIDE LEFT DETECTION POSITION";
CM_ SG_ 560 FRS_WRN "FRONT SIDE RIGHT WARNING";
CM_ SG_ 560 RRS_POS "REAR SIDE RIGHT DETECTION POSITION";
CM_ SG_ 560 RLS_POS "REAR SIDE LEFT DETECTION POSITION";
CM_ SG_ 560 FLS_WRN "FRONT SIDE LEFT WARNING";
CM_ SG_ 560 RRS_WRN "REAR SIDE RIGHT WARNING";
CM_ SG_ 560 RLS_WRN "REAR SIDE LEFT WARNING";
CM_ BO_ 475 "Reserve";
CM_ SG_ 475 MSG_SBWF "SBW error status display demand";
CM_ SG_ 475 MSG_LBAT "low battery fail information display demand";
CM_ SG_ 475 MSG_PREQ "P request  display demand when emergency shut down";
CM_ SG_ 475 MSG_PSWF "P-SW fail display demand";
CM_ SG_ 475 MSG_ACTF "P-ACT fail display demand";
CM_ SG_ 475 VNHLDEN "N hold enable";
CM_ SG_ 475 VNHLDST "N hold status";
CM_ BO_ 267 "Reserve";
CM_ SG_ 267 FRVH "FR wheel Height Value";
CM_ SG_ 267 FLVH "FL wheel Height Value";
CM_ SG_ 267 RRVH "RR wheel Height Value";
CM_ SG_ 267 RLVH "RL wheel Height Value";
CM_ BO_ 766 "Reserve";
CM_ SG_ 766 AVSEXT "AVS system Information";
CM_ SG_ 766 AVSMINF "AVS Multi Information Request";
CM_ SG_ 766 AVSNI "AVS collaborated with NAVI information";
CM_ SG_ 766 DLR_HSID "Harsh Deletion Request";
CM_ SG_ 766 LAR_HS "Harsh Learnning Request";
CM_ SG_ 766 STBEXT "SDM Exist Information";
CM_ SG_ 766 STBLMP "SDM Operation State LAMP";
CM_ SG_ 766 KSSMINF "MID Display Request";
CM_ SG_ 766 KSSEXT "KSS Exist Information";
CM_ SG_ 766 LKSS0 "KDSS LAMP";
CM_ SG_ 766 ASTBEXT "Active Stabilizer Function Existence";
CM_ SG_ 766 ASTBMINF "Active Stabilizer Fail Information";
CM_ BO_ 672 "Reserve";
CM_ SG_ 672 TRABUZ "TRA Buzzer Request";
CM_ SG_ 672 TCSL_ID "Currently Selected Trailer ID";
CM_ SG_ 672 ATD_DEC "Auto Trailer Detection (ATD) Status";
CM_ SG_ 672 TCSL_TTP "Currently Selected Trailer Type";
CM_ SG_ 672 TCSL_TW "Currently Selected Trailer Weight";
CM_ SG_ 672 TCSL_MI "Currently Selected Mileage";
CM_ BO_ 160 "Reserve";
CM_ SG_ 160 TCDP_ID "Currently Displayed Trailer ID";
CM_ SG_ 160 TCDP_LM "Currently Displayed Length Auto or Manual Mode";
CM_ SG_ 160 TCDP_HLM "Currently Displayed Hitch Length Auto or Manual Mode";
CM_ SG_ 160 TCDP_L "Currently Displayed Trailer Length";
CM_ SG_ 160 TCDP_HL "Currently Displayed Hitch Length";
CM_ SG_ 160 TCDP_WB "Currently Displayed Beam Length";
CM_ SG_ 160 TCDP_HTP "Currently Displayed Hitch Type";
CM_ SG_ 160 TCDP_NAX "Currently Displayed Number of Axles";
CM_ SG_ 160 TCDP_WBM "Currently Displayed Beam Length Auto or Manual Mode";
CM_ SG_ 160 TCDP_W "Currently Displayed Trailer Width";
CM_ SG_ 160 TID_SYNC "Trailer IDs used in ADAS";
CM_ SG_ 160 TRA_NACK "Trailer Name Acknowledgement";
CM_ SG_ 160 TCDP_BTP "Currently Displayed Trailer Brake Type";
CM_ SG_ 160 TRA_GAR "Trailer Garage popup Open Command";
CM_ SG_ 160 TCDP_WM "Currently Displayed Trailer Width Auto or Manual Mode";
CM_ SG_ 160 TBC_EQ "Trailer Brake Equipment Flag";
CM_ SG_ 160 TCDP_TTP "Currently Displayed Trailer Type";
CM_ SG_ 160 TG_VAR "Trailer Garage Variant";
CM_ SG_ 160 TCDP_TW "Currently Displayed Trailer Weight";
CM_ SG_ 160 TCDP_TWM "Currently Displayed Trailer Weight Auto or Manual Mode";
CM_ SG_ 160 TCDP_MI "Currently Displayed Mileage";
CM_ BO_ 1188 "Reserve";
CM_ SG_ 1188 DVGR01 "Drive Recorder VGR01";
CM_ SG_ 1188 DVGR02 "Drive Recorder VGR01";
CM_ SG_ 1188 DVGR03 "Drive Recorder VGR01";
CM_ SG_ 1188 DVGR04 "Drive Recorder VGR01";
CM_ SG_ 1188 DVGR05 "Drive Recorder VGR01";
CM_ SG_ 1188 DVGR06 "Drive Recorder VGR01";
CM_ SG_ 1188 DVGR07 "Drive Recorder VGR01";
CM_ SG_ 1188 DVGR08 "Drive Recorder VGR08";
CM_ SG_ 1188 DVGR09 "Drive Recorder VGR09";
CM_ SG_ 1188 DVGR10 "Drive Recorder VGR09";
CM_ SG_ 1188 DVGR11 "Drive Recorder VGR09";
CM_ SG_ 1188 DVGR12 "Drive Recorder VGR09";
CM_ SG_ 1188 DVGR13 "Drive Recorder VGR09";
CM_ SG_ 1188 DVGR14 "Drive Recorder VGR09";
CM_ SG_ 1188 DVGR15 "Drive Recorder VGR09";
CM_ SG_ 1188 DVGR16 "Drive Recorder VGR09";
CM_ SG_ 1188 DVGR17 "Drive Recorder VGR09";
CM_ SG_ 1188 DVGR18 "Drive Recorder VGR09";
CM_ SG_ 1188 DVGR19 "Drive Recorder VGR09";
CM_ SG_ 1188 DVGR20 "Drive Recorder VGR09";
CM_ SG_ 1188 DVGR21 "Drive Recorder VGR09";
CM_ SG_ 1188 DVGR22 "Drive Recorder VGR09";
CM_ SG_ 1188 DVGR23 "Drive Recorder VGR09";
CM_ SG_ 1188 DVGR24 "Drive Recorder VGR09";
CM_ SG_ 1188 DVGR25 "Drive Recorder VGR09";
CM_ SG_ 1188 DVGR26 "Drive Recorder VGR09";
CM_ SG_ 1188 DVGR27 "Drive Recorder VGR09";
CM_ SG_ 1188 DVGR28 "Drive Recorder VGR09";
CM_ SG_ 1188 DVGR29 "Drive Recorder VGR09";
CM_ SG_ 1188 DVGR30 "Drive Recorder VGR09";
CM_ SG_ 1188 DVGR31 "Drive Recorder VGR09";
CM_ SG_ 1188 DVGR32 "Drive Recorder VGR32";
CM_ BO_ 1185 "Reserve";
CM_ SG_ 1185 DRVSCID "Drive Recorder VSC ID";
CM_ SG_ 1185 DRVSC02 "Drive Recorder VSC02";
CM_ SG_ 1185 DRVSC03 "Drive Recorder VSC03";
CM_ SG_ 1185 DRVSC04 "Drive Recorder VSC04";
CM_ SG_ 1185 DRVSC05 "Drive Recorder VSC05";
CM_ SG_ 1185 DRVSC06 "Drive Recorder VSC06";
CM_ SG_ 1185 DRVSC07 "Drive Recorder VSC07";
CM_ SG_ 1185 DRVSC08 "Drive Recorder VSC08";
CM_ SG_ 1185 DRVSC11 "Drive Recorder VSC11";
CM_ SG_ 1185 DRVSC12 "Drive Recorder VSC12";
CM_ SG_ 1185 DRVSC13 "Drive Recorder VSC13";
CM_ SG_ 1185 DRVSC14 "Drive Recorder VSC14";
CM_ SG_ 1185 DRVSC15 "Drive Recorder VSC15";
CM_ SG_ 1185 DRVSC16 "Drive Recorder VSC16";
CM_ SG_ 1185 DRVSC17 "Drive Recorder VSC17";
CM_ SG_ 1185 DRVSC18 "Drive Recorder VSC18";
CM_ SG_ 1185 DRVSC21 "Drive Recorder VSC21";
CM_ SG_ 1185 DRVSC22 "Drive Recorder VSC22";
CM_ SG_ 1185 DRVSC23 "Drive Recorder VSC23";
CM_ SG_ 1185 DRVSC24 "Drive Recorder VSC24";
CM_ SG_ 1185 DRVSC25 "Drive Recorder VSC25";
CM_ SG_ 1185 DRVSC26 "Drive Recorder VSC26";
CM_ SG_ 1185 DRVSC27 "Drive Recorder VSC27";
CM_ SG_ 1185 DRVSC28 "Drive Recorder VSC28";
CM_ SG_ 1185 DREPB01 "Drive Recorder EPB01";
CM_ SG_ 1185 DREPB02 "Drive Recorder EPB02";
CM_ SG_ 1185 DREPB03 "Drive Recorder EPB03";
CM_ SG_ 1185 DREPB04 "Drive Recorder EPB04";
CM_ SG_ 1185 DREPB05 "Drive Recorder EPB05";
CM_ SG_ 1185 DREPB06 "Drive Recorder EPB06";
CM_ SG_ 1185 DREPB07 "Drive Recorder EPB07";
CM_ SG_ 1185 DREPB08 "Drive Recorder EPB08";
CM_ BO_ 610 "Reserve";
CM_ SG_ 610 PWIINFO "PWI Type infomation";
CM_ SG_ 610 RURESIS1 "Running resistance (Both inertia and slope are included)";
CM_ SG_ 610 RURESIS2 "Running resistance (Neither inertia nor slope is included)";
CM_ SG_ 610 STADJUST "Steering wheel adjustment";
CM_ SG_ 610 FRFRICST "FR wheel friction status";
CM_ SG_ 610 FLFRICST "FL wheel friction status";
CM_ SG_ 610 RRFRICST "RR wheel friction status";
CM_ SG_ 610 RLFRICST "RL wheel friction status ";
CM_ SG_ 610 DACSSWEX "Existence of DAC software switch";
BA_DEF_ BO_  "GenMsgILSupport" ENUM  "No","Yes";
BA_DEF_ BO_  "GenMsgSendType" ENUM  "Cyclic","NotUsed","NotUsed","NotUsed","NotUsed","NotUsed","NotUsed","NotUsed","NoMsgSendType";
BA_DEF_ SG_  "GenSigSendType" ENUM  "Cyclic","OnWrite","OnWriteWithRepetition","OnChange","OnChangeWithRepetition","NotUsed","NotUsed","NoSigSendType";
BA_DEF_ BO_  "GenMsgCycleTime" INT 0 65535;
BA_DEF_ SG_  "GenSigStartValue" FLOAT 0 100000000000;
BA_DEF_ BO_  "GenMsgStartDelayTime" INT 0 100000;
BA_DEF_ BO_  "VFrameFormat" ENUM  "StandardCAN","ExtendedCAN","reserved","reserved","reserved","reserved","reserved","reserved","reserved","reserved","reserved","reserved","reserved","reserved","StandardCAN_FD","ExtendedCAN_FD";
BA_DEF_ BO_  "CANFD_BRS" ENUM  "0","1";
BA_DEF_ BO_  "DiagConnection" HEX 0 65535;
BA_DEF_DEF_  "GenMsgILSupport" "No";
BA_DEF_DEF_  "GenMsgSendType" "NoMsgSendType";
BA_DEF_DEF_  "GenSigSendType" "NoSigSendType";
BA_DEF_DEF_  "GenMsgCycleTime" 0;
BA_DEF_DEF_  "GenSigStartValue" 0;
BA_DEF_DEF_  "GenMsgStartDelayTime" 0;
BA_DEF_DEF_  "VFrameFormat" "";
BA_DEF_DEF_  "CANFD_BRS" "1";
BA_DEF_DEF_  "DiagConnection" 3000.00004970533;
BA_ "GenMsgCycleTime" BO_ 802 1000;
BA_ "GenMsgSendType" BO_ 802 0;
BA_ "GenMsgILSupport" BO_ 802 1;
BA_ "GenMsgStartDelayTime" BO_ 802 184;
BA_ "VFrameFormat" BO_ 802 14;
BA_ "GenMsgCycleTime" BO_ 321 100;
BA_ "GenMsgSendType" BO_ 321 0;
BA_ "GenMsgILSupport" BO_ 321 1;
BA_ "GenMsgStartDelayTime" BO_ 321 188;
BA_ "VFrameFormat" BO_ 321 14;
BA_ "GenMsgCycleTime" BO_ 743 1000;
BA_ "GenMsgSendType" BO_ 743 0;
BA_ "GenMsgILSupport" BO_ 743 1;
BA_ "GenMsgStartDelayTime" BO_ 743 192;
BA_ "VFrameFormat" BO_ 743 14;
BA_ "GenMsgCycleTime" BO_ 744 1000;
BA_ "GenMsgSendType" BO_ 744 0;
BA_ "GenMsgILSupport" BO_ 744 1;
BA_ "GenMsgStartDelayTime" BO_ 744 196;
BA_ "VFrameFormat" BO_ 744 14;
BA_ "GenMsgCycleTime" BO_ 622 1000;
BA_ "GenMsgSendType" BO_ 622 0;
BA_ "GenMsgILSupport" BO_ 622 1;
BA_ "VFrameFormat" BO_ 622 14;
BA_ "GenMsgCycleTime" BO_ 243 50;
BA_ "GenMsgSendType" BO_ 243 0;
BA_ "GenMsgILSupport" BO_ 243 1;
BA_ "VFrameFormat" BO_ 243 14;
BA_ "GenMsgCycleTime" BO_ 442 200;
BA_ "GenMsgSendType" BO_ 442 0;
BA_ "GenMsgILSupport" BO_ 442 1;
BA_ "VFrameFormat" BO_ 442 14;
BA_ "GenMsgCycleTime" BO_ 495 500;
BA_ "GenMsgSendType" BO_ 495 0;
BA_ "GenMsgILSupport" BO_ 495 1;
BA_ "VFrameFormat" BO_ 495 14;
BA_ "GenMsgCycleTime" BO_ 626 1000;
BA_ "GenMsgSendType" BO_ 626 0;
BA_ "GenMsgILSupport" BO_ 626 1;
BA_ "VFrameFormat" BO_ 626 14;
BA_ "GenMsgCycleTime" BO_ 633 1000;
BA_ "GenMsgSendType" BO_ 633 0;
BA_ "GenMsgILSupport" BO_ 633 1;
BA_ "VFrameFormat" BO_ 633 14;
BA_ "GenMsgCycleTime" BO_ 1011 1008;
BA_ "GenMsgSendType" BO_ 1011 0;
BA_ "GenMsgILSupport" BO_ 1011 1;
BA_ "VFrameFormat" BO_ 1011 14;
BA_ "GenMsgCycleTime" BO_ 1389 1000;
BA_ "GenMsgSendType" BO_ 1389 0;
BA_ "GenMsgILSupport" BO_ 1389 1;
BA_ "GenMsgStartDelayTime" BO_ 1389 200;
BA_ "VFrameFormat" BO_ 1389 14;
BA_ "GenMsgCycleTime" BO_ 169 25;
BA_ "GenMsgSendType" BO_ 169 0;
BA_ "GenMsgILSupport" BO_ 169 1;
BA_ "VFrameFormat" BO_ 169 14;
BA_ "GenMsgCycleTime" BO_ 1082 1000;
BA_ "GenMsgSendType" BO_ 1082 0;
BA_ "GenMsgILSupport" BO_ 1082 1;
BA_ "VFrameFormat" BO_ 1082 14;
BA_ "GenMsgCycleTime" BO_ 987 1000;
BA_ "GenMsgSendType" BO_ 987 0;
BA_ "GenMsgILSupport" BO_ 987 1;
BA_ "VFrameFormat" BO_ 987 14;
BA_ "GenMsgCycleTime" BO_ 988 1000;
BA_ "GenMsgSendType" BO_ 988 0;
BA_ "GenMsgILSupport" BO_ 988 1;
BA_ "VFrameFormat" BO_ 988 14;
BA_ "GenMsgCycleTime" BO_ 637 1000;
BA_ "GenMsgSendType" BO_ 637 0;
BA_ "GenMsgILSupport" BO_ 637 1;
BA_ "VFrameFormat" BO_ 637 14;
BA_ "GenMsgCycleTime" BO_ 299 100;
BA_ "GenMsgSendType" BO_ 299 0;
BA_ "GenMsgILSupport" BO_ 299 1;
BA_ "VFrameFormat" BO_ 299 14;
BA_ "GenMsgCycleTime" BO_ 537 1000;
BA_ "GenMsgSendType" BO_ 537 0;
BA_ "GenMsgILSupport" BO_ 537 1;
BA_ "VFrameFormat" BO_ 537 14;
BA_ "GenMsgCycleTime" BO_ 673 1000;
BA_ "GenMsgSendType" BO_ 673 0;
BA_ "GenMsgILSupport" BO_ 673 1;
BA_ "VFrameFormat" BO_ 673 14;
BA_ "GenMsgCycleTime" BO_ 980 3000;
BA_ "GenMsgSendType" BO_ 980 0;
BA_ "GenMsgILSupport" BO_ 980 1;
BA_ "VFrameFormat" BO_ 980 14;
BA_ "GenMsgCycleTime" BO_ 126 16;
BA_ "GenMsgSendType" BO_ 126 0;
BA_ "GenMsgILSupport" BO_ 126 1;
BA_ "VFrameFormat" BO_ 126 14;
BA_ "GenMsgCycleTime" BO_ 165 24;
BA_ "GenMsgSendType" BO_ 165 0;
BA_ "GenMsgILSupport" BO_ 165 1;
BA_ "VFrameFormat" BO_ 165 14;
BA_ "GenMsgCycleTime" BO_ 679 1000;
BA_ "GenMsgSendType" BO_ 679 0;
BA_ "GenMsgILSupport" BO_ 679 1;
BA_ "VFrameFormat" BO_ 679 14;
BA_ "GenMsgCycleTime" BO_ 680 1000;
BA_ "GenMsgSendType" BO_ 680 0;
BA_ "GenMsgILSupport" BO_ 680 1;
BA_ "VFrameFormat" BO_ 680 14;
BA_ "GenMsgCycleTime" BO_ 734 1000;
BA_ "GenMsgSendType" BO_ 734 0;
BA_ "GenMsgILSupport" BO_ 734 1;
BA_ "VFrameFormat" BO_ 734 14;
BA_ "GenMsgCycleTime" BO_ 166 24;
BA_ "GenMsgSendType" BO_ 166 0;
BA_ "GenMsgILSupport" BO_ 166 1;
BA_ "VFrameFormat" BO_ 166 14;
BA_ "GenMsgCycleTime" BO_ 117 16;
BA_ "GenMsgSendType" BO_ 117 0;
BA_ "GenMsgILSupport" BO_ 117 1;
BA_ "VFrameFormat" BO_ 117 14;
BA_ "GenMsgCycleTime" BO_ 161 24;
BA_ "GenMsgSendType" BO_ 161 0;
BA_ "GenMsgILSupport" BO_ 161 1;
BA_ "VFrameFormat" BO_ 161 14;
BA_ "GenMsgCycleTime" BO_ 1523 100;
BA_ "GenMsgSendType" BO_ 1523 0;
BA_ "GenMsgILSupport" BO_ 1523 1;
BA_ "VFrameFormat" BO_ 1523 14;
BA_ "GenMsgCycleTime" BO_ 1524 1000;
BA_ "GenMsgSendType" BO_ 1524 0;
BA_ "GenMsgILSupport" BO_ 1524 1;
BA_ "VFrameFormat" BO_ 1524 14;
BA_ "GenMsgCycleTime" BO_ 1177 500;
BA_ "GenMsgSendType" BO_ 1177 0;
BA_ "GenMsgILSupport" BO_ 1177 1;
BA_ "VFrameFormat" BO_ 1177 14;
BA_ "GenMsgCycleTime" BO_ 1178 500;
BA_ "GenMsgSendType" BO_ 1178 0;
BA_ "GenMsgILSupport" BO_ 1178 1;
BA_ "VFrameFormat" BO_ 1178 14;
BA_ "GenMsgCycleTime" BO_ 1179 500;
BA_ "GenMsgSendType" BO_ 1179 0;
BA_ "GenMsgILSupport" BO_ 1179 1;
BA_ "VFrameFormat" BO_ 1179 14;
BA_ "GenMsgCycleTime" BO_ 1181 500;
BA_ "GenMsgSendType" BO_ 1181 0;
BA_ "GenMsgILSupport" BO_ 1181 1;
BA_ "VFrameFormat" BO_ 1181 14;
BA_ "GenMsgCycleTime" BO_ 1192 500;
BA_ "GenMsgSendType" BO_ 1192 0;
BA_ "GenMsgILSupport" BO_ 1192 1;
BA_ "VFrameFormat" BO_ 1192 14;
BA_ "GenMsgCycleTime" BO_ 1198 500;
BA_ "GenMsgSendType" BO_ 1198 0;
BA_ "GenMsgILSupport" BO_ 1198 1;
BA_ "VFrameFormat" BO_ 1198 14;
BA_ "GenMsgCycleTime" BO_ 1199 500;
BA_ "GenMsgSendType" BO_ 1199 0;
BA_ "GenMsgILSupport" BO_ 1199 1;
BA_ "VFrameFormat" BO_ 1199 14;
BA_ "GenMsgCycleTime" BO_ 163 24;
BA_ "GenMsgSendType" BO_ 163 0;
BA_ "GenMsgILSupport" BO_ 163 1;
BA_ "VFrameFormat" BO_ 163 14;
BA_ "GenMsgCycleTime" BO_ 1417 1000;
BA_ "GenMsgSendType" BO_ 1417 0;
BA_ "GenMsgILSupport" BO_ 1417 1;
BA_ "VFrameFormat" BO_ 1417 14;
BA_ "GenMsgCycleTime" BO_ 1411 1500;
BA_ "GenMsgSendType" BO_ 1411 0;
BA_ "GenMsgILSupport" BO_ 1411 1;
BA_ "VFrameFormat" BO_ 1411 14;
BA_ "GenMsgCycleTime" BO_ 1187 500;
BA_ "GenMsgSendType" BO_ 1187 0;
BA_ "GenMsgILSupport" BO_ 1187 1;
BA_ "VFrameFormat" BO_ 1187 14;
BA_ "GenMsgCycleTime" BO_ 1526 500;
BA_ "GenMsgSendType" BO_ 1526 0;
BA_ "GenMsgILSupport" BO_ 1526 1;
BA_ "VFrameFormat" BO_ 1526 14;
BA_ "GenMsgCycleTime" BO_ 1521 1000;
BA_ "GenMsgSendType" BO_ 1521 0;
BA_ "GenMsgILSupport" BO_ 1521 1;
BA_ "VFrameFormat" BO_ 1521 14;
BA_ "GenMsgCycleTime" BO_ 1161 1000;
BA_ "GenMsgSendType" BO_ 1161 0;
BA_ "GenMsgILSupport" BO_ 1161 1;
BA_ "VFrameFormat" BO_ 1161 14;
BA_ "GenMsgCycleTime" BO_ 1163 1000;
BA_ "GenMsgSendType" BO_ 1163 0;
BA_ "GenMsgILSupport" BO_ 1163 1;
BA_ "VFrameFormat" BO_ 1163 14;
BA_ "GenMsgCycleTime" BO_ 594 1000;
BA_ "GenMsgSendType" BO_ 594 0;
BA_ "GenMsgILSupport" BO_ 594 1;
BA_ "VFrameFormat" BO_ 594 14;
BA_ "GenMsgCycleTime" BO_ 609 1000;
BA_ "GenMsgSendType" BO_ 609 0;
BA_ "GenMsgILSupport" BO_ 609 1;
BA_ "VFrameFormat" BO_ 609 14;
BA_ "GenMsgCycleTime" BO_ 628 1000;
BA_ "GenMsgSendType" BO_ 628 0;
BA_ "GenMsgILSupport" BO_ 628 1;
BA_ "VFrameFormat" BO_ 628 14;
BA_ "GenMsgCycleTime" BO_ 629 1000;
BA_ "GenMsgSendType" BO_ 629 0;
BA_ "GenMsgILSupport" BO_ 629 1;
BA_ "VFrameFormat" BO_ 629 14;
BA_ "GenMsgCycleTime" BO_ 630 1000;
BA_ "GenMsgSendType" BO_ 630 0;
BA_ "GenMsgILSupport" BO_ 630 1;
BA_ "VFrameFormat" BO_ 630 14;
BA_ "GenMsgCycleTime" BO_ 636 1000;
BA_ "GenMsgSendType" BO_ 636 0;
BA_ "GenMsgILSupport" BO_ 636 1;
BA_ "VFrameFormat" BO_ 636 14;
BA_ "GenMsgCycleTime" BO_ 650 1000;
BA_ "GenMsgSendType" BO_ 650 0;
BA_ "GenMsgILSupport" BO_ 650 1;
BA_ "VFrameFormat" BO_ 650 14;
BA_ "GenMsgCycleTime" BO_ 345 100;
BA_ "GenMsgSendType" BO_ 345 0;
BA_ "GenMsgILSupport" BO_ 345 1;
BA_ "VFrameFormat" BO_ 345 14;
BA_ "GenMsgCycleTime" BO_ 527 1000;
BA_ "GenMsgSendType" BO_ 527 0;
BA_ "GenMsgILSupport" BO_ 527 1;
BA_ "VFrameFormat" BO_ 527 14;
BA_ "GenMsgCycleTime" BO_ 601 1000;
BA_ "GenMsgSendType" BO_ 601 0;
BA_ "GenMsgILSupport" BO_ 601 1;
BA_ "VFrameFormat" BO_ 601 14;
BA_ "GenMsgCycleTime" BO_ 168 25;
BA_ "GenMsgSendType" BO_ 168 0;
BA_ "GenMsgILSupport" BO_ 168 1;
BA_ "VFrameFormat" BO_ 168 14;
BA_ "GenMsgCycleTime" BO_ 277 96;
BA_ "GenMsgSendType" BO_ 277 0;
BA_ "GenMsgILSupport" BO_ 277 1;
BA_ "VFrameFormat" BO_ 277 14;
BA_ "GenMsgCycleTime" BO_ 1172 1000;
BA_ "GenMsgSendType" BO_ 1172 0;
BA_ "GenMsgILSupport" BO_ 1172 1;
BA_ "VFrameFormat" BO_ 1172 14;
BA_ "GenMsgCycleTime" BO_ 1321 1000;
BA_ "GenMsgSendType" BO_ 1321 0;
BA_ "GenMsgILSupport" BO_ 1321 1;
BA_ "GenMsgStartDelayTime" BO_ 1321 204;
BA_ "VFrameFormat" BO_ 1321 14;
BA_ "GenMsgCycleTime" BO_ 589 1000;
BA_ "GenMsgSendType" BO_ 589 0;
BA_ "GenMsgILSupport" BO_ 589 1;
BA_ "GenMsgStartDelayTime" BO_ 589 208;
BA_ "VFrameFormat" BO_ 589 14;
BA_ "GenMsgCycleTime" BO_ 855 1000;
BA_ "GenMsgSendType" BO_ 855 0;
BA_ "GenMsgILSupport" BO_ 855 1;
BA_ "GenMsgStartDelayTime" BO_ 855 212;
BA_ "VFrameFormat" BO_ 855 14;
BA_ "GenMsgCycleTime" BO_ 73 8;
BA_ "GenMsgSendType" BO_ 73 0;
BA_ "GenMsgILSupport" BO_ 73 1;
BA_ "VFrameFormat" BO_ 73 14;
BA_ "GenMsgCycleTime" BO_ 756 1000;
BA_ "GenMsgSendType" BO_ 756 0;
BA_ "GenMsgILSupport" BO_ 756 1;
BA_ "VFrameFormat" BO_ 756 14;
BA_ "GenMsgCycleTime" BO_ 690 1000;
BA_ "GenMsgSendType" BO_ 690 0;
BA_ "GenMsgILSupport" BO_ 690 1;
BA_ "VFrameFormat" BO_ 690 14;
BA_ "GenMsgCycleTime" BO_ 560 1000;
BA_ "GenMsgSendType" BO_ 560 0;
BA_ "GenMsgILSupport" BO_ 560 1;
BA_ "VFrameFormat" BO_ 560 14;
BA_ "GenMsgCycleTime" BO_ 475 300;
BA_ "GenMsgSendType" BO_ 475 0;
BA_ "GenMsgILSupport" BO_ 475 1;
BA_ "VFrameFormat" BO_ 475 14;
BA_ "GenMsgCycleTime" BO_ 267 52;
BA_ "GenMsgSendType" BO_ 267 0;
BA_ "GenMsgILSupport" BO_ 267 1;
BA_ "VFrameFormat" BO_ 267 14;
BA_ "GenMsgCycleTime" BO_ 766 2000;
BA_ "GenMsgSendType" BO_ 766 0;
BA_ "GenMsgILSupport" BO_ 766 1;
BA_ "VFrameFormat" BO_ 766 14;
BA_ "GenMsgCycleTime" BO_ 672 1000;
BA_ "GenMsgSendType" BO_ 672 0;
BA_ "GenMsgILSupport" BO_ 672 1;
BA_ "VFrameFormat" BO_ 672 14;
BA_ "GenMsgCycleTime" BO_ 160 24;
BA_ "GenMsgSendType" BO_ 160 0;
BA_ "GenMsgILSupport" BO_ 160 1;
BA_ "VFrameFormat" BO_ 160 14;
BA_ "GenMsgCycleTime" BO_ 1188 500;
BA_ "GenMsgSendType" BO_ 1188 0;
BA_ "GenMsgILSupport" BO_ 1188 1;
BA_ "VFrameFormat" BO_ 1188 14;
BA_ "GenMsgCycleTime" BO_ 1185 500;
BA_ "GenMsgSendType" BO_ 1185 0;
BA_ "GenMsgILSupport" BO_ 1185 1;
BA_ "VFrameFormat" BO_ 1185 14;
BA_ "GenMsgCycleTime" BO_ 610 1000;
BA_ "GenMsgSendType" BO_ 610 0;
BA_ "GenMsgILSupport" BO_ 610 1;
BA_ "VFrameFormat" BO_ 610 14;
BA_ "GenSigSendType" SG_ 802 TRNSW1 3;
BA_ "GenSigSendType" SG_ 802 TRNSW2 3;
BA_ "GenSigSendType" SG_ 802 TRNSW3 3;
BA_ "GenSigSendType" SG_ 802 TRNSW4 3;
BA_ "GenSigSendType" SG_ 802 TRNSW5 3;
BA_ "GenSigSendType" SG_ 802 TRNSW6 3;
BA_ "GenSigSendType" SG_ 802 TRNSW7 3;
BA_ "GenSigSendType" SG_ 802 TRNSW8 3;
BA_ "GenSigSendType" SG_ 802 TRNPASW 3;
BA_ "GenSigSendType" SG_ 802 AIPWFRP 3;
BA_ "GenSigSendType" SG_ 802 AIPFBID 3;
BA_ "GenSigSendType" SG_ 802 AIPFB 3;
BA_ "GenSigSendType" SG_ 802 AIPLID1 3;
BA_ "GenSigSendType" SG_ 802 AIPL1 3;
BA_ "GenSigSendType" SG_ 802 AIPLID2 3;
BA_ "GenSigSendType" SG_ 802 AIPL2 3;
BA_ "GenSigSendType" SG_ 802 AIPLID3 3;
BA_ "GenSigSendType" SG_ 802 AIPL3 3;
BA_ "GenSigSendType" SG_ 802 AIPLID4 3;
BA_ "GenSigSendType" SG_ 802 AIPL4 3;
BA_ "GenSigSendType" SG_ 802 AIPLID5 3;
BA_ "GenSigSendType" SG_ 802 AIPL5 3;
BA_ "GenSigSendType" SG_ 802 AIPLID6 3;
BA_ "GenSigSendType" SG_ 802 AIPL6 3;
BA_ "GenSigSendType" SG_ 802 AIPLID7 3;
BA_ "GenSigSendType" SG_ 802 AIPL7 3;
BA_ "GenSigSendType" SG_ 802 AIPLID8 3;
BA_ "GenSigSendType" SG_ 802 AIPL8 3;
BA_ "GenSigSendType" SG_ 802 AIPRLHE 3;
BA_ "GenSigSendType" SG_ 802 AIPRLAD 3;
BA_ "GenSigSendType" SG_ 802 AIPNORE 3;
BA_ "GenSigSendType" SG_ 802 TRNICN 3;
BA_ "GenSigSendType" SG_ 802 TRNECN 3;
BA_ "GenSigSendType" SG_ 321 BSDCTSW 3;
BA_ "GenSigSendType" SG_ 321 NPSSWOP 3;
BA_ "GenSigSendType" SG_ 321 HNPCSTSW 3;
BA_ "GenSigSendType" SG_ 321 UNPCSTSW 3;
BA_ "GenSigSendType" SG_ 321 MNPCSTSW 3;
BA_ "GenSigSendType" SG_ 321 NPLCCSSW 3;
BA_ "GenSigSendType" SG_ 321 NPCS1SW 3;
BA_ "GenSigSendType" SG_ 321 NPCS2SW 3;
BA_ "GenSigSendType" SG_ 321 NPCS3SW 3;
BA_ "GenSigSendType" SG_ 321 NPDSSWOP 3;
BA_ "GenSigSendType" SG_ 321 CPPSSWOP 3;
BA_ "GenSigSendType" SG_ 321 PNPSTRQ 3;
BA_ "GenSigSendType" SG_ 321 PNPPARQ 3;
BA_ "GenSigSendType" SG_ 321 PNPCTRQ 3;
BA_ "GenSigSendType" SG_ 321 PNPSPRQ 3;
BA_ "GenSigSendType" SG_ 321 APSW 3;
BA_ "GenSigSendType" SG_ 321 LPNPSTRQ 3;
BA_ "GenSigSendType" SG_ 321 LPNPPARQ 3;
BA_ "GenSigSendType" SG_ 321 LPNPCTRQ 3;
BA_ "GenSigSendType" SG_ 321 LPNPSPRQ 3;
BA_ "GenSigSendType" SG_ 321 OPKENBL 3;
BA_ "GenSigSendType" SG_ 321 LPLNENBL 3;
BA_ "GenSigSendType" SG_ 321 LPSPENBL 3;
BA_ "GenSigSendType" SG_ 321 PNPSENBL 3;
BA_ "GenSigSendType" SG_ 321 DIS2OBST 3;
BA_ "GenSigSendType" SG_ 321 SPDMD 3;
BA_ "GenSigSendType" SG_ 321 PKOFFSET 3;
BA_ "GenSigSendType" SG_ 321 RPAENBL 3;
BA_ "GenSigSendType" SG_ 321 PKMTHSET 3;
BA_ "GenSigSendType" SG_ 321 PKINDIR 3;
BA_ "GenSigSendType" SG_ 321 PKOSET 3;
BA_ "GenSigSendType" SG_ 321 LANGMD 3;
BA_ "GenSigSendType" SG_ 321 APENBL 3;
BA_ "GenSigSendType" SG_ 321 LPNPENBL 3;
BA_ "GenSigSendType" SG_ 321 PNPENBL 3;
BA_ "GenSigSendType" SG_ 321 APASTRQ 3;
BA_ "GenSigSendType" SG_ 321 APAPARQ 3;
BA_ "GenSigSendType" SG_ 321 APACTRQ 3;
BA_ "GenSigSendType" SG_ 321 APASPRQ 3;
BA_ "GenSigSendType" SG_ 321 RPASTRQ 3;
BA_ "GenSigSendType" SG_ 321 RPAPARQ 3;
BA_ "GenSigSendType" SG_ 321 RPACTRQ 3;
BA_ "GenSigSendType" SG_ 321 RPASPRQ 3;
BA_ "GenSigSendType" SG_ 321 APRCPMD 3;
BA_ "GenSigSendType" SG_ 321 APOUTDIR 3;
BA_ "GenSigSendType" SG_ 321 APINDIR 3;
BA_ "GenSigSendType" SG_ 321 LPBYRCP 3;
BA_ "GenSigSendType" SG_ 321 RAENBL 3;
BA_ "GenSigSendType" SG_ 321 LPINSTMD 3;
BA_ "GenSigSendType" SG_ 321 LPINRDMD 3;
BA_ "GenSigSendType" SG_ 321 LPBYPAD 3;
BA_ "GenSigSendType" SG_ 321 LPISSET 3;
BA_ "GenSigSendType" SG_ 321 LPOSSET 3;
BA_ "GenSigSendType" SG_ 321 LPENDSET 3;
BA_ "GenSigSendType" SG_ 321 LPRESET2 3;
BA_ "GenSigSendType" SG_ 321 LPLNSTAT 3;
BA_ "GenSigSendType" SG_ 321 LPLNABT 3;
BA_ "GenSigSendType" SG_ 321 LPRTSET 3;
BA_ "GenSigSendType" SG_ 321 RASTRQ 3;
BA_ "GenSigSendType" SG_ 321 RAPARQ 3;
BA_ "GenSigSendType" SG_ 321 RACTRQ 3;
BA_ "GenSigSendType" SG_ 321 RASPRQ 3;
BA_ "GenSigSendType" SG_ 321 RASPEED 3;
BA_ "GenSigSendType" SG_ 321 WS_VISD 3;
BA_ "GenSigSendType" SG_ 321 WS_FTG 3;
BA_ "GenSigSendType" SG_ 321 WS_ABHB 3;
BA_ "GenSigSendType" SG_ 321 WS_APOS 3;
BA_ "GenSigStartValue" SG_ 622 D_TBMAX 25;
BA_ "GenSigStartValue" SG_ 622 D_TBMIN 25;
BA_ "GenSigStartValue" SG_ 442 D_TB0 25;
BA_ "GenSigStartValue" SG_ 442 D_TB1 25;
BA_ "GenSigStartValue" SG_ 442 D_TB2 25;
BA_ "GenSigStartValue" SG_ 442 D_TB3 25;
BA_ "GenSigStartValue" SG_ 442 D_TB4 25;
BA_ "GenSigStartValue" SG_ 442 D_TB5 25;
BA_ "GenSigStartValue" SG_ 442 D_TB6 25;
BA_ "GenSigSendType" SG_ 633 VBTINF 3;
BA_ "GenSigSendType" SG_ 633 SOCINF 3;
BA_ "GenSigSendType" SG_ 633 IBTINF 3;
BA_ "GenSigSendType" SG_ 633 TBTINF 3;
BA_ "GenSigSendType" SG_ 633 STPSOC 3;
BA_ "GenSigSendType" SG_ 633 STPVB 3;
BA_ "GenSigSendType" SG_ 633 STPCELV 3;
BA_ "GenSigSendType" SG_ 633 STPTMP 3;
BA_ "GenSigSendType" SG_ 1011 CMD_ONOF 3;
BA_ "GenSigSendType" SG_ 1011 CMD_S_SW 3;
BA_ "GenSigSendType" SG_ 1011 CMD_TTR 3;
BA_ "GenSigSendType" SG_ 1011 CAAINDIM 3;
BA_ "GenSigStartValue" SG_ 1389 CDCNID 205;
BA_ "GenSigSendType" SG_ 1082 ICSEXIST 3;
BA_ "GenSigSendType" SG_ 1082 ICSLAMP 3;
BA_ "GenSigSendType" SG_ 1082 CS_S_SW3 3;
BA_ "GenSigSendType" SG_ 1082 CSSW 3;
BA_ "GenSigSendType" SG_ 1082 ICSSW 3;
BA_ "GenSigSendType" SG_ 1082 CS_V_SW3 3;
BA_ "GenSigSendType" SG_ 1082 ICS_S_SW 3;
BA_ "GenSigSendType" SG_ 1082 ICSINFO 3;
BA_ "GenSigSendType" SG_ 1082 WACS_BUZ 3;
BA_ "GenSigSendType" SG_ 1082 WACSPMID 3;
BA_ "GenSigSendType" SG_ 1082 VNUSGCSR 3;
BA_ "GenSigSendType" SG_ 1082 PMARDISP 3;
BA_ "GenSigSendType" SG_ 1082 PMARVNRQ 3;
BA_ "GenSigSendType" SG_ 1082 PMARVNEX 3;
BA_ "GenSigSendType" SG_ 1082 PMARST 3;
BA_ "GenSigSendType" SG_ 1082 PMAREX 3;
BA_ "GenSigSendType" SG_ 1082 VOT3 3;
BA_ "GenSigSendType" SG_ 1082 PMARAVBL 3;
BA_ "GenSigSendType" SG_ 987 FR_POS 3;
BA_ "GenSigSendType" SG_ 987 FL_POS 3;
BA_ "GenSigSendType" SG_ 987 FR_WRN 3;
BA_ "GenSigSendType" SG_ 987 FRC_POS 3;
BA_ "GenSigSendType" SG_ 987 FLC_POS 3;
BA_ "GenSigSendType" SG_ 987 FL_WRN 3;
BA_ "GenSigSendType" SG_ 987 RR_POS 3;
BA_ "GenSigSendType" SG_ 987 RL_POS 3;
BA_ "GenSigSendType" SG_ 987 FRC_WRN 3;
BA_ "GenSigSendType" SG_ 987 RRC_POS 3;
BA_ "GenSigSendType" SG_ 987 RLC_POS 3;
BA_ "GenSigSendType" SG_ 987 FLC_WRN 3;
BA_ "GenSigSendType" SG_ 987 RR_WRN 3;
BA_ "GenSigSendType" SG_ 987 RL_WRN 3;
BA_ "GenSigSendType" SG_ 987 RRC_WRN 3;
BA_ "GenSigSendType" SG_ 987 RLC_WRN 3;
BA_ "GenSigSendType" SG_ 987 CSMUTESW 3;
BA_ "GenSigSendType" SG_ 987 CSRDISP1 3;
BA_ "GenSigSendType" SG_ 987 CSRDISP3 3;
BA_ "GenSigSendType" SG_ 987 CSR_VE3 3;
BA_ "GenSigSendType" SG_ 987 CSDETSYM 3;
BA_ "GenSigSendType" SG_ 987 CSR_TTR 3;
BA_ "GenSigSendType" SG_ 987 CS_LAMP 3;
BA_ "GenSigSendType" SG_ 988 FR_DIRT 3;
BA_ "GenSigSendType" SG_ 988 FL_DIRT 3;
BA_ "GenSigSendType" SG_ 988 FRC_DIRT 3;
BA_ "GenSigSendType" SG_ 988 FLC_DIRT 3;
BA_ "GenSigSendType" SG_ 988 RR_DIRT 3;
BA_ "GenSigSendType" SG_ 988 RL_DIRT 3;
BA_ "GenSigSendType" SG_ 988 RRC_DIRT 3;
BA_ "GenSigSendType" SG_ 988 RLC_DIRT 3;
BA_ "GenSigSendType" SG_ 988 FRS_DIRT 3;
BA_ "GenSigSendType" SG_ 988 FLS_DIRT 3;
BA_ "GenSigSendType" SG_ 988 RRS_DIRT 3;
BA_ "GenSigSendType" SG_ 988 RLS_DIRT 3;
BA_ "GenSigSendType" SG_ 988 CSR_INF1 3;
BA_ "GenSigSendType" SG_ 988 CSR_INF2 3;
BA_ "GenSigSendType" SG_ 988 PKSSINFO 3;
BA_ "GenSigSendType" SG_ 988 PKSS_VE 3;
BA_ "GenSigSendType" SG_ 988 RCDAVABL 3;
BA_ "GenSigSendType" SG_ 988 ICSAVABL 3;
BA_ "GenSigSendType" SG_ 988 CSRAVABL 3;
BA_ "GenSigSendType" SG_ 988 CAM_INF1 3;
BA_ "GenSigSendType" SG_ 988 CSR_VOL 3;
BA_ "GenSigSendType" SG_ 988 CSR_BUZ 3;
BA_ "GenSigStartValue" SG_ 637 THR_GLOB 40;
BA_ "GenSigStartValue" SG_ 637 TMO_GLOB 40;
BA_ "GenSigStartValue" SG_ 637 TTA_GLOB 40;
BA_ "GenSigStartValue" SG_ 637 RTA_GLOB 40;
BA_ "GenSigSendType" SG_ 537 BRKFRESH 3;
BA_ "GenSigSendType" SG_ 673 B_ISPTM 3;
BA_ "GenSigSendType" SG_ 673 B_GEAR 3;
BA_ "GenSigSendType" SG_ 673 B_RJTB 3;
BA_ "GenSigSendType" SG_ 980 SLCT 3;
BA_ "GenSigSendType" SG_ 734 CLDCLV 3;
BA_ "GenSigSendType" SG_ 734 CDRJTB 3;
BA_ "GenSigSendType" SG_ 734 MDRJTMSG 3;
BA_ "GenSigSendType" SG_ 734 SLCTDISP 3;
BA_ "GenSigSendType" SG_ 734 CLDCLV2 3;
BA_ "GenSigSendType" SG_ 734 EVMILRQR 3;
BA_ "GenSigSendType" SG_ 734 EVMILRQA 3;
BA_ "GenSigStartValue" SG_ 166 PMEVCR 513;
BA_ "GenSigStartValue" SG_ 1523 I_BAT_BD 65535;
BA_ "GenSigStartValue" SG_ 1523 U_BAT_BD 255;
BA_ "GenSigStartValue" SG_ 1523 PWDTY_BD 255;
BA_ "GenSigStartValue" SG_ 1523 VLO_BD 255;
BA_ "GenSigStartValue" SG_ 1523 PWIF1_BD 255;
BA_ "GenSigStartValue" SG_ 1524 T_BAT_BD 2047;
BA_ "GenSigStartValue" SG_ 1524 SOCS_BD 3;
BA_ "GenSigStartValue" SG_ 1524 SOC_BD 1023;
BA_ "GenSigStartValue" SG_ 1524 PWIF3_BD 255;
BA_ "GenSigStartValue" SG_ 1524 PWIF4_BD 255;
BA_ "GenSigStartValue" SG_ 1524 PWIF5_BD 255;
BA_ "GenSigSendType" SG_ 1417 P_DCMOD1 3;
BA_ "GenSigSendType" SG_ 1417 P_DCMOD2 3;
BA_ "GenSigSendType" SG_ 1417 P_DCMOD3 3;
BA_ "GenSigSendType" SG_ 1417 RSCLVL 3;
BA_ "GenSigSendType" SG_ 1417 P_DCMOD4 3;
BA_ "GenSigSendType" SG_ 1417 C_DCMOD3 3;
BA_ "GenSigSendType" SG_ 1417 C_DCMDE3 3;
BA_ "GenSigSendType" SG_ 1417 C_DMODEE 3;
BA_ "GenSigSendType" SG_ 1417 C_DCMDS3 3;
BA_ "GenSigSendType" SG_ 1417 C_DMODES 3;
BA_ "GenSigSendType" SG_ 1417 C_DCMDB3 3;
BA_ "GenSigSendType" SG_ 1417 C_DMODEB 3;
BA_ "GenSigSendType" SG_ 1417 VSC_DCMD 3;
BA_ "GenSigSendType" SG_ 1417 B_DMINF3 3;
BA_ "GenSigSendType" SG_ 1417 B_DMINF4 3;
BA_ "GenSigSendType" SG_ 1417 B_OMINF 3;
BA_ "GenSigStartValue" SG_ 1526 USMREQG 31;
BA_ "GenSigStartValue" SG_ 1526 USMDSTTS 31;
BA_ "GenSigStartValue" SG_ 1526 USMDSTSL 15;
BA_ "GenSigSendType" SG_ 1161 TSGN1 3;
BA_ "GenSigSendType" SG_ 1161 TSGNHLT1 3;
BA_ "GenSigSendType" SG_ 1161 SPDVAL1 3;
BA_ "GenSigSendType" SG_ 1161 SPLSGN1 3;
BA_ "GenSigSendType" SG_ 1161 SPLSGN2 3;
BA_ "GenSigSendType" SG_ 1161 TSGN2 3;
BA_ "GenSigSendType" SG_ 1161 TSGNHLT2 3;
BA_ "GenSigSendType" SG_ 1161 SPDVAL2 3;
BA_ "GenSigSendType" SG_ 1161 BZRRQ_A 3;
BA_ "GenSigSendType" SG_ 1161 TSGN3 3;
BA_ "GenSigSendType" SG_ 1161 TSGNHLT3 3;
BA_ "GenSigSendType" SG_ 1161 WRNGWAYC 3;
BA_ "GenSigSendType" SG_ 1161 SPLSGN3 3;
BA_ "GenSigSendType" SG_ 1161 SPLSGN4 3;
BA_ "GenSigSendType" SG_ 1161 TSGN4 3;
BA_ "GenSigSendType" SG_ 1161 SGNNUMH 3;
BA_ "GenSigSendType" SG_ 1161 TSGNHLT4 3;
BA_ "GenSigSendType" SG_ 1161 SPBZRQ 3;
BA_ "GenSigSendType" SG_ 1161 SGNNUMP 3;
BA_ "GenSigSendType" SG_ 1161 SGNNUMA 3;
BA_ "GenSigSendType" SG_ 1161 TLTASWAY 3;
BA_ "GenSigSendType" SG_ 1161 TRSTINFO 3;
BA_ "GenSigSendType" SG_ 1161 TLTASYST 3;
BA_ "GenSigSendType" SG_ 1161 SPLSGN5 3;
BA_ "GenSigSendType" SG_ 1161 TSGNHLT5 3;
BA_ "GenSigSendType" SG_ 1161 TSGN5 3;
BA_ "GenSigSendType" SG_ 1161 CLTRLLEN 3;
BA_ "GenSigSendType" SG_ 1163 TSREQPD 3;
BA_ "GenSigSendType" SG_ 1163 TSRMSW 3;
BA_ "GenSigSendType" SG_ 1163 OVSPNTM 3;
BA_ "GenSigSendType" SG_ 1163 NOETYEXT 3;
BA_ "GenSigSendType" SG_ 1163 NOEYNTM 3;
BA_ "GenSigSendType" SG_ 1163 OVSPVALL 3;
BA_ "GenSigSendType" SG_ 1163 REDSGEXT 3;
BA_ "GenSigSendType" SG_ 1163 RDSLNTM 3;
BA_ "GenSigSendType" SG_ 1163 OVSPVALM 3;
BA_ "GenSigSendType" SG_ 1163 NTLVLSPD 3;
BA_ "GenSigSendType" SG_ 1163 OVSPVALH 3;
BA_ "GenSigSendType" SG_ 1163 XSSPDEXT 3;
BA_ "GenSigSendType" SG_ 1163 TSRSWEXT 3;
BA_ "GenSigSendType" SG_ 1163 TSRSPU 3;
BA_ "GenSigSendType" SG_ 1163 SPBZEXT 3;
BA_ "GenSigSendType" SG_ 1163 RSACTIVE 3;
BA_ "GenSigSendType" SG_ 1163 NTFLVEXT 3;
BA_ "GenSigSendType" SG_ 1163 SPBZSTS 3;
BA_ "GenSigSendType" SG_ 594 ACCMSG2 3;
BA_ "GenSigSendType" SG_ 594 ACCMSG3 3;
BA_ "GenSigSendType" SG_ 594 ACCMSGU 3;
BA_ "GenSigSendType" SG_ 594 ACCMSPSS 3;
BA_ "GenSigSendType" SG_ 594 ACCMSG4 3;
BA_ "GenSigSendType" SG_ 594 ACCMSGV 3;
BA_ "GenSigSendType" SG_ 594 ACCBZRQ 3;
BA_ "GenSigSendType" SG_ 594 ACCCNTOB 3;
BA_ "GenSigSendType" SG_ 594 ACCMSPVL 3;
BA_ "GenSigSendType" SG_ 594 ACCMCNOB 3;
BA_ "GenSigSendType" SG_ 594 ACCMOST1 3;
BA_ "GenSigSendType" SG_ 594 ERMEFCT 3;
BA_ "GenSigSendType" SG_ 609 ACCSSOD 3;
BA_ "GenSigSendType" SG_ 609 ISAEX 3;
BA_ "GenSigSendType" SG_ 609 ACCRACEX 3;
BA_ "GenSigSendType" SG_ 609 ACCRACD 3;
BA_ "GenSigSendType" SG_ 609 ACCROSEX 3;
BA_ "GenSigSendType" SG_ 609 ACCROSD 3;
BA_ "GenSigSendType" SG_ 609 ACCACLD 3;
BA_ "GenSigSendType" SG_ 609 ACCSPEX 3;
BA_ "GenSigSendType" SG_ 609 ACCSPD 3;
BA_ "GenSigSendType" SG_ 609 ACCRSAC 3;
BA_ "GenSigSendType" SG_ 609 ACCRSACB 3;
BA_ "GenSigSendType" SG_ 609 ACCSSAG 3;
BA_ "GenSigSendType" SG_ 609 ACCSSAGB 3;
BA_ "GenSigSendType" SG_ 609 VIDEO_OK 3;
BA_ "GenSigSendType" SG_ 609 CCSMDSTA 3;
BA_ "GenSigSendType" SG_ 609 CCSMDEXT 3;
BA_ "GenSigSendType" SG_ 609 SLSSOD 3;
BA_ "GenSigSendType" SG_ 609 SLSSOEX 3;
BA_ "GenSigSendType" SG_ 609 ERMEX 3;
BA_ "GenSigSendType" SG_ 609 ACCGCRD 3;
BA_ "GenSigSendType" SG_ 609 ACCGCREX 3;
BA_ "GenSigSendType" SG_ 609 ERMLV 3;
BA_ "GenSigSendType" SG_ 609 AECOEX 3;
BA_ "GenSigSendType" SG_ 609 AECOLV 3;
BA_ "GenSigSendType" SG_ 609 SLDSEX 3;
BA_ "GenSigSendType" SG_ 609 SLDSD 3;
BA_ "GenSigSendType" SG_ 609 SLSSSEX 3;
BA_ "GenSigSendType" SG_ 609 SLSSSD 3;
BA_ "GenSigStartValue" SG_ 628 OTHTTC 4095;
BA_ "GenSigStartValue" SG_ 628 OTHRVPC 1850;
BA_ "GenSigSendType" SG_ 629 IDADSPL 3;
BA_ "GenSigSendType" SG_ 629 IDAEXIST 3;
BA_ "GenSigStartValue" SG_ 629 IDASENST 2;
BA_ "GenSigSendType" SG_ 629 IDASENST 3;
BA_ "GenSigSendType" SG_ 629 IDAONST 3;
BA_ "GenSigSendType" SG_ 629 IDADSPR 3;
BA_ "GenSigSendType" SG_ 629 IDADSPC 3;
BA_ "GenSigSendType" SG_ 629 IDABUZZ 3;
BA_ "GenSigSendType" SG_ 629 IDACAN 3;
BA_ "GenSigSendType" SG_ 629 DWREQ 3;
BA_ "GenSigSendType" SG_ 629 USMDSPPV 3;
BA_ "GenSigSendType" SG_ 629 USMDSPTL 3;
BA_ "GenSigSendType" SG_ 629 USMDSPCR 3;
BA_ "GenSigSendType" SG_ 629 USMBZ 3;
BA_ "GenSigSendType" SG_ 629 USMDSPRM 3;
BA_ "GenSigSendType" SG_ 629 USMDSPTG 3;
BA_ "GenSigSendType" SG_ 630 FCMDUST 3;
BA_ "GenSigSendType" SG_ 630 FCMTEMP 3;
BA_ "GenSigSendType" SG_ 630 FRDDUST 3;
BA_ "GenSigSendType" SG_ 630 FRDTEMP 3;
BA_ "GenSigSendType" SG_ 630 FRDTUCT 3;
BA_ "GenSigSendType" SG_ 630 TSSMALF 3;
BA_ "GenSigSendType" SG_ 630 TSSTUNA 3;
BA_ "GenSigSendType" SG_ 630 PCSAVABL 3;
BA_ "GenSigSendType" SG_ 630 ACCAVABL 3;
BA_ "GenSigSendType" SG_ 630 LTAAVABL 3;
BA_ "GenSigSendType" SG_ 630 LCAAVABL 3;
BA_ "GenSigSendType" SG_ 630 EDSSVABL 3;
BA_ "GenSigSendType" SG_ 630 RSAAVABL 3;
BA_ "GenSigSendType" SG_ 630 AHBAVABL 3;
BA_ "GenSigSendType" SG_ 630 IDAAVABL 3;
BA_ "GenSigSendType" SG_ 630 ACCERMEX 3;
BA_ "GenSigSendType" SG_ 630 TJAAVABL 3;
BA_ "GenSigSendType" SG_ 630 ERMAVABL 3;
BA_ "GenSigSendType" SG_ 630 EDSSEXST 3;
BA_ "GenSigSendType" SG_ 630 TMAVABL 3;
BA_ "GenSigSendType" SG_ 630 FCTAAVBL 3;
BA_ "GenSigSendType" SG_ 630 ADU_INF3 3;
BA_ "GenSigSendType" SG_ 630 CCAVABL 3;
BA_ "GenSigSendType" SG_ 630 CCEX 3;
BA_ "GenSigSendType" SG_ 630 ADU_INF4 3;
BA_ "GenSigSendType" SG_ 630 ADUTUNA 3;
BA_ "GenSigSendType" SG_ 630 TMNAVABL 3;
BA_ "GenSigSendType" SG_ 630 ISAAVABL 3;
BA_ "GenSigSendType" SG_ 630 LDAAVABL 3;
BA_ "GenSigSendType" SG_ 630 USMDSE 3;
BA_ "GenSigSendType" SG_ 630 USMSW 3;
BA_ "GenSigSendType" SG_ 630 ADU_INF1 3;
BA_ "GenSigSendType" SG_ 630 ADU_INF2 3;
BA_ "GenSigSendType" SG_ 630 USMONST 3;
BA_ "GenSigSendType" SG_ 630 USMEXIST 3;
BA_ "GenSigSendType" SG_ 630 SDGCONT 3;
BA_ "GenSigSendType" SG_ 630 SDGONST 3;
BA_ "GenSigSendType" SG_ 630 SDGEXIST 3;
BA_ "GenSigSendType" SG_ 630 PDAONST 3;
BA_ "GenSigSendType" SG_ 630 PDAEXIST 3;
BA_ "GenSigSendType" SG_ 630 SWSAVABL 3;
BA_ "GenSigSendType" SG_ 630 DMCAVABL 3;
BA_ "GenSigSendType" SG_ 630 DMCEXIST 3;
BA_ "GenSigSendType" SG_ 630 BSDAVABL 3;
BA_ "GenSigSendType" SG_ 630 RCTAAVBL 3;
BA_ "GenSigSendType" SG_ 630 FHLAVABL 3;
BA_ "GenSigSendType" SG_ 630 SEAAVABL 3;
BA_ "GenSigSendType" SG_ 630 ADDSAVBL 3;
BA_ "GenSigSendType" SG_ 636 TSSSPDIS 3;
BA_ "GenSigSendType" SG_ 636 TSSSPNUM 3;
BA_ "GenSigSendType" SG_ 636 TSSSPSEL 3;
BA_ "GenSigSendType" SG_ 636 TSSSPMSG 3;
BA_ "GenSigSendType" SG_ 636 TSSSPMD1 3;
BA_ "GenSigSendType" SG_ 636 TSSSPMD2 3;
BA_ "GenSigSendType" SG_ 636 TSSSPMD3 3;
BA_ "GenSigSendType" SG_ 636 TSSSPMS3 3;
BA_ "GenSigSendType" SG_ 636 TSSSPMS2 3;
BA_ "GenSigSendType" SG_ 636 TSSSPMS1 3;
BA_ "GenSigSendType" SG_ 636 TSSSPMD4 3;
BA_ "GenSigSendType" SG_ 636 TSSSPMS4 3;
BA_ "GenSigSendType" SG_ 636 TSSMDREJ 3;
BA_ "GenSigSendType" SG_ 636 TSMDAPST 3;
BA_ "GenSigSendType" SG_ 636 ACCVRAPR 3;
BA_ "GenSigSendType" SG_ 650 TSS_TID 3;
BA_ "GenSigSendType" SG_ 650 TSSFNC11 3;
BA_ "GenSigSendType" SG_ 650 TSSFNC12 3;
BA_ "GenSigSendType" SG_ 650 TSSFNC13 3;
BA_ "GenSigSendType" SG_ 650 TSSFNC14 3;
BA_ "GenSigSendType" SG_ 650 TSSFNC15 3;
BA_ "GenSigSendType" SG_ 650 TSSFNC16 3;
BA_ "GenSigSendType" SG_ 650 TSSFNC17 3;
BA_ "GenSigSendType" SG_ 650 TSSFNC21 3;
BA_ "GenSigSendType" SG_ 650 TSSFNC22 3;
BA_ "GenSigSendType" SG_ 650 TSSFNC23 3;
BA_ "GenSigSendType" SG_ 650 TSSFNC24 3;
BA_ "GenSigSendType" SG_ 650 TSSFNC25 3;
BA_ "GenSigSendType" SG_ 650 TSSFNC26 3;
BA_ "GenSigSendType" SG_ 650 TSSFNC27 3;
BA_ "GenSigSendType" SG_ 650 TSSFNC28 3;
BA_ "GenSigSendType" SG_ 650 TSSVRRES 3;
BA_ "GenSigSendType" SG_ 650 TSSOPE11 3;
BA_ "GenSigSendType" SG_ 650 TSSOPE12 3;
BA_ "GenSigSendType" SG_ 650 TSSOPE13 3;
BA_ "GenSigSendType" SG_ 650 TSSOPE14 3;
BA_ "GenSigSendType" SG_ 650 TSSOPE15 3;
BA_ "GenSigSendType" SG_ 650 TSSOPE16 3;
BA_ "GenSigSendType" SG_ 650 TSSOPE17 3;
BA_ "GenSigSendType" SG_ 650 TSSOPE21 3;
BA_ "GenSigSendType" SG_ 650 TSSOPE22 3;
BA_ "GenSigSendType" SG_ 650 TSSOPE23 3;
BA_ "GenSigSendType" SG_ 650 TSSOPE24 3;
BA_ "GenSigSendType" SG_ 650 TSSOPE25 3;
BA_ "GenSigSendType" SG_ 650 TSSOPE26 3;
BA_ "GenSigSendType" SG_ 650 TSSOPE27 3;
BA_ "GenSigSendType" SG_ 650 TSSOPE28 3;
BA_ "GenSigStartValue" SG_ 345 OTHFALD 127;
BA_ "GenSigStartValue" SG_ 345 OTHCOND 127;
BA_ "GenSigStartValue" SG_ 345 OTHLDIS 127;
BA_ "GenSigSendType" SG_ 345 OTHLANE 3;
BA_ "GenSigSendType" SG_ 527 TSSVOI05 3;
BA_ "GenSigSendType" SG_ 527 TSSVOI06 3;
BA_ "GenSigSendType" SG_ 527 TSSVOI01 3;
BA_ "GenSigSendType" SG_ 527 TSSVOI02 3;
BA_ "GenSigSendType" SG_ 527 TSSVOI08 3;
BA_ "GenSigSendType" SG_ 527 DM_DISPC 3;
BA_ "GenSigSendType" SG_ 601 DREC_S 3;
BA_ "GenSigSendType" SG_ 601 LDAACTL 3;
BA_ "GenSigSendType" SG_ 601 LDAACTR 3;
BA_ "GenSigSendType" SG_ 168 AVSTRGR 3;
BA_ "GenSigSendType" SG_ 168 PBATRGR 3;
BA_ "GenSigStartValue" SG_ 277 MGR_DISP 1;
BA_ "GenSigSendType" SG_ 1172 LVNEQPD 3;
BA_ "GenSigSendType" SG_ 1172 LVNINDF 3;
BA_ "GenSigSendType" SG_ 1172 LVNBUZF 3;
BA_ "GenSigSendType" SG_ 1172 TMNSEQPD 3;
BA_ "GenSigSendType" SG_ 1172 TMNSIND 3;
BA_ "GenSigSendType" SG_ 1172 TMNVSET 3;
BA_ "GenSigSendType" SG_ 1172 TMNSSET 3;
BA_ "GenSigSendType" SG_ 1321 SPBZ_OPE 3;
BA_ "GenSigSendType" SG_ 589 VRAPMSWS 3;
BA_ "GenSigSendType" SG_ 855 METSPDIS 3;
BA_ "GenSigSendType" SG_ 855 LCASGMSW 3;
BA_ "GenSigSendType" SG_ 855 LCASGAPR 3;
BA_ "GenSigSendType" SG_ 855 IDAMSW 3;
BA_ "GenSigSendType" SG_ 855 IDASESW 3;
BA_ "GenSigSendType" SG_ 855 BSD_SMSB 3;
BA_ "GenSigSendType" SG_ 855 BSD_SMSS 3;
BA_ "GenSigSendType" SG_ 855 RSR_TIM 3;
BA_ "GenSigSendType" SG_ 855 DOAM_SW 3;
BA_ "GenSigSendType" SG_ 855 PKSSVOL 3;
BA_ "GenSigSendType" SG_ 855 LDASW 3;
BA_ "GenSigSendType" SG_ 855 DOAM_TIM 3;
BA_ "GenSigSendType" SG_ 855 BSMM_ILV 3;
BA_ "GenSigSendType" SG_ 855 RTAN_TIM 3;
BA_ "GenSigSendType" SG_ 855 RTAN_MSW 3;
BA_ "GenSigSendType" SG_ 855 PLUSSW 3;
BA_ "GenSigSendType" SG_ 855 SDGMSW 3;
BA_ "GenSigSendType" SG_ 855 PDAMSW 3;
BA_ "GenSigSendType" SG_ 855 RSA_NEM 3;
BA_ "GenSigSendType" SG_ 855 RSA_LSM 3;
BA_ "GenSigSendType" SG_ 855 PMARSW 3;
BA_ "GenSigSendType" SG_ 855 ADDS_MSW 3;
BA_ "GenSigSendType" SG_ 855 LDAAMSW 3;
BA_ "GenSigSendType" SG_ 855 TMNVSW 3;
BA_ "GenSigSendType" SG_ 855 TMNSSW 3;
BA_ "GenSigSendType" SG_ 855 DM_SW_A2 3;
BA_ "GenSigSendType" SG_ 855 DISSUISW 3;
BA_ "GenSigSendType" SG_ 855 SLDSSW 3;
BA_ "GenSigSendType" SG_ 855 SLSSSSW 3;
BA_ "GenSigSendType" SG_ 855 LTASSWOP 3;
BA_ "GenSigSendType" SG_ 855 HMIAMBOP 3;
BA_ "GenSigSendType" SG_ 855 ADINITSW 3;
BA_ "GenSigSendType" SG_ 855 ADSAFESW 3;
BA_ "GenSigSendType" SG_ 855 ADALOFSW 3;
BA_ "GenSigSendType" SG_ 855 ADMUTESW 3;
BA_ "GenSigSendType" SG_ 855 ADMDSTSW 3;
BA_ "GenSigSendType" SG_ 855 STRSWAP 3;
BA_ "GenSigSendType" SG_ 855 USMSESW 3;
BA_ "GenSigSendType" SG_ 855 SDGSESW 3;
BA_ "GenSigSendType" SG_ 855 ADADDRSW 3;
BA_ "GenSigSendType" SG_ 855 ADOTASSW 3;
BA_ "GenSigSendType" SG_ 855 ADSTMUSW 3;
BA_ "GenSigSendType" SG_ 855 ADAUNFSW 3;
BA_ "GenSigSendType" SG_ 855 ADNTLVSW 3;
BA_ "GenSigSendType" SG_ 855 ADDSLVSW 3;
BA_ "GenSigSendType" SG_ 855 ADVOCTSW 3;
BA_ "GenSigSendType" SG_ 855 ADSLDSSW 3;
BA_ "GenSigSendType" SG_ 855 ADDMCRSW 3;
BA_ "GenSigSendType" SG_ 855 ADSEGDSW 3;
BA_ "GenSigSendType" SG_ 855 ADSVSSSW 3;
BA_ "GenSigSendType" SG_ 855 ADCVVSSW 3;
BA_ "GenSigSendType" SG_ 855 AECOSWBB 3;
BA_ "GenSigSendType" SG_ 855 ACCSSOSW 3;
BA_ "GenSigSendType" SG_ 855 ACCRACSW 3;
BA_ "GenSigSendType" SG_ 855 ACCROSSW 3;
BA_ "GenSigSendType" SG_ 855 AHSACTSW 3;
BA_ "GenSigSendType" SG_ 855 AHBACTSW 3;
BA_ "GenSigSendType" SG_ 855 ACCACLSW 3;
BA_ "GenSigSendType" SG_ 855 ACCSPMSW 3;
BA_ "GenSigSendType" SG_ 855 AECOSW 3;
BA_ "GenSigSendType" SG_ 855 USMMAIN 3;
BA_ "GenSigSendType" SG_ 855 SLSSOSW 3;
BA_ "GenSigSendType" SG_ 855 METMDSEL 3;
BA_ "GenSigSendType" SG_ 855 ACCDSTSW 3;
BA_ "GenSigSendType" SG_ 855 DOTICSTS 3;
BA_ "GenSigSendType" SG_ 855 CTAMSW 3;
BA_ "GenSigSendType" SG_ 855 ACCGCRSW 3;
BA_ "GenSigSendType" SG_ 855 METMSPDI 3;
BA_ "GenSigSendType" SG_ 855 RTWMSW 3;
BA_ "GenSigSendType" SG_ 855 AHSSDESW 3;
BA_ "GenSigSendType" SG_ 855 AHSSWVSW 3;
BA_ "GenSigSendType" SG_ 855 METMDREJ 3;
BA_ "GenSigSendType" SG_ 855 CCSMDMSW 3;
BA_ "GenSigSendType" SG_ 855 ERMSW 3;
BA_ "GenSigSendType" SG_ 855 TRA_SW 3;
BA_ "GenSigSendType" SG_ 855 TRLC_YN 3;
BA_ "GenSigStartValue" SG_ 756 AB 3;
BA_ "GenSigSendType" SG_ 756 AB 3;
BA_ "GenSigStartValue" SG_ 756 PUH_FLG 1;
BA_ "GenSigSendType" SG_ 756 PDS_WL 3;
BA_ "GenSigSendType" SG_ 560 MV_FL 3;
BA_ "GenSigSendType" SG_ 560 MV_FR 3;
BA_ "GenSigSendType" SG_ 560 MV_RL 3;
BA_ "GenSigSendType" SG_ 560 MV_RR 3;
BA_ "GenSigSendType" SG_ 560 MV_FLS 3;
BA_ "GenSigSendType" SG_ 560 MV_FRS 3;
BA_ "GenSigSendType" SG_ 560 MV_RLS 3;
BA_ "GenSigSendType" SG_ 560 MV_RRS 3;
BA_ "GenSigSendType" SG_ 560 MV_FC 3;
BA_ "GenSigSendType" SG_ 560 MV_RC 3;
BA_ "GenSigSendType" SG_ 560 FRS_POS 3;
BA_ "GenSigSendType" SG_ 560 FLS_POS 3;
BA_ "GenSigSendType" SG_ 560 FRS_WRN 3;
BA_ "GenSigSendType" SG_ 560 RRS_POS 3;
BA_ "GenSigSendType" SG_ 560 RLS_POS 3;
BA_ "GenSigSendType" SG_ 560 FLS_WRN 3;
BA_ "GenSigSendType" SG_ 560 RRS_WRN 3;
BA_ "GenSigSendType" SG_ 560 RLS_WRN 3;
BA_ "GenSigSendType" SG_ 475 MSG_SBWF 3;
BA_ "GenSigSendType" SG_ 475 MSG_LBAT 3;
BA_ "GenSigSendType" SG_ 475 MSG_PREQ 3;
BA_ "GenSigSendType" SG_ 475 MSG_PSWF 3;
BA_ "GenSigSendType" SG_ 475 MSG_ACTF 3;
BA_ "GenSigSendType" SG_ 475 VNHLDEN 3;
BA_ "GenSigSendType" SG_ 475 VNHLDST 3;
BA_ "GenSigSendType" SG_ 766 AVSMINF 3;
BA_ "GenSigSendType" SG_ 766 AVSNI 3;
BA_ "GenSigSendType" SG_ 766 DLR_HSID 3;
BA_ "GenSigSendType" SG_ 766 LAR_HS 3;
BA_ "GenSigSendType" SG_ 766 STBLMP 3;
BA_ "GenSigSendType" SG_ 766 KSSMINF 3;
BA_ "GenSigStartValue" SG_ 766 KSSEXT 1;
BA_ "GenSigSendType" SG_ 766 LKSS0 3;
BA_ "GenSigSendType" SG_ 766 ASTBMINF 3;
BA_ "GenSigSendType" SG_ 672 TRABUZ 3;
BA_ "GenSigSendType" SG_ 672 TCSL_ID 3;
BA_ "GenSigSendType" SG_ 672 ATD_DEC 3;
BA_ "GenSigSendType" SG_ 672 TCSL_TTP 3;
BA_ "GenSigSendType" SG_ 672 TCSL_TW 3;
BA_ "GenSigSendType" SG_ 672 TCSL_MI 3;
